VERSION ""

NS_ :

BS_:

BU_: VCM SCIM IC CCM

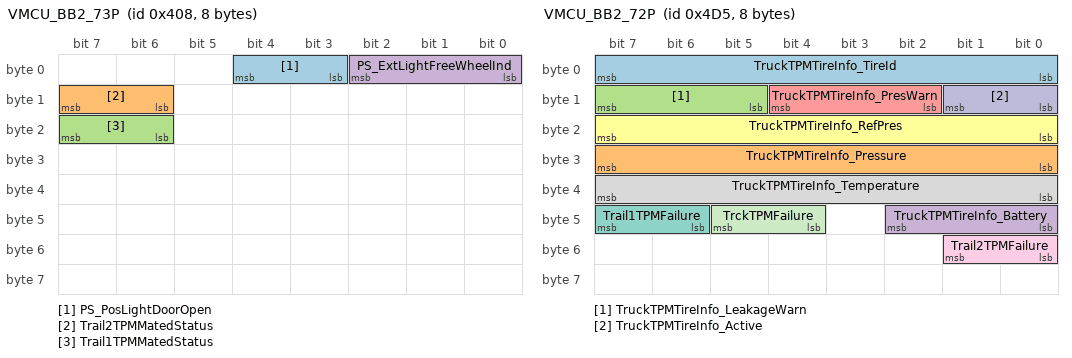
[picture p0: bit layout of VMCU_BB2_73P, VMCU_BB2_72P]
BO_ 1032 VMCU_BB2_73P: 8 VCM
 SG_ PS_PosLightDoorOpen : 3|2@1+ (1,0) [0|0] ""  IC
 SG_ Trail2TPMMatedStatus : 14|2@1+ (1,0) [0|0] ""  IC
 SG_ Trail1TPMMatedStatus : 22|2@1+ (1,0) [0|0] ""  IC
 SG_ PS_ExtLightFreeWheelInd : 0|3@1+ (1,0) [0|0] ""  IC

BO_ 1237 VMCU_BB2_72P: 8 VCM
 SG_ TruckTPMTireInfo_TireId : 0|8@1+ (1,0) [0|255] "NotApplicable"  IC
 SG_ TruckTPMTireInfo_Pressure : 24|8@1+ (10,0) [0|2550] "kPa"  IC
 SG_ TruckTPMTireInfo_LeakageWarn : 13|3@1+ (1,0) [0|0] ""  IC
 SG_ TruckTPMTireInfo_Battery : 40|3@1+ (1,0) [0|0] ""  IC
 SG_ TruckTPMTireInfo_PresWarn : 10|3@1+ (1,0) [0|0] ""  IC
 SG_ TruckTPMTireInfo_RefPres : 16|8@1+ (10,0) [0|2550] "kPa"  IC
 SG_ Trail1TPMFailure : 46|2@1+ (1,0) [0|0] ""  IC
 SG_ TruckTPMTireInfo_Temperature : 32|8@1+ (1,-50) [-50|205] "DegreeC"  IC
 SG_ Trail2TPMFailure : 48|2@1+ (1,0) [0|0] ""  IC
 SG_ TruckTPMTireInfo_Active : 8|2@1+ (1,0) [0|0] ""  IC
 SG_ TrckTPMFailure : 44|2@1+ (1,0) [0|0] ""  IC

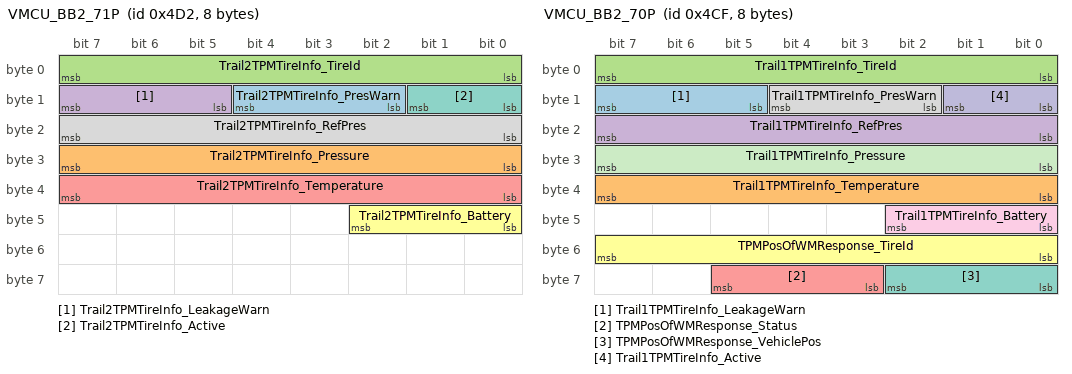
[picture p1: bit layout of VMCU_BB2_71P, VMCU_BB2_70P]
BO_ 1234 VMCU_BB2_71P: 8 VCM
 SG_ Trail2TPMTireInfo_PresWarn : 10|3@1+ (1,0) [0|0] ""  IC
 SG_ Trail2TPMTireInfo_Pressure : 24|8@1+ (10,0) [0|2550] "kPa"  IC
 SG_ Trail2TPMTireInfo_TireId : 0|8@1+ (1,0) [0|255] "NotApplicable"  IC
 SG_ Trail2TPMTireInfo_LeakageWarn : 13|3@1+ (1,0) [0|0] ""  IC
 SG_ Trail2TPMTireInfo_Temperature : 32|8@1+ (1,-50) [-50|205] "DegreeC"  IC
 SG_ Trail2TPMTireInfo_Battery : 40|3@1+ (1,0) [0|0] ""  IC
 SG_ Trail2TPMTireInfo_Active : 8|2@1+ (1,0) [0|0] ""  IC
 SG_ Trail2TPMTireInfo_RefPres : 16|8@1+ (10,0) [0|2550] "kPa"  IC

BO_ 1231 VMCU_BB2_70P: 8 VCM
 SG_ Trail1TPMTireInfo_LeakageWarn : 13|3@1+ (1,0) [0|0] ""  IC
 SG_ Trail1TPMTireInfo_Temperature : 32|8@1+ (1,-50) [-50|205] "DegreeC"  IC
 SG_ Trail1TPMTireInfo_TireId : 0|8@1+ (1,0) [0|255] "NotApplicable"  IC
 SG_ Trail1TPMTireInfo_RefPres : 16|8@1+ (10,0) [0|2550] "kPa"  IC
 SG_ TPMPosOfWMResponse_Status : 59|3@1+ (1,0) [0|0] ""  IC
 SG_ TPMPosOfWMResponse_TireId : 48|8@1+ (1,0) [0|255] "NotApplicable"  IC
 SG_ TPMPosOfWMResponse_VehiclePos : 56|3@1+ (1,0) [0|0] ""  IC
 SG_ Trail1TPMTireInfo_PresWarn : 10|3@1+ (1,0) [0|0] ""  IC
 SG_ Trail1TPMTireInfo_Battery : 40|3@1+ (1,0) [0|0] ""  IC
 SG_ Trail1TPMTireInfo_Active : 8|2@1+ (1,0) [0|0] ""  IC
 SG_ Trail1TPMTireInfo_Pressure : 24|8@1+ (10,0) [0|2550] "kPa"  IC

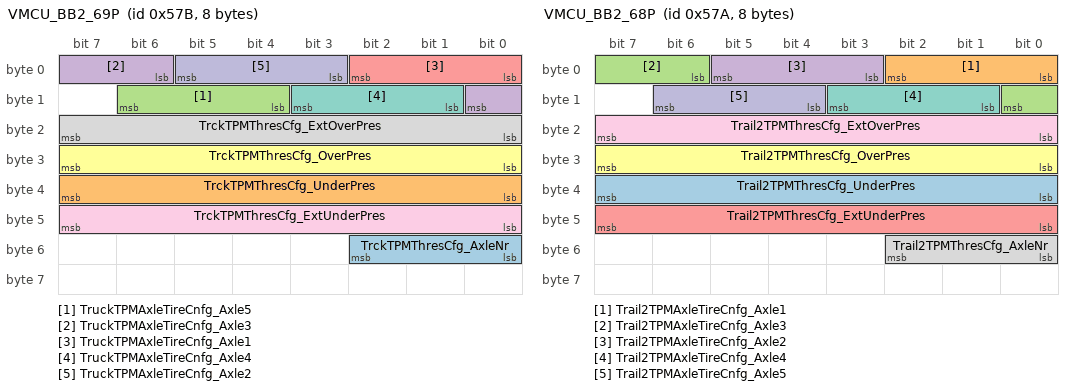
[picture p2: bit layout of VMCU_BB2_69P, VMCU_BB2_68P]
BO_ 1403 VMCU_BB2_69P: 8 VCM
 SG_ TrckTPMThresCfg_AxleNr : 48|3@1+ (1,0) [0|0] ""  IC
 SG_ TrckTPMThresCfg_UnderPres : 32|8@1+ (1,-125) [-125|130] "Percent"  IC
 SG_ TruckTPMAxleTireCnfg_Axle5 : 12|3@1+ (1,0) [0|0] ""  IC
 SG_ TruckTPMAxleTireCnfg_Axle3 : 6|3@1+ (1,0) [0|0] ""  IC
 SG_ TruckTPMAxleTireCnfg_Axle1 : 0|3@1+ (1,0) [0|0] ""  IC
 SG_ TrckTPMThresCfg_OverPres : 24|8@1+ (1,-125) [-125|130] "Percent"  IC
 SG_ TruckTPMAxleTireCnfg_Axle4 : 9|3@1+ (1,0) [0|0] ""  IC
 SG_ TrckTPMThresCfg_ExtOverPres : 16|8@1+ (1,-125) [-125|130] "Percent"  IC
 SG_ TrckTPMThresCfg_ExtUnderPres : 40|8@1+ (1,-125) [-125|130] "Percent"  IC
 SG_ TruckTPMAxleTireCnfg_Axle2 : 3|3@1+ (1,0) [0|0] ""  IC

BO_ 1402 VMCU_BB2_68P: 8 VCM
 SG_ Trail2TPMThresCfg_UnderPres : 32|8@1+ (1,-125) [-125|130] "Percent"  IC
 SG_ Trail2TPMAxleTireCnfg_Axle1 : 0|3@1+ (1,0) [0|0] ""  IC
 SG_ Trail2TPMAxleTireCnfg_Axle3 : 6|3@1+ (1,0) [0|0] ""  IC
 SG_ Trail2TPMAxleTireCnfg_Axle2 : 3|3@1+ (1,0) [0|0] ""  IC
 SG_ Trail2TPMThresCfg_ExtUnderPres : 40|8@1+ (1,-125) [-125|130] "Percent"  IC
 SG_ Trail2TPMThresCfg_OverPres : 24|8@1+ (1,-125) [-125|130] "Percent"  IC
 SG_ Trail2TPMAxleTireCnfg_Axle4 : 9|3@1+ (1,0) [0|0] ""  IC
 SG_ Trail2TPMThresCfg_AxleNr : 48|3@1+ (1,0) [0|0] ""  IC
 SG_ Trail2TPMThresCfg_ExtOverPres : 16|8@1+ (1,-125) [-125|130] "Percent"  IC
 SG_ Trail2TPMAxleTireCnfg_Axle5 : 12|3@1+ (1,0) [0|0] ""  IC

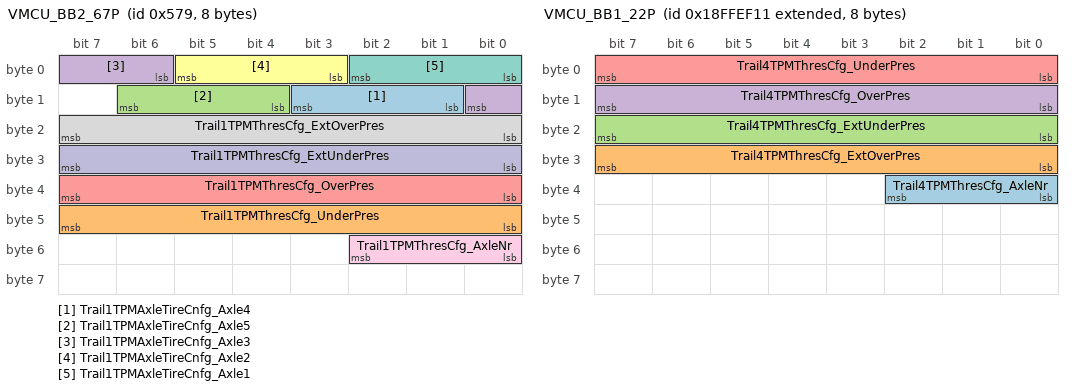
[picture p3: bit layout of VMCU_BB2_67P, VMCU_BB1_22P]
BO_ 1401 VMCU_BB2_67P: 8 VCM
 SG_ Trail1TPMAxleTireCnfg_Axle4 : 9|3@1+ (1,0) [0|0] ""  IC
 SG_ Trail1TPMThresCfg_UnderPres : 40|8@1+ (1,-125) [-125|130] "Percent"  IC
 SG_ Trail1TPMAxleTireCnfg_Axle5 : 12|3@1+ (1,0) [0|0] ""  IC
 SG_ Trail1TPMAxleTireCnfg_Axle3 : 6|3@1+ (1,0) [0|0] ""  IC
 SG_ Trail1TPMThresCfg_OverPres : 32|8@1+ (1,-125) [-125|130] "Percent"  IC
 SG_ Trail1TPMAxleTireCnfg_Axle2 : 3|3@1+ (1,0) [0|0] ""  IC
 SG_ Trail1TPMAxleTireCnfg_Axle1 : 0|3@1+ (1,0) [0|0] ""  IC
 SG_ Trail1TPMThresCfg_ExtOverPres : 16|8@1+ (1,-125) [-125|130] "Percent"  IC
 SG_ Trail1TPMThresCfg_AxleNr : 48|3@1+ (1,0) [0|0] ""  IC
 SG_ Trail1TPMThresCfg_ExtUnderPres : 24|8@1+ (1,-125) [-125|130] "Percent"  IC

BO_ 2566909713 VMCU_BB1_22P: 8 VCM
 SG_ Trail4TPMThresCfg_AxleNr : 32|3@1+ (1,0) [0|0] ""  IC
 SG_ Trail4TPMThresCfg_ExtOverPres : 24|8@1+ (1,-125) [-125|130] "Percent"  IC
 SG_ Trail4TPMThresCfg_ExtUnderPres : 16|8@1+ (1,-125) [-125|130] "Percent"  IC
 SG_ Trail4TPMThresCfg_OverPres : 8|8@1+ (1,-125) [-125|130] "Percent"  IC
 SG_ Trail4TPMThresCfg_UnderPres : 0|8@1+ (1,-125) [-125|130] "Percent"  IC

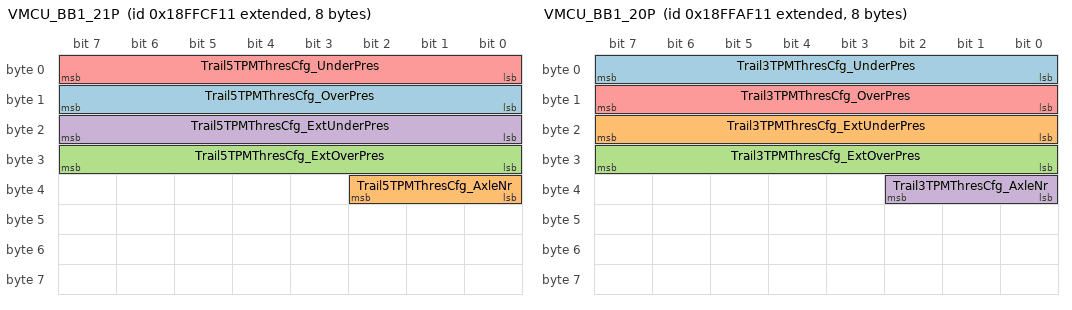
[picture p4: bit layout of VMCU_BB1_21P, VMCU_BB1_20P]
BO_ 2566901521 VMCU_BB1_21P: 8 VCM
 SG_ Trail5TPMThresCfg_OverPres : 8|8@1+ (1,-125) [-125|130] "Percent"  IC
 SG_ Trail5TPMThresCfg_AxleNr : 32|3@1+ (1,0) [0|0] ""  IC
 SG_ Trail5TPMThresCfg_ExtOverPres : 24|8@1+ (1,-125) [-125|130] "Percent"  IC
 SG_ Trail5TPMThresCfg_ExtUnderPres : 16|8@1+ (1,-125) [-125|130] "Percent"  IC
 SG_ Trail5TPMThresCfg_UnderPres : 0|8@1+ (1,-125) [-125|130] "Percent"  IC

BO_ 2566893329 VMCU_BB1_20P: 8 VCM
 SG_ Trail3TPMThresCfg_UnderPres : 0|8@1+ (1,-125) [-125|130] "Percent"  IC
 SG_ Trail3TPMThresCfg_ExtUnderPres : 16|8@1+ (1,-125) [-125|130] "Percent"  IC
 SG_ Trail3TPMThresCfg_ExtOverPres : 24|8@1+ (1,-125) [-125|130] "Percent"  IC
 SG_ Trail3TPMThresCfg_AxleNr : 32|3@1+ (1,0) [0|0] ""  IC
 SG_ Trail3TPMThresCfg_OverPres : 8|8@1+ (1,-125) [-125|130] "Percent"  IC

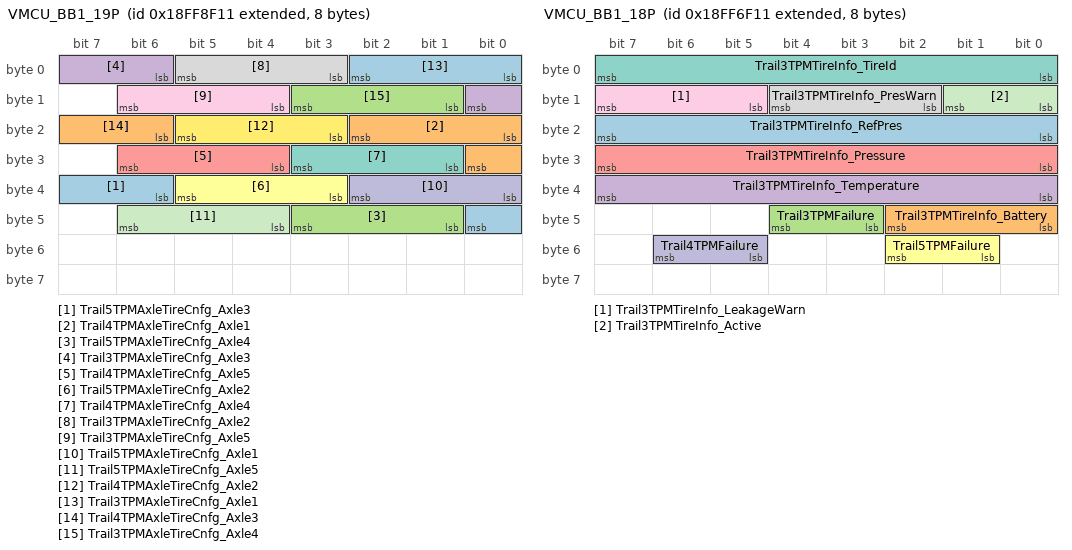
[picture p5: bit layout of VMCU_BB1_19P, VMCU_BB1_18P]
BO_ 2566885137 VMCU_BB1_19P: 8 VCM
 SG_ Trail5TPMAxleTireCnfg_Axle3 : 38|3@1+ (1,0) [0|0] ""  IC
 SG_ Trail4TPMAxleTireCnfg_Axle1 : 16|3@1+ (1,0) [0|0] ""  IC
 SG_ Trail5TPMAxleTireCnfg_Axle4 : 41|3@1+ (1,0) [0|0] ""  IC
 SG_ Trail3TPMAxleTireCnfg_Axle3 : 6|3@1+ (1,0) [0|0] ""  IC
 SG_ Trail4TPMAxleTireCnfg_Axle5 : 28|3@1+ (1,0) [0|0] ""  IC
 SG_ Trail5TPMAxleTireCnfg_Axle2 : 35|3@1+ (1,0) [0|0] ""  IC
 SG_ Trail4TPMAxleTireCnfg_Axle4 : 25|3@1+ (1,0) [0|0] ""  IC
 SG_ Trail3TPMAxleTireCnfg_Axle2 : 3|3@1+ (1,0) [0|0] ""  IC
 SG_ Trail3TPMAxleTireCnfg_Axle5 : 12|3@1+ (1,0) [0|0] ""  IC
 SG_ Trail5TPMAxleTireCnfg_Axle1 : 32|3@1+ (1,0) [0|0] ""  IC
 SG_ Trail5TPMAxleTireCnfg_Axle5 : 44|3@1+ (1,0) [0|0] ""  IC
 SG_ Trail4TPMAxleTireCnfg_Axle2 : 19|3@1+ (1,0) [0|0] ""  IC
 SG_ Trail3TPMAxleTireCnfg_Axle1 : 0|3@1+ (1,0) [0|0] ""  IC
 SG_ Trail4TPMAxleTireCnfg_Axle3 : 22|3@1+ (1,0) [0|0] ""  IC
 SG_ Trail3TPMAxleTireCnfg_Axle4 : 9|3@1+ (1,0) [0|0] ""  IC

BO_ 2566876945 VMCU_BB1_18P: 8 VCM
 SG_ Trail3TPMTireInfo_RefPres : 16|8@1+ (10,0) [0|2550] "kPa"  IC
 SG_ Trail3TPMTireInfo_Battery : 40|3@1+ (1,0) [0|0] ""  IC
 SG_ Trail3TPMFailure : 43|2@1+ (1,0) [0|0] ""  IC
 SG_ Trail3TPMTireInfo_Temperature : 32|8@1+ (1,-50) [-50|205] "DegreeC"  IC
 SG_ Trail3TPMTireInfo_Pressure : 24|8@1+ (10,0) [0|2550] "kPa"  IC
 SG_ Trail5TPMFailure : 49|2@1+ (1,0) [0|0] ""  IC
 SG_ Trail3TPMTireInfo_TireId : 0|8@1+ (1,0) [0|255] "NotApplicable"  IC
 SG_ Trail3TPMTireInfo_PresWarn : 10|3@1+ (1,0) [0|0] ""  IC
 SG_ Trail3TPMTireInfo_LeakageWarn : 13|3@1+ (1,0) [0|0] ""  IC
 SG_ Trail4TPMFailure : 53|2@1+ (1,0) [0|0] ""  IC
 SG_ Trail3TPMTireInfo_Active : 8|2@1+ (1,0) [0|0] ""  IC

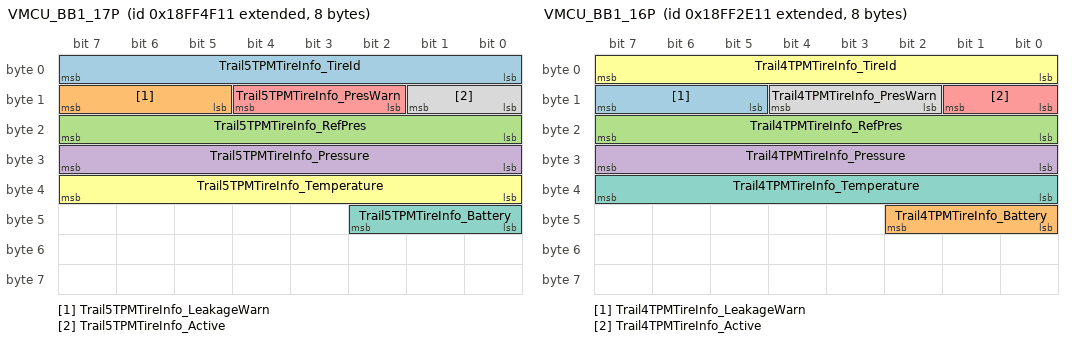
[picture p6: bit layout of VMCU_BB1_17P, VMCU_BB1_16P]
BO_ 2566868753 VMCU_BB1_17P: 8 VCM
 SG_ Trail5TPMTireInfo_TireId : 0|8@1+ (1,0) [0|255] "NotApplicable"  IC
 SG_ Trail5TPMTireInfo_LeakageWarn : 13|3@1+ (1,0) [0|0] ""  IC
 SG_ Trail5TPMTireInfo_RefPres : 16|8@1+ (10,0) [0|2550] "kPa"  IC
 SG_ Trail5TPMTireInfo_Pressure : 24|8@1+ (10,0) [0|2550] "kPa"  IC
 SG_ Trail5TPMTireInfo_PresWarn : 10|3@1+ (1,0) [0|0] ""  IC
 SG_ Trail5TPMTireInfo_Temperature : 32|8@1+ (1,-50) [-50|205] "DegreeC"  IC
 SG_ Trail5TPMTireInfo_Battery : 40|3@1+ (1,0) [0|0] ""  IC
 SG_ Trail5TPMTireInfo_Active : 8|2@1+ (1,0) [0|0] ""  IC

BO_ 2566860305 VMCU_BB1_16P: 8 VCM
 SG_ Trail4TPMTireInfo_LeakageWarn : 13|3@1+ (1,0) [0|0] ""  IC
 SG_ Trail4TPMTireInfo_Battery : 40|3@1+ (1,0) [0|0] ""  IC
 SG_ Trail4TPMTireInfo_RefPres : 16|8@1+ (10,0) [0|2550] "kPa"  IC
 SG_ Trail4TPMTireInfo_Pressure : 24|8@1+ (10,0) [0|2550] "kPa"  IC
 SG_ Trail4TPMTireInfo_Active : 8|2@1+ (1,0) [0|0] ""  IC
 SG_ Trail4TPMTireInfo_TireId : 0|8@1+ (1,0) [0|255] "NotApplicable"  IC
 SG_ Trail4TPMTireInfo_Temperature : 32|8@1+ (1,-50) [-50|205] "DegreeC"  IC
 SG_ Trail4TPMTireInfo_PresWarn : 10|3@1+ (1,0) [0|0] ""  IC

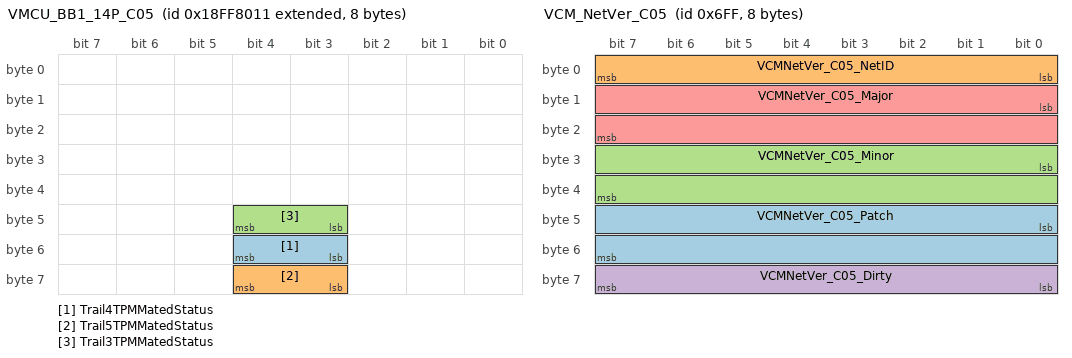
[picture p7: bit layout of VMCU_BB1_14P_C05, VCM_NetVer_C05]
BO_ 2566881297 VMCU_BB1_14P_C05: 8 VCM
 SG_ Trail4TPMMatedStatus : 51|2@1+ (1,0) [0|0] ""  IC
 SG_ Trail5TPMMatedStatus : 59|2@1+ (1,0) [0|0] ""  IC
 SG_ Trail3TPMMatedStatus : 43|2@1+ (1,0) [0|0] ""  IC

BO_ 1791 VCM_NetVer_C05: 8 VCM
 SG_ VCMNetVer_C05_Patch : 40|16@1+ (1,0) [0|65535] "Not Applicable" Vector__XXX
 SG_ VCMNetVer_C05_NetID : 0|8@1+ (1,0) [0|255] "NotApplicable" Vector__XXX
 SG_ VCMNetVer_C05_Minor : 24|16@1+ (1,0) [0|65535] "Not Applicable" Vector__XXX
 SG_ VCMNetVer_C05_Dirty : 56|8@1+ (1,0) [0|255] "NotApplicable" Vector__XXX
 SG_ VCMNetVer_C05_Major : 8|16@1+ (1,0) [0|65535] "Not Applicable" Vector__XXX

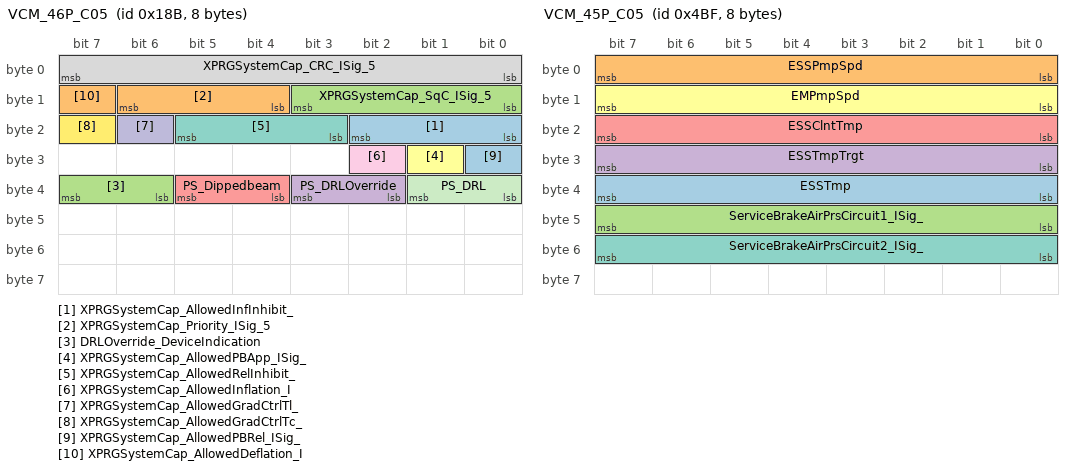
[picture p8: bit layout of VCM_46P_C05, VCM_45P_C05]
BO_ 395 VCM_46P_C05: 8 VCM
 SG_ XPRGSystemCap_AllowedInfInhibit_ : 16|3@1+ (1,0) [0|0] ""  IC
 SG_ XPRGSystemCap_Priority_ISig_5 : 12|3@1+ (1,0) [0|0] ""  IC
 SG_ DRLOverride_DeviceIndication : 38|2@1+ (1,0) [0|0] ""  SCIM
 SG_ PS_DRLOverride : 34|2@1+ (1,0) [0|0] ""  IC
 SG_ PS_Dippedbeam : 36|2@1+ (1,0) [0|0] ""  IC
 SG_ XPRGSystemCap_AllowedPBApp_ISig_ : 25|1@1+ (1,0) [0|0] ""  IC
 SG_ XPRGSystemCap_AllowedRelInhibit_ : 19|3@1+ (1,0) [0|0] ""  IC
 SG_ XPRGSystemCap_CRC_ISig_5 : 0|8@1+ (1,0) [0|255] ""  IC
 SG_ XPRGSystemCap_AllowedInflation_I : 26|1@1+ (1,0) [0|0] ""  IC
 SG_ XPRGSystemCap_AllowedGradCtrlTl_ : 22|1@1+ (1,0) [0|0] ""  IC
 SG_ PS_DRL : 32|2@1+ (1,0) [0|0] ""  IC
 SG_ XPRGSystemCap_AllowedGradCtrlTc_ : 23|1@1+ (1,0) [0|0] ""  IC
 SG_ XPRGSystemCap_AllowedPBRel_ISig_ : 24|1@1+ (1,0) [0|0] ""  IC
 SG_ XPRGSystemCap_AllowedDeflation_I : 15|1@1+ (1,0) [0|0] ""  IC
 SG_ XPRGSystemCap_SqC_ISig_5 : 8|4@1+ (1,0) [0|14] "NotApplicable"  IC

BO_ 1215 VCM_45P_C05: 8 VCM
 SG_ ESSTmp : 32|8@1+ (0.5,-25) [-25|102.5] "DegreeC"  CCM
 SG_ ESSPmpSpd : 0|8@1+ (1,0) [0|255] "Percent"  CCM
 SG_ ServiceBrakeAirPrsCircuit1_ISig_ : 40|8@1+ (8,0) [0|2040] "kPa"  IC
 SG_ ESSTmpTrgt : 24|8@1+ (1,0) [0|255] "DegreeC"  CCM
 SG_ ESSClntTmp : 16|8@1+ (0.5,-25) [-25|102.5] "DegreeC"  CCM
 SG_ EMPmpSpd : 8|8@1+ (1,0) [0|255] "Percent"  CCM
 SG_ ServiceBrakeAirPrsCircuit2_ISig_ : 48|8@1+ (8,0) [0|2040] "kPa"  IC

BO_ 907 VCM_44P_C05: 8 VCM
 SG_ Trailer5GeometricData_Index_ISig : 8|8@1+ (1,0) [0|0] ""  IC
 SG_ Trailer5GeometricData_Content_IS : 0|8@1+ (1,0) [0|255] ""  IC

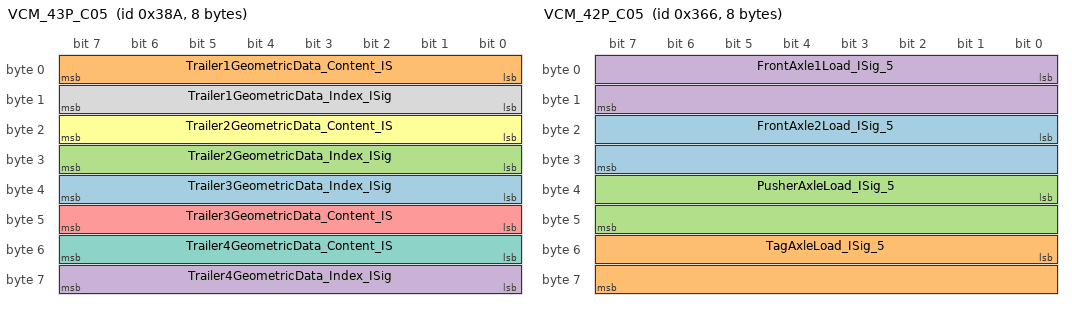
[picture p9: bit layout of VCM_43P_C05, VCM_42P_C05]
BO_ 906 VCM_43P_C05: 8 VCM
 SG_ Trailer3GeometricData_Index_ISig : 32|8@1+ (1,0) [0|0] ""  IC
 SG_ Trailer1GeometricData_Content_IS : 0|8@1+ (1,0) [0|255] ""  IC
 SG_ Trailer2GeometricData_Index_ISig : 24|8@1+ (1,0) [0|0] ""  IC
 SG_ Trailer4GeometricData_Index_ISig : 56|8@1+ (1,0) [0|0] ""  IC
 SG_ Trailer3GeometricData_Content_IS : 40|8@1+ (1,0) [0|255] ""  IC
 SG_ Trailer2GeometricData_Content_IS : 16|8@1+ (1,0) [0|255] ""  IC
 SG_ Trailer4GeometricData_Content_IS : 48|8@1+ (1,0) [0|255] ""  IC
 SG_ Trailer1GeometricData_Index_ISig : 8|8@1+ (1,0) [0|0] ""  IC

BO_ 870 VCM_42P_C05: 8 VCM
 SG_ FrontAxle2Load_ISig_5 : 16|16@1+ (0.5,0) [0|32767.5] "kg"  IC
 SG_ TagAxleLoad_ISig_5 : 48|16@1+ (0.5,0) [0|32767.5] "kg"  IC
 SG_ PusherAxleLoad_ISig_5 : 32|16@1+ (0.5,0) [0|32767.5] "kg"  IC
 SG_ FrontAxle1Load_ISig_5 : 0|16@1+ (0.5,0) [0|32767.5] "kg"  IC

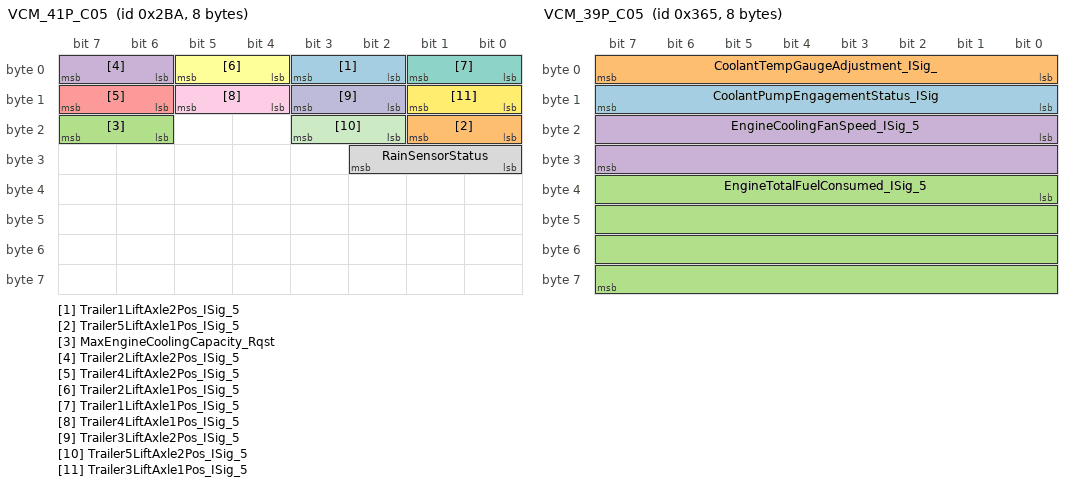
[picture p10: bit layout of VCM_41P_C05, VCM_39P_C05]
BO_ 698 VCM_41P_C05: 8 VCM
 SG_ Trailer1LiftAxle2Pos_ISig_5 : 2|2@1+ (1,0) [0|0] ""  IC
 SG_ Trailer5LiftAxle1Pos_ISig_5 : 16|2@1+ (1,0) [0|0] ""  IC
 SG_ MaxEngineCoolingCapacity_Rqst : 22|2@1+ (1,0) [0|0] ""  IC
 SG_ Trailer2LiftAxle2Pos_ISig_5 : 6|2@1+ (1,0) [0|0] ""  IC
 SG_ Trailer4LiftAxle2Pos_ISig_5 : 14|2@1+ (1,0) [0|0] ""  IC
 SG_ Trailer2LiftAxle1Pos_ISig_5 : 4|2@1+ (1,0) [0|0] ""  IC
 SG_ Trailer1LiftAxle1Pos_ISig_5 : 0|2@1+ (1,0) [0|0] ""  IC
 SG_ RainSensorStatus : 24|3@1+ (1,0) [0|0] ""  IC
 SG_ Trailer4LiftAxle1Pos_ISig_5 : 12|2@1+ (1,0) [0|0] ""  IC
 SG_ Trailer3LiftAxle2Pos_ISig_5 : 10|2@1+ (1,0) [0|0] ""  IC
 SG_ Trailer5LiftAxle2Pos_ISig_5 : 18|2@1+ (1,0) [0|0] ""  IC
 SG_ Trailer3LiftAxle1Pos_ISig_5 : 8|2@1+ (1,0) [0|0] ""  IC

BO_ 157 VCM_40P_C05: 8 VCM
 SG_ ChangeKneelACK_ISig_5 : 16|2@1+ (1,0) [0|0] ""  SCIM
 SG_ InteriorLightDimming_rqst : 43|5@1+ (1,0) [0|0] ""  IC
 SG_ DirectionIndication_cmd : 27|4@1+ (1,0) [0|0] ""  IC
 SG_ RampLevelRequestACK_ISig_5 : 8|2@1+ (1,0) [0|0] ""  SCIM
 SG_ LoadDistributionSelected_ISig_5 : 35|4@1+ (1,0) [0|0] ""  SCIM
 SG_ HeightAdjustmentAllowed_ISig_5 : 12|2@1+ (1,0) [0|0] ""  SCIM
 SG_ AirDumpStatus_ISig_5 : 24|3@1+ (1,0) [0|0] ""  SCIM
 SG_ KneelingStatusHMI_ISig_5 : 4|2@1+ (1,0) [0|0] ""  SCIM
 SG_ BackToDriveReqACK_ISig_5 : 6|2@1+ (1,0) [0|0] ""  SCIM
 SG_ LoadDistributionFuncSelected_ISi : 39|4@1+ (1,0) [0|0] ""  SCIM
 SG_ StopLevelChangeAck_ISig_5 : 14|2@1+ (1,0) [0|0] ""  SCIM
 SG_ RampLevelStorageAck_ISig_5 : 10|2@1+ (1,0) [0|0] ""  SCIM
 SG_ FerryFunctionSwitchChangeACK_ISi : 20|2@1+ (1,0) [0|0] ""  SCIM
 SG_ LiftAxle1RequestResponse : 31|4@1+ (1,0) [0|0] ""  IC
 SG_ ECSStandbyAllowed_ISig_5 : 22|2@1+ (1,0) [0|0] ""  SCIM
 SG_ RideHeightStorageAck_ISig_5 : 18|2@1+ (1,0) [0|0] ""  SCIM
 SG_ IntLightMode_CoreRqst_EventFlag : 3|1@1+ (1,0) [0|0] ""  IC
 SG_ IntLightMode_CoreRqst_IL_Mode : 0|3@1+ (1,0) [0|0] ""  IC

BO_ 869 VCM_39P_C05: 8 VCM
 SG_ CoolantPumpEngagementStatus_ISig : 8|8@1+ (0.4,0) [0|102] "Percent"  CCM
 SG_ CoolantTempGaugeAdjustment_ISig_ : 0|8@1+ (0.4,0) [0|102] "Percent"  IC
 SG_ EngineTotalFuelConsumed_ISig_5 : 32|32@1+ (0.01,0) [0|42949672.95] "l"  IC
 SG_ EngineCoolingFanSpeed_ISig_5 : 16|16@1+ (1,0) [0|65535] "rpm"  CCM

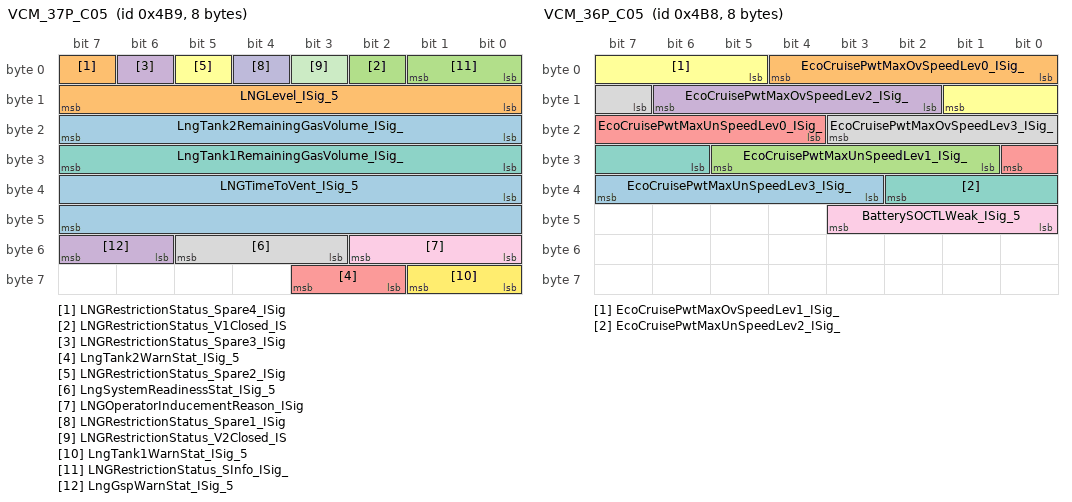
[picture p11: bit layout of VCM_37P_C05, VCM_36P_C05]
BO_ 1209 VCM_37P_C05: 8 VCM
 SG_ LngTank2RemainingGasVolume_ISig_ : 16|8@1+ (0.4,0) [0|102] "Percent"  IC
 SG_ LNGRestrictionStatus_Spare4_ISig : 7|1@1+ (1,0) [0|0] ""  IC
 SG_ LNGRestrictionStatus_V1Closed_IS : 2|1@1+ (1,0) [0|0] ""  IC
 SG_ LNGRestrictionStatus_Spare3_ISig : 6|1@1+ (1,0) [0|0] ""  IC
 SG_ LngTank2WarnStat_ISig_5 : 58|2@1+ (1,0) [0|0] ""  IC
 SG_ LNGRestrictionStatus_Spare2_ISig : 5|1@1+ (1,0) [0|0] ""  IC
 SG_ LngTank1RemainingGasVolume_ISig_ : 24|8@1+ (0.4,0) [0|102] "Percent"  IC
 SG_ LngSystemReadinessStat_ISig_5 : 51|3@1+ (1,0) [0|0] ""  IC
 SG_ LNGOperatorInducementReason_ISig : 48|3@1+ (1,0) [0|0] ""  IC
 SG_ LNGRestrictionStatus_Spare1_ISig : 4|1@1+ (1,0) [0|0] ""  IC
 SG_ LNGRestrictionStatus_V2Closed_IS : 3|1@1+ (1,0) [0|0] ""  IC
 SG_ LngTank1WarnStat_ISig_5 : 56|2@1+ (1,0) [0|0] ""  IC
 SG_ LNGTimeToVent_ISig_5 : 32|16@1+ (1,0) [0|65535] "min"  IC
 SG_ LNGLevel_ISig_5 : 8|8@1+ (0.4,0) [0|102] "Percent"  IC
 SG_ LNGRestrictionStatus_SInfo_ISig_ : 0|2@1+ (1,0) [0|0] ""  IC
 SG_ LngGspWarnStat_ISig_5 : 54|2@1+ (1,0) [0|0] ""  IC

BO_ 1208 VCM_36P_C05: 8 VCM
 SG_ EcoCruisePwtMaxUnSpeedLev3_ISig_ : 35|5@1+ (1,0) [0|31] "Km_per_h"  IC
 SG_ EcoCruisePwtMaxOvSpeedLev0_ISig_ : 0|5@1+ (1,0) [0|31] "Km_per_h"  IC
 SG_ EcoCruisePwtMaxUnSpeedLev1_ISig_ : 25|5@1+ (1,0) [0|31] "Km_per_h"  IC
 SG_ EcoCruisePwtMaxOvSpeedLev2_ISig_ : 10|5@1+ (1,0) [0|31] "Km_per_h"  IC
 SG_ EcoCruisePwtMaxUnSpeedLev0_ISig_ : 20|5@1+ (1,0) [0|31] "Km_per_h"  IC
 SG_ EcoCruisePwtMaxOvSpeedLev1_ISig_ : 5|5@1+ (1,0) [0|31] "Km_per_h"  IC
 SG_ EcoCruisePwtMaxUnSpeedLev2_ISig_ : 30|5@1+ (1,0) [0|31] "Km_per_h"  IC
 SG_ EcoCruisePwtMaxOvSpeedLev3_ISig_ : 15|5@1+ (1,0) [0|31] "Km_per_h"  IC
 SG_ BatterySOCTLWeak_ISig_5 : 40|4@1+ (1,0) [0|0] ""  IC

BO_ 1207 VCM_35P_C05: 8 VCM
 SG_ EngineTotalLngConsumed_ISig_5 : 32|32@1+ (0.01,0) [0|42949672.95] "kg"  IC
 SG_ TotalVehicleDistanceHighRes_ISig : 0|32@1+ (5,0) [0|21474836475] "m"  CCM,IC

BO_ 1206 VCM_34P_C05: 8 VCM
 SG_ PredictedMileageOfNextPadChg_ISi : 0|32@1+ (1,0) [0|4294967295] "km"  IC
 SG_ EngineRunningTime_ISig_5 : 32|32@1+ (1,0) [0|4294967295] "s"  IC

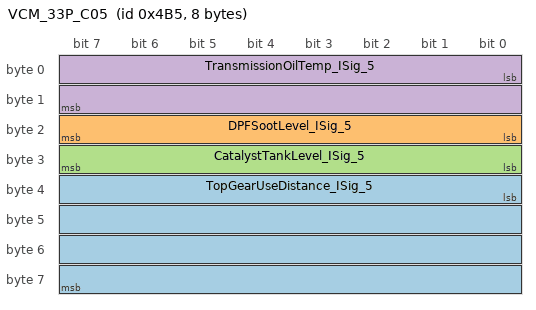
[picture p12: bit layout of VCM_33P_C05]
BO_ 1205 VCM_33P_C05: 8 VCM
 SG_ TopGearUseDistance_ISig_5 : 32|32@1+ (0.01,0) [0|42949672.95] "km"  IC
 SG_ DPFSootLevel_ISig_5 : 16|8@1+ (1,0) [0|255] "Percent"  IC
 SG_ CatalystTankLevel_ISig_5 : 24|8@1+ (0.4,0) [0|102] "Percent"  IC
 SG_ TransmissionOilTemp_ISig_5 : 0|16@1+ (0.03125,-273) [-273|1774.96875] "DegreeC"  IC

CM_ "COM_MATRIX_T3_2.3.0";
CM_ BU_ VCM "Vehicle Control Module";
CM_ BU_ SCIM "Security and Cab Interface Module";
CM_ BU_ IC "Instrument Cluster";
CM_ BU_ CCM "Climate Control Module";
CM_ SG_ 1237 TruckTPMTireInfo_Pressure "251-253 Spare; 254 Error; 255 NotAvailable;";
CM_ SG_ 1237 TruckTPMTireInfo_RefPres "251-253 Spare; 254 Error; 255 NotAvailable;";
CM_ SG_ 1237 TruckTPMTireInfo_Temperature "251-253	Spare; 254 Error; 255 NotAvailable;";
CM_ SG_ 907 Trailer5GeometricData_Content_IS "254 Error ; 255 Not Available";
CM_ SG_ 906 Trailer1GeometricData_Content_IS "254 Error ; 255 Not Available";
CM_ SG_ 906 Trailer3GeometricData_Content_IS "254 Error ; 255 Not Available";
CM_ SG_ 906 Trailer2GeometricData_Content_IS "254 Error ; 255 Not Available";
CM_ SG_ 906 Trailer4GeometricData_Content_IS "254 Error ; 255 Not Available";
BA_DEF_ BO_  "GenMsgStartDelayTime" INT 0 0;
BA_DEF_ BO_  "GenMsgDelayTime" INT 0 0;
BA_DEF_ BO_  "GenMsgCycleTime" INT 0 0;
BA_DEF_ BO_  "GenMsgSendType" ENUM  "Cyclic","NotUsed","NotUsed","NotUsed","NotUsed","NotUsed","NotUsed","IfActive","NoMsgSendType","NotUsed";
BA_DEF_ SG_  "GenSigStartValue" INT 0 0;
BA_DEF_ SG_  "GenSigCycleTimeActive" INT 0 0;
BA_DEF_ SG_  "GenSigCycleTime" INT 0 0;
BA_DEF_ SG_  "GenSigSendType" ENUM  "Cyclic","OnWrite","OnWriteWithRepetition","OnChange","OnChangeWithRepetition","IfActive","IfActiveWithRepetition","NoSigSendType","NotUsed","NotUsed","NotUsed","NotUsed","NotUsed";
BA_DEF_  "Baudrate" INT 0 1000000;
BA_DEF_  "NmType" STRING ;
BA_DEF_  "Manufacturer" STRING ;
BA_DEF_  "VersionYear" INT 0 99;
BA_DEF_  "VersionNumber" INT 0 99;
BA_DEF_  "VersionMonth" INT 1 12;
BA_DEF_  "VersionDay" INT 1 31;
BA_DEF_ BO_  "VFrameFormat" ENUM  "StandardCAN","ExtendedCAN","reserved","J1939PG","reserved","reserved","reserved","reserved","reserved","reserved","reserved","reserved","reserved","reserved","StandardCAN_FD","ExtendedCAN_FD";
BA_DEF_ BU_  "TpOwnSystemEcuNumber" HEX 0 255;
BA_DEF_ SG_  "SigType" ENUM  "Default","Range","RangeSigned","ASCII","Discrete","Control","ReferencePGN","DTC","StringDelimiter","StringLength","StringLengthControl";
BA_DEF_ BU_  "NmStationAddress" INT 0 255;
BA_DEF_  "NmAsrWaitBusSleepTime" INT 0 65535;
BA_DEF_  "NmAsrTimeoutTime" INT 0 65535;
BA_DEF_  "NmAsrRepeatMessageTime" INT 0 65535;
BA_DEF_ BU_  "NmAsrNodeIdentifier" HEX 0 253;
BA_DEF_ BU_  "NmAsrNode" ENUM  "No","Yes";
BA_DEF_  "NmAsrMessageCount" INT 1 256;
BA_DEF_ BO_  "NmAsrMessage" ENUM  "No","Yes";
BA_DEF_  "NmAsrCanMsgCycleTime" INT 0 65535;
BA_DEF_  "NmAsrBaseAddress" HEX 0 536870911;
BA_DEF_ SG_  "NeedsUpdateBit" ENUM  "No","Yes";
BA_DEF_ SG_  "MmAnSignal" ENUM  "No","Yes";
BA_DEF_ BU_  "IsOBDrelevant" ENUM  "No","Yes";
BA_DEF_ SG_  "GenSigMaxLatency" INT 0 65535;
BA_DEF_ SG_  "GenSigILSupport" ENUM  "Yes","No";
BA_DEF_ BO_  "GenMsgILSupport" ENUM  "No","Yes";
BA_DEF_ SG_  "E2EProfile" STRING ;
BA_DEF_  "E2EP05WindowSize" INT 0 65535;
BA_DEF_  "E2EP05ProfileName" STRING ;
BA_DEF_  "E2EP05MinOkStateValid" INT 0 65535;
BA_DEF_  "E2EP05MinOkStateInvalid" INT 0 65535;
BA_DEF_  "E2EP05MinOkStateInit" INT 0 65535;
BA_DEF_  "E2EP05MaxErrorStateValid" INT 0 65535;
BA_DEF_  "E2EP05MaxErrorStateInvalid" INT 0 65535;
BA_DEF_  "E2EP05MaxErrorStateInit" INT 0 65535;
BA_DEF_  "E2EP05MaxDeltaCounter" INT 0 65535;
BA_DEF_  "E2EP01WindowSize" INT 0 65535;
BA_DEF_  "E2EP01SyncCounterInit" INT 0 65535;
BA_DEF_  "E2EP01ProfileName" STRING ;
BA_DEF_  "E2EP01MinOkStateValid" INT 0 65535;
BA_DEF_  "E2EP01MinOkStateInvalid" INT 0 65535;
BA_DEF_  "E2EP01MinOkStateInit" INT 0 65535;
BA_DEF_  "E2EP01MaxNoNewOrRepeatedData" INT 0 65535;
BA_DEF_  "E2EP01MaxErrorStateValid" INT 0 65535;
BA_DEF_  "E2EP01MaxErrorStateInvalid" INT 0 65535;
BA_DEF_  "E2EP01MaxErrorStateInit" INT 0 65535;
BA_DEF_  "E2EP01MaxDeltaCounter" INT 0 65535;
BA_DEF_  "E2EP01DataIdMode" ENUM  "all16Bit","alternating8Bit","lower12Bit","lower8Bit";
BA_DEF_  "E2EP01CounterOffset" INT 0 65535;
BA_DEF_ SG_  "E2EDataLength" INT 0 65535;
BA_DEF_ SG_  "E2EDataId" INT 0 65535;
BA_DEF_ BU_  "DiagnosticClientAddress" HEX 0 255;
BA_DEF_ BO_  "DiagUUDTResponse" ENUM  "No","Yes";
BA_DEF_ BO_  "DiagState" ENUM  "No","Yes";
BA_DEF_ BU_  "DiagRole" ENUM  "None","OBDTester","ExternalTester","InternalTester";
BA_DEF_ BO_  "DiagResponse" ENUM  "No","Yes";
BA_DEF_ BO_  "DiagRequest" ENUM  "No","Yes";
BA_DEF_ BO_  "DiagConnection" HEX 0 65535;
BA_DEF_  "DBName" STRING ;
BA_DEF_ BO_  "CanTpFcFrameId" HEX 0 2147483647;
BA_DEF_ BO_  "CanTpBs" INT 0 255;
BA_DEF_  "BusType" STRING ;
BA_DEF_ SG_  "SystemSignalLongSymbol" STRING ;
BA_DEF_REL_ BU_SG_REL_  "GenSigTimeoutTime" INT 0 65535;
BA_DEF_REL_ BU_SG_REL_  "GenSigFirstTimeoutTime" INT 0 65535;
BA_DEF_DEF_  "GenMsgStartDelayTime" 0;
BA_DEF_DEF_  "GenMsgDelayTime" 0;
BA_DEF_DEF_  "GenMsgCycleTime" 0;
BA_DEF_DEF_  "GenMsgSendType" "Cyclic";
BA_DEF_DEF_  "GenSigStartValue" 0;
BA_DEF_DEF_  "GenSigCycleTimeActive" 0;
BA_DEF_DEF_  "GenSigCycleTime" 0;
BA_DEF_DEF_  "GenSigSendType" "Cyclic";
BA_DEF_DEF_  "Baudrate" 500000;
BA_DEF_DEF_  "NmType" "";
BA_DEF_DEF_  "Manufacturer" "VOLVO_AB";
BA_DEF_DEF_  "VersionYear" 0;
BA_DEF_DEF_  "VersionNumber" 0;
BA_DEF_DEF_  "VersionMonth" 1;
BA_DEF_DEF_  "VersionDay" 1;
BA_DEF_DEF_  "VFrameFormat" "ExtendedCAN";
BA_DEF_DEF_  "TpOwnSystemEcuNumber" 0;
BA_DEF_DEF_  "SigType" "Default";
BA_DEF_DEF_  "NmStationAddress" 254;
BA_DEF_DEF_  "NmAsrWaitBusSleepTime" 750;
BA_DEF_DEF_  "NmAsrTimeoutTime" 5000;
BA_DEF_DEF_  "NmAsrRepeatMessageTime" 300;
BA_DEF_DEF_  "NmAsrNodeIdentifier" 0;
BA_DEF_DEF_  "NmAsrNode" "Yes";
BA_DEF_DEF_  "NmAsrMessageCount" 256;
BA_DEF_DEF_  "NmAsrMessage" "No";
BA_DEF_DEF_  "NmAsrCanMsgCycleTime" 200;
BA_DEF_DEF_  "NmAsrBaseAddress" 486506496;
BA_DEF_DEF_  "NeedsUpdateBit" "No";
BA_DEF_DEF_  "MmAnSignal" "No";
BA_DEF_DEF_  "IsOBDrelevant" "No";
BA_DEF_DEF_  "GenSigMaxLatency" 0;
BA_DEF_DEF_  "GenSigILSupport" "Yes";
BA_DEF_DEF_  "GenMsgILSupport" "Yes";
BA_DEF_DEF_  "E2EProfile" "none";
BA_DEF_DEF_  "E2EP05WindowSize" 5;
BA_DEF_DEF_  "E2EP05ProfileName" "PROFILE_05";
BA_DEF_DEF_  "E2EP05MinOkStateValid" 1;
BA_DEF_DEF_  "E2EP05MinOkStateInvalid" 3;
BA_DEF_DEF_  "E2EP05MinOkStateInit" 1;
BA_DEF_DEF_  "E2EP05MaxErrorStateValid" 3;
BA_DEF_DEF_  "E2EP05MaxErrorStateInvalid" 1;
BA_DEF_DEF_  "E2EP05MaxErrorStateInit" 2;
BA_DEF_DEF_  "E2EP05MaxDeltaCounter" 3;
BA_DEF_DEF_  "E2EP01WindowSize" 5;
BA_DEF_DEF_  "E2EP01SyncCounterInit" 1;
BA_DEF_DEF_  "E2EP01ProfileName" "PROFILE_01";
BA_DEF_DEF_  "E2EP01MinOkStateValid" 1;
BA_DEF_DEF_  "E2EP01MinOkStateInvalid" 3;
BA_DEF_DEF_  "E2EP01MinOkStateInit" 1;
BA_DEF_DEF_  "E2EP01MaxNoNewOrRepeatedData" 5;
BA_DEF_DEF_  "E2EP01MaxErrorStateValid" 3;
BA_DEF_DEF_  "E2EP01MaxErrorStateInvalid" 1;
BA_DEF_DEF_  "E2EP01MaxErrorStateInit" 2;
BA_DEF_DEF_  "E2EP01MaxDeltaCounter" 3;
BA_DEF_DEF_  "E2EP01DataIdMode" "all16Bit";
BA_DEF_DEF_  "E2EP01CounterOffset" 8;
BA_DEF_DEF_  "E2EDataLength" 0;
BA_DEF_DEF_  "E2EDataId" 0;
BA_DEF_DEF_  "DiagnosticClientAddress" 0;
BA_DEF_DEF_  "DiagUUDTResponse" "No";
BA_DEF_DEF_  "DiagState" "No";
BA_DEF_DEF_  "DiagRole" "None";
BA_DEF_DEF_  "DiagResponse" "No";
BA_DEF_DEF_  "DiagRequest" "No";
BA_DEF_DEF_  "DiagConnection" 0;
BA_DEF_DEF_  "DBName" "";
BA_DEF_DEF_  "CanTpFcFrameId" 2147483647;
BA_DEF_DEF_  "CanTpBs" 255;
BA_DEF_DEF_  "BusType" "";
BA_DEF_DEF_REL_ "GenSigTimeoutTime" 0;
BA_DEF_DEF_REL_ "GenSigFirstTimeoutTime" 0;
BA_DEF_DEF_  "SystemSignalLongSymbol" "";
BA_ "NmType" "NmAsr";
BA_ "BusType" "CAN";
BA_ "VersionDay" 27;
BA_ "VersionMonth" 2;
BA_ "VersionNumber" 1;
BA_ "VersionYear" 23;
BA_ "DBName" "CAN05";
BA_ "DiagRole" BU_ VCM 3;
BA_ "DiagnosticClientAddress" BU_ VCM 244;
BA_ "IsOBDrelevant" BU_ VCM 1;
BA_ "TpOwnSystemEcuNumber" BU_ VCM 36;
BA_ "NmAsrNodeIdentifier" BU_ VCM 36;
BA_ "TpOwnSystemEcuNumber" BU_ SCIM 64;
BA_ "NmAsrNodeIdentifier" BU_ SCIM 64;
BA_ "TpOwnSystemEcuNumber" BU_ IC 97;
BA_ "NmAsrNodeIdentifier" BU_ IC 97;
BA_ "TpOwnSystemEcuNumber" BU_ CCM 152;
BA_ "NmAsrNodeIdentifier" BU_ CCM 152;
BA_ "VFrameFormat" BO_ 1032 0;
BA_ "GenMsgCycleTime" BO_ 1032 100;
BA_ "GenMsgStartDelayTime" BO_ 1032 80;
BA_ "VFrameFormat" BO_ 1237 0;
BA_ "GenMsgCycleTime" BO_ 1237 200;
BA_ "GenMsgStartDelayTime" BO_ 1237 100;
BA_ "VFrameFormat" BO_ 1234 0;
BA_ "GenMsgCycleTime" BO_ 1234 200;
BA_ "GenMsgStartDelayTime" BO_ 1234 120;
BA_ "VFrameFormat" BO_ 1231 0;
BA_ "GenMsgCycleTime" BO_ 1231 200;
BA_ "GenMsgStartDelayTime" BO_ 1231 140;
BA_ "VFrameFormat" BO_ 1403 0;
BA_ "GenMsgCycleTime" BO_ 1403 1000;
BA_ "GenMsgStartDelayTime" BO_ 1403 280;
BA_ "VFrameFormat" BO_ 1402 0;
BA_ "GenMsgCycleTime" BO_ 1402 1000;
BA_ "GenMsgStartDelayTime" BO_ 1402 320;
BA_ "VFrameFormat" BO_ 1401 0;
BA_ "GenMsgCycleTime" BO_ 1401 1000;
BA_ "GenMsgStartDelayTime" BO_ 1401 350;
BA_ "GenMsgCycleTime" BO_ 2566909713 1000;
BA_ "GenMsgStartDelayTime" BO_ 2566909713 80;
BA_ "VFrameFormat" BO_ 2566909713 3;
BA_ "GenMsgCycleTime" BO_ 2566901521 1000;
BA_ "GenMsgStartDelayTime" BO_ 2566901521 50;
BA_ "VFrameFormat" BO_ 2566901521 3;
BA_ "GenMsgCycleTime" BO_ 2566893329 1000;
BA_ "GenMsgStartDelayTime" BO_ 2566893329 35;
BA_ "VFrameFormat" BO_ 2566893329 3;
BA_ "GenMsgCycleTime" BO_ 2566885137 500;
BA_ "GenMsgStartDelayTime" BO_ 2566885137 220;
BA_ "VFrameFormat" BO_ 2566885137 3;
BA_ "GenMsgCycleTime" BO_ 2566876945 200;
BA_ "GenMsgStartDelayTime" BO_ 2566876945 90;
BA_ "VFrameFormat" BO_ 2566876945 3;
BA_ "GenMsgCycleTime" BO_ 2566868753 200;
BA_ "GenMsgStartDelayTime" BO_ 2566868753 75;
BA_ "VFrameFormat" BO_ 2566868753 3;
BA_ "GenMsgCycleTime" BO_ 2566860305 200;
BA_ "GenMsgStartDelayTime" BO_ 2566860305 60;
BA_ "VFrameFormat" BO_ 2566860305 3;
BA_ "GenMsgCycleTime" BO_ 2566881297 100;
BA_ "GenMsgStartDelayTime" BO_ 2566881297 50;
BA_ "VFrameFormat" BO_ 2566881297 3;
BA_ "VFrameFormat" BO_ 1791 0;
BA_ "GenMsgCycleTime" BO_ 1791 1000;
BA_ "VFrameFormat" BO_ 395 0;
BA_ "GenMsgCycleTime" BO_ 395 50;
BA_ "GenMsgStartDelayTime" BO_ 395 40;
BA_ "VFrameFormat" BO_ 1215 0;
BA_ "GenMsgCycleTime" BO_ 1215 1000;
BA_ "GenMsgStartDelayTime" BO_ 1215 425;
BA_ "VFrameFormat" BO_ 907 0;
BA_ "GenMsgCycleTime" BO_ 907 500;
BA_ "GenMsgStartDelayTime" BO_ 907 215;
BA_ "VFrameFormat" BO_ 906 0;
BA_ "GenMsgCycleTime" BO_ 906 500;
BA_ "GenMsgStartDelayTime" BO_ 906 160;
BA_ "VFrameFormat" BO_ 870 0;
BA_ "GenMsgCycleTime" BO_ 870 250;
BA_ "GenMsgStartDelayTime" BO_ 870 160;
BA_ "VFrameFormat" BO_ 698 0;
BA_ "GenMsgCycleTime" BO_ 698 100;
BA_ "GenMsgStartDelayTime" BO_ 698 5;
BA_ "VFrameFormat" BO_ 157 0;
BA_ "GenMsgCycleTime" BO_ 157 20;
BA_ "GenMsgStartDelayTime" BO_ 157 15;
BA_ "VFrameFormat" BO_ 869 0;
BA_ "GenMsgCycleTime" BO_ 869 250;
BA_ "GenMsgStartDelayTime" BO_ 869 145;
BA_ "VFrameFormat" BO_ 1209 0;
BA_ "GenMsgCycleTime" BO_ 1209 1000;
BA_ "GenMsgStartDelayTime" BO_ 1209 360;
BA_ "VFrameFormat" BO_ 1208 0;
BA_ "GenMsgCycleTime" BO_ 1208 1000;
BA_ "GenMsgStartDelayTime" BO_ 1208 305;
BA_ "VFrameFormat" BO_ 1207 0;
BA_ "GenMsgCycleTime" BO_ 1207 1000;
BA_ "GenMsgStartDelayTime" BO_ 1207 280;
BA_ "VFrameFormat" BO_ 1206 0;
BA_ "GenMsgCycleTime" BO_ 1206 1000;
BA_ "GenMsgStartDelayTime" BO_ 1206 235;
BA_ "VFrameFormat" BO_ 1205 0;
BA_ "GenMsgCycleTime" BO_ 1205 1000;
BA_ "GenMsgStartDelayTime" BO_ 1205 180;
BA_ "GenSigCycleTime" SG_ 1032 PS_PosLightDoorOpen 100;
BA_ "GenSigCycleTimeActive" SG_ 1032 PS_PosLightDoorOpen 100;
BA_ "GenSigStartValue" SG_ 1032 PS_PosLightDoorOpen 3;
BA_ "GenSigCycleTime" SG_ 1032 Trail2TPMMatedStatus 100;
BA_ "GenSigCycleTimeActive" SG_ 1032 Trail2TPMMatedStatus 100;
BA_ "GenSigStartValue" SG_ 1032 Trail2TPMMatedStatus 3;
BA_ "GenSigCycleTime" SG_ 1032 Trail1TPMMatedStatus 100;
BA_ "GenSigCycleTimeActive" SG_ 1032 Trail1TPMMatedStatus 100;
BA_ "GenSigStartValue" SG_ 1032 Trail1TPMMatedStatus 3;
BA_ "GenSigCycleTime" SG_ 1032 PS_ExtLightFreeWheelInd 100;
BA_ "GenSigCycleTimeActive" SG_ 1032 PS_ExtLightFreeWheelInd 100;
BA_ "GenSigStartValue" SG_ 1032 PS_ExtLightFreeWheelInd 7;
BA_ "GenSigCycleTime" SG_ 1237 TruckTPMTireInfo_TireId 100;
BA_ "GenSigCycleTimeActive" SG_ 1237 TruckTPMTireInfo_TireId 100;
BA_ "GenSigCycleTime" SG_ 1237 TruckTPMTireInfo_Pressure 100;
BA_ "GenSigCycleTimeActive" SG_ 1237 TruckTPMTireInfo_Pressure 100;
BA_ "GenSigStartValue" SG_ 1237 TruckTPMTireInfo_Pressure 255;
BA_ "GenSigCycleTime" SG_ 1237 TruckTPMTireInfo_LeakageWarn 100;
BA_ "GenSigCycleTimeActive" SG_ 1237 TruckTPMTireInfo_LeakageWarn 100;
BA_ "GenSigStartValue" SG_ 1237 TruckTPMTireInfo_LeakageWarn 7;
BA_ "GenSigCycleTime" SG_ 1237 TruckTPMTireInfo_Battery 100;
BA_ "GenSigCycleTimeActive" SG_ 1237 TruckTPMTireInfo_Battery 100;
BA_ "GenSigStartValue" SG_ 1237 TruckTPMTireInfo_Battery 7;
BA_ "GenSigCycleTime" SG_ 1237 TruckTPMTireInfo_PresWarn 100;
BA_ "GenSigCycleTimeActive" SG_ 1237 TruckTPMTireInfo_PresWarn 100;
BA_ "GenSigStartValue" SG_ 1237 TruckTPMTireInfo_PresWarn 7;
BA_ "GenSigCycleTime" SG_ 1237 TruckTPMTireInfo_RefPres 100;
BA_ "GenSigCycleTimeActive" SG_ 1237 TruckTPMTireInfo_RefPres 100;
BA_ "GenSigStartValue" SG_ 1237 TruckTPMTireInfo_RefPres 255;
BA_ "GenSigCycleTime" SG_ 1237 Trail1TPMFailure 100;
BA_ "GenSigCycleTimeActive" SG_ 1237 Trail1TPMFailure 100;
BA_ "GenSigStartValue" SG_ 1237 Trail1TPMFailure 3;
BA_ "GenSigCycleTime" SG_ 1237 TruckTPMTireInfo_Temperature 100;
BA_ "GenSigCycleTimeActive" SG_ 1237 TruckTPMTireInfo_Temperature 100;
BA_ "GenSigStartValue" SG_ 1237 TruckTPMTireInfo_Temperature 255;
BA_ "GenSigCycleTime" SG_ 1237 Trail2TPMFailure 100;
BA_ "GenSigCycleTimeActive" SG_ 1237 Trail2TPMFailure 100;
BA_ "GenSigStartValue" SG_ 1237 Trail2TPMFailure 3;
BA_ "GenSigCycleTime" SG_ 1237 TruckTPMTireInfo_Active 100;
BA_ "GenSigCycleTimeActive" SG_ 1237 TruckTPMTireInfo_Active 100;
BA_ "GenSigStartValue" SG_ 1237 TruckTPMTireInfo_Active 3;
BA_ "GenSigCycleTime" SG_ 1237 TrckTPMFailure 100;
BA_ "GenSigCycleTimeActive" SG_ 1237 TrckTPMFailure 100;
BA_ "GenSigStartValue" SG_ 1237 TrckTPMFailure 3;
BA_ "GenSigCycleTime" SG_ 1234 Trail2TPMTireInfo_PresWarn 100;
BA_ "GenSigCycleTimeActive" SG_ 1234 Trail2TPMTireInfo_PresWarn 100;
BA_ "GenSigStartValue" SG_ 1234 Trail2TPMTireInfo_PresWarn 7;
BA_ "GenSigCycleTime" SG_ 1234 Trail2TPMTireInfo_Pressure 100;
BA_ "GenSigCycleTimeActive" SG_ 1234 Trail2TPMTireInfo_Pressure 100;
BA_ "GenSigStartValue" SG_ 1234 Trail2TPMTireInfo_Pressure 255;
BA_ "GenSigCycleTime" SG_ 1234 Trail2TPMTireInfo_TireId 100;
BA_ "GenSigCycleTimeActive" SG_ 1234 Trail2TPMTireInfo_TireId 100;
BA_ "GenSigCycleTime" SG_ 1234 Trail2TPMTireInfo_LeakageWarn 100;
BA_ "GenSigCycleTimeActive" SG_ 1234 Trail2TPMTireInfo_LeakageWarn 100;
BA_ "GenSigStartValue" SG_ 1234 Trail2TPMTireInfo_LeakageWarn 7;
BA_ "GenSigCycleTime" SG_ 1234 Trail2TPMTireInfo_Temperature 100;
BA_ "GenSigCycleTimeActive" SG_ 1234 Trail2TPMTireInfo_Temperature 100;
BA_ "GenSigStartValue" SG_ 1234 Trail2TPMTireInfo_Temperature 255;
BA_ "GenSigCycleTime" SG_ 1234 Trail2TPMTireInfo_Battery 100;
BA_ "GenSigCycleTimeActive" SG_ 1234 Trail2TPMTireInfo_Battery 100;
BA_ "GenSigStartValue" SG_ 1234 Trail2TPMTireInfo_Battery 7;
BA_ "GenSigCycleTime" SG_ 1234 Trail2TPMTireInfo_Active 100;
BA_ "GenSigCycleTimeActive" SG_ 1234 Trail2TPMTireInfo_Active 100;
BA_ "GenSigStartValue" SG_ 1234 Trail2TPMTireInfo_Active 3;
BA_ "GenSigCycleTime" SG_ 1234 Trail2TPMTireInfo_RefPres 100;
BA_ "GenSigCycleTimeActive" SG_ 1234 Trail2TPMTireInfo_RefPres 100;
BA_ "GenSigStartValue" SG_ 1234 Trail2TPMTireInfo_RefPres 255;
BA_ "GenSigCycleTime" SG_ 1231 Trail1TPMTireInfo_LeakageWarn 100;
BA_ "GenSigCycleTimeActive" SG_ 1231 Trail1TPMTireInfo_LeakageWarn 100;
BA_ "GenSigStartValue" SG_ 1231 Trail1TPMTireInfo_LeakageWarn 7;
BA_ "GenSigCycleTime" SG_ 1231 Trail1TPMTireInfo_Temperature 100;
BA_ "GenSigCycleTimeActive" SG_ 1231 Trail1TPMTireInfo_Temperature 100;
BA_ "GenSigStartValue" SG_ 1231 Trail1TPMTireInfo_Temperature 255;
BA_ "GenSigCycleTime" SG_ 1231 Trail1TPMTireInfo_TireId 100;
BA_ "GenSigCycleTimeActive" SG_ 1231 Trail1TPMTireInfo_TireId 100;
BA_ "GenSigCycleTime" SG_ 1231 Trail1TPMTireInfo_RefPres 100;
BA_ "GenSigCycleTimeActive" SG_ 1231 Trail1TPMTireInfo_RefPres 100;
BA_ "GenSigStartValue" SG_ 1231 Trail1TPMTireInfo_RefPres 255;
BA_ "GenSigCycleTime" SG_ 1231 TPMPosOfWMResponse_Status 100;
BA_ "GenSigCycleTimeActive" SG_ 1231 TPMPosOfWMResponse_Status 100;
BA_ "GenSigStartValue" SG_ 1231 TPMPosOfWMResponse_Status 7;
BA_ "GenSigCycleTime" SG_ 1231 TPMPosOfWMResponse_TireId 100;
BA_ "GenSigCycleTimeActive" SG_ 1231 TPMPosOfWMResponse_TireId 100;
BA_ "GenSigStartValue" SG_ 1231 TPMPosOfWMResponse_TireId 255;
BA_ "GenSigCycleTime" SG_ 1231 TPMPosOfWMResponse_VehiclePos 100;
BA_ "GenSigCycleTimeActive" SG_ 1231 TPMPosOfWMResponse_VehiclePos 100;
BA_ "GenSigStartValue" SG_ 1231 TPMPosOfWMResponse_VehiclePos 7;
BA_ "GenSigCycleTime" SG_ 1231 Trail1TPMTireInfo_PresWarn 100;
BA_ "GenSigCycleTimeActive" SG_ 1231 Trail1TPMTireInfo_PresWarn 100;
BA_ "GenSigStartValue" SG_ 1231 Trail1TPMTireInfo_PresWarn 7;
BA_ "GenSigCycleTime" SG_ 1231 Trail1TPMTireInfo_Battery 100;
BA_ "GenSigCycleTimeActive" SG_ 1231 Trail1TPMTireInfo_Battery 100;
BA_ "GenSigStartValue" SG_ 1231 Trail1TPMTireInfo_Battery 7;
BA_ "GenSigCycleTime" SG_ 1231 Trail1TPMTireInfo_Active 100;
BA_ "GenSigCycleTimeActive" SG_ 1231 Trail1TPMTireInfo_Active 100;
BA_ "GenSigStartValue" SG_ 1231 Trail1TPMTireInfo_Active 3;
BA_ "GenSigCycleTime" SG_ 1231 Trail1TPMTireInfo_Pressure 100;
BA_ "GenSigCycleTimeActive" SG_ 1231 Trail1TPMTireInfo_Pressure 100;
BA_ "GenSigStartValue" SG_ 1231 Trail1TPMTireInfo_Pressure 255;
BA_ "GenSigCycleTime" SG_ 1403 TrckTPMThresCfg_AxleNr 100;
BA_ "GenSigCycleTimeActive" SG_ 1403 TrckTPMThresCfg_AxleNr 100;
BA_ "GenSigStartValue" SG_ 1403 TrckTPMThresCfg_AxleNr 7;
BA_ "GenSigCycleTime" SG_ 1403 TrckTPMThresCfg_UnderPres 100;
BA_ "GenSigCycleTimeActive" SG_ 1403 TrckTPMThresCfg_UnderPres 100;
BA_ "GenSigStartValue" SG_ 1403 TrckTPMThresCfg_UnderPres 255;
BA_ "GenSigCycleTime" SG_ 1403 TruckTPMAxleTireCnfg_Axle5 100;
BA_ "GenSigCycleTimeActive" SG_ 1403 TruckTPMAxleTireCnfg_Axle5 100;
BA_ "GenSigStartValue" SG_ 1403 TruckTPMAxleTireCnfg_Axle5 7;
BA_ "GenSigCycleTime" SG_ 1403 TruckTPMAxleTireCnfg_Axle3 100;
BA_ "GenSigCycleTimeActive" SG_ 1403 TruckTPMAxleTireCnfg_Axle3 100;
BA_ "GenSigStartValue" SG_ 1403 TruckTPMAxleTireCnfg_Axle3 7;
BA_ "GenSigCycleTime" SG_ 1403 TruckTPMAxleTireCnfg_Axle1 100;
BA_ "GenSigCycleTimeActive" SG_ 1403 TruckTPMAxleTireCnfg_Axle1 100;
BA_ "GenSigStartValue" SG_ 1403 TruckTPMAxleTireCnfg_Axle1 7;
BA_ "GenSigCycleTime" SG_ 1403 TrckTPMThresCfg_OverPres 100;
BA_ "GenSigCycleTimeActive" SG_ 1403 TrckTPMThresCfg_OverPres 100;
BA_ "GenSigStartValue" SG_ 1403 TrckTPMThresCfg_OverPres 255;
BA_ "GenSigCycleTime" SG_ 1403 TruckTPMAxleTireCnfg_Axle4 100;
BA_ "GenSigCycleTimeActive" SG_ 1403 TruckTPMAxleTireCnfg_Axle4 100;
BA_ "GenSigStartValue" SG_ 1403 TruckTPMAxleTireCnfg_Axle4 7;
BA_ "GenSigCycleTime" SG_ 1403 TrckTPMThresCfg_ExtOverPres 100;
BA_ "GenSigCycleTimeActive" SG_ 1403 TrckTPMThresCfg_ExtOverPres 100;
BA_ "GenSigStartValue" SG_ 1403 TrckTPMThresCfg_ExtOverPres 255;
BA_ "GenSigCycleTime" SG_ 1403 TrckTPMThresCfg_ExtUnderPres 100;
BA_ "GenSigCycleTimeActive" SG_ 1403 TrckTPMThresCfg_ExtUnderPres 100;
BA_ "GenSigStartValue" SG_ 1403 TrckTPMThresCfg_ExtUnderPres 255;
BA_ "GenSigCycleTime" SG_ 1403 TruckTPMAxleTireCnfg_Axle2 100;
BA_ "GenSigCycleTimeActive" SG_ 1403 TruckTPMAxleTireCnfg_Axle2 100;
BA_ "GenSigStartValue" SG_ 1403 TruckTPMAxleTireCnfg_Axle2 7;
BA_ "GenSigCycleTime" SG_ 1402 Trail2TPMThresCfg_UnderPres 100;
BA_ "GenSigCycleTimeActive" SG_ 1402 Trail2TPMThresCfg_UnderPres 100;
BA_ "GenSigStartValue" SG_ 1402 Trail2TPMThresCfg_UnderPres 255;
BA_ "GenSigCycleTime" SG_ 1402 Trail2TPMAxleTireCnfg_Axle1 100;
BA_ "GenSigCycleTimeActive" SG_ 1402 Trail2TPMAxleTireCnfg_Axle1 100;
BA_ "GenSigStartValue" SG_ 1402 Trail2TPMAxleTireCnfg_Axle1 7;
BA_ "GenSigCycleTime" SG_ 1402 Trail2TPMAxleTireCnfg_Axle3 100;
BA_ "GenSigCycleTimeActive" SG_ 1402 Trail2TPMAxleTireCnfg_Axle3 100;
BA_ "GenSigStartValue" SG_ 1402 Trail2TPMAxleTireCnfg_Axle3 7;
BA_ "GenSigCycleTime" SG_ 1402 Trail2TPMAxleTireCnfg_Axle2 100;
BA_ "GenSigCycleTimeActive" SG_ 1402 Trail2TPMAxleTireCnfg_Axle2 100;
BA_ "GenSigStartValue" SG_ 1402 Trail2TPMAxleTireCnfg_Axle2 7;
BA_ "GenSigCycleTime" SG_ 1402 Trail2TPMThresCfg_ExtUnderPres 100;
BA_ "GenSigCycleTimeActive" SG_ 1402 Trail2TPMThresCfg_ExtUnderPres 100;
BA_ "GenSigStartValue" SG_ 1402 Trail2TPMThresCfg_ExtUnderPres 255;
BA_ "GenSigCycleTime" SG_ 1402 Trail2TPMThresCfg_OverPres 100;
BA_ "GenSigCycleTimeActive" SG_ 1402 Trail2TPMThresCfg_OverPres 100;
BA_ "GenSigStartValue" SG_ 1402 Trail2TPMThresCfg_OverPres 255;
BA_ "GenSigCycleTime" SG_ 1402 Trail2TPMAxleTireCnfg_Axle4 100;
BA_ "GenSigCycleTimeActive" SG_ 1402 Trail2TPMAxleTireCnfg_Axle4 100;
BA_ "GenSigStartValue" SG_ 1402 Trail2TPMAxleTireCnfg_Axle4 7;
BA_ "GenSigCycleTime" SG_ 1402 Trail2TPMThresCfg_AxleNr 100;
BA_ "GenSigCycleTimeActive" SG_ 1402 Trail2TPMThresCfg_AxleNr 100;
BA_ "GenSigStartValue" SG_ 1402 Trail2TPMThresCfg_AxleNr 7;
BA_ "GenSigCycleTime" SG_ 1402 Trail2TPMThresCfg_ExtOverPres 100;
BA_ "GenSigCycleTimeActive" SG_ 1402 Trail2TPMThresCfg_ExtOverPres 100;
BA_ "GenSigStartValue" SG_ 1402 Trail2TPMThresCfg_ExtOverPres 255;
BA_ "GenSigCycleTime" SG_ 1402 Trail2TPMAxleTireCnfg_Axle5 100;
BA_ "GenSigCycleTimeActive" SG_ 1402 Trail2TPMAxleTireCnfg_Axle5 100;
BA_ "GenSigStartValue" SG_ 1402 Trail2TPMAxleTireCnfg_Axle5 7;
BA_ "GenSigCycleTime" SG_ 1401 Trail1TPMAxleTireCnfg_Axle4 100;
BA_ "GenSigCycleTimeActive" SG_ 1401 Trail1TPMAxleTireCnfg_Axle4 100;
BA_ "GenSigStartValue" SG_ 1401 Trail1TPMAxleTireCnfg_Axle4 7;
BA_ "GenSigCycleTime" SG_ 1401 Trail1TPMThresCfg_UnderPres 100;
BA_ "GenSigCycleTimeActive" SG_ 1401 Trail1TPMThresCfg_UnderPres 100;
BA_ "GenSigStartValue" SG_ 1401 Trail1TPMThresCfg_UnderPres 255;
BA_ "GenSigCycleTime" SG_ 1401 Trail1TPMAxleTireCnfg_Axle5 100;
BA_ "GenSigCycleTimeActive" SG_ 1401 Trail1TPMAxleTireCnfg_Axle5 100;
BA_ "GenSigStartValue" SG_ 1401 Trail1TPMAxleTireCnfg_Axle5 7;
BA_ "GenSigCycleTime" SG_ 1401 Trail1TPMAxleTireCnfg_Axle3 100;
BA_ "GenSigCycleTimeActive" SG_ 1401 Trail1TPMAxleTireCnfg_Axle3 100;
BA_ "GenSigStartValue" SG_ 1401 Trail1TPMAxleTireCnfg_Axle3 7;
BA_ "GenSigCycleTime" SG_ 1401 Trail1TPMThresCfg_OverPres 100;
BA_ "GenSigCycleTimeActive" SG_ 1401 Trail1TPMThresCfg_OverPres 100;
BA_ "GenSigStartValue" SG_ 1401 Trail1TPMThresCfg_OverPres 255;
BA_ "GenSigCycleTime" SG_ 1401 Trail1TPMAxleTireCnfg_Axle2 100;
BA_ "GenSigCycleTimeActive" SG_ 1401 Trail1TPMAxleTireCnfg_Axle2 100;
BA_ "GenSigStartValue" SG_ 1401 Trail1TPMAxleTireCnfg_Axle2 7;
BA_ "GenSigCycleTime" SG_ 1401 Trail1TPMAxleTireCnfg_Axle1 100;
BA_ "GenSigCycleTimeActive" SG_ 1401 Trail1TPMAxleTireCnfg_Axle1 100;
BA_ "GenSigStartValue" SG_ 1401 Trail1TPMAxleTireCnfg_Axle1 7;
BA_ "GenSigCycleTime" SG_ 1401 Trail1TPMThresCfg_ExtOverPres 100;
BA_ "GenSigCycleTimeActive" SG_ 1401 Trail1TPMThresCfg_ExtOverPres 100;
BA_ "GenSigStartValue" SG_ 1401 Trail1TPMThresCfg_ExtOverPres 255;
BA_ "GenSigCycleTime" SG_ 1401 Trail1TPMThresCfg_AxleNr 100;
BA_ "GenSigCycleTimeActive" SG_ 1401 Trail1TPMThresCfg_AxleNr 100;
BA_ "GenSigStartValue" SG_ 1401 Trail1TPMThresCfg_AxleNr 7;
BA_ "GenSigCycleTime" SG_ 1401 Trail1TPMThresCfg_ExtUnderPres 100;
BA_ "GenSigCycleTimeActive" SG_ 1401 Trail1TPMThresCfg_ExtUnderPres 100;
BA_ "GenSigStartValue" SG_ 1401 Trail1TPMThresCfg_ExtUnderPres 255;
BA_ "GenSigCycleTime" SG_ 2566909713 Trail4TPMThresCfg_AxleNr 100;
BA_ "GenSigCycleTimeActive" SG_ 2566909713 Trail4TPMThresCfg_AxleNr 100;
BA_ "GenSigStartValue" SG_ 2566909713 Trail4TPMThresCfg_AxleNr 7;
BA_ "GenSigCycleTime" SG_ 2566909713 Trail4TPMThresCfg_ExtOverPres 100;
BA_ "GenSigCycleTimeActive" SG_ 2566909713 Trail4TPMThresCfg_ExtOverPres 100;
BA_ "GenSigStartValue" SG_ 2566909713 Trail4TPMThresCfg_ExtOverPres 255;
BA_ "GenSigCycleTime" SG_ 2566909713 Trail4TPMThresCfg_ExtUnderPres 100;
BA_ "GenSigCycleTimeActive" SG_ 2566909713 Trail4TPMThresCfg_ExtUnderPres 100;
BA_ "GenSigStartValue" SG_ 2566909713 Trail4TPMThresCfg_ExtUnderPres 255;
BA_ "GenSigCycleTime" SG_ 2566909713 Trail4TPMThresCfg_OverPres 100;
BA_ "GenSigCycleTimeActive" SG_ 2566909713 Trail4TPMThresCfg_OverPres 100;
BA_ "GenSigStartValue" SG_ 2566909713 Trail4TPMThresCfg_OverPres 255;
BA_ "GenSigCycleTime" SG_ 2566909713 Trail4TPMThresCfg_UnderPres 100;
BA_ "GenSigCycleTimeActive" SG_ 2566909713 Trail4TPMThresCfg_UnderPres 100;
BA_ "GenSigStartValue" SG_ 2566909713 Trail4TPMThresCfg_UnderPres 255;
BA_ "GenSigCycleTime" SG_ 2566901521 Trail5TPMThresCfg_OverPres 100;
BA_ "GenSigCycleTimeActive" SG_ 2566901521 Trail5TPMThresCfg_OverPres 100;
BA_ "GenSigStartValue" SG_ 2566901521 Trail5TPMThresCfg_OverPres 255;
BA_ "GenSigCycleTime" SG_ 2566901521 Trail5TPMThresCfg_AxleNr 100;
BA_ "GenSigCycleTimeActive" SG_ 2566901521 Trail5TPMThresCfg_AxleNr 100;
BA_ "GenSigStartValue" SG_ 2566901521 Trail5TPMThresCfg_AxleNr 7;
BA_ "GenSigCycleTime" SG_ 2566901521 Trail5TPMThresCfg_ExtOverPres 100;
BA_ "GenSigCycleTimeActive" SG_ 2566901521 Trail5TPMThresCfg_ExtOverPres 100;
BA_ "GenSigStartValue" SG_ 2566901521 Trail5TPMThresCfg_ExtOverPres 255;
BA_ "GenSigCycleTime" SG_ 2566901521 Trail5TPMThresCfg_ExtUnderPres 100;
BA_ "GenSigCycleTimeActive" SG_ 2566901521 Trail5TPMThresCfg_ExtUnderPres 100;
BA_ "GenSigStartValue" SG_ 2566901521 Trail5TPMThresCfg_ExtUnderPres 255;
BA_ "GenSigCycleTime" SG_ 2566901521 Trail5TPMThresCfg_UnderPres 100;
BA_ "GenSigCycleTimeActive" SG_ 2566901521 Trail5TPMThresCfg_UnderPres 100;
BA_ "GenSigStartValue" SG_ 2566901521 Trail5TPMThresCfg_UnderPres 255;
BA_ "GenSigCycleTime" SG_ 2566893329 Trail3TPMThresCfg_UnderPres 100;
BA_ "GenSigCycleTimeActive" SG_ 2566893329 Trail3TPMThresCfg_UnderPres 100;
BA_ "GenSigStartValue" SG_ 2566893329 Trail3TPMThresCfg_UnderPres 255;
BA_ "GenSigCycleTime" SG_ 2566893329 Trail3TPMThresCfg_ExtUnderPres 100;
BA_ "GenSigCycleTimeActive" SG_ 2566893329 Trail3TPMThresCfg_ExtUnderPres 100;
BA_ "GenSigStartValue" SG_ 2566893329 Trail3TPMThresCfg_ExtUnderPres 255;
BA_ "GenSigCycleTime" SG_ 2566893329 Trail3TPMThresCfg_ExtOverPres 100;
BA_ "GenSigCycleTimeActive" SG_ 2566893329 Trail3TPMThresCfg_ExtOverPres 100;
BA_ "GenSigStartValue" SG_ 2566893329 Trail3TPMThresCfg_ExtOverPres 255;
BA_ "GenSigCycleTime" SG_ 2566893329 Trail3TPMThresCfg_AxleNr 100;
BA_ "GenSigCycleTimeActive" SG_ 2566893329 Trail3TPMThresCfg_AxleNr 100;
BA_ "GenSigStartValue" SG_ 2566893329 Trail3TPMThresCfg_AxleNr 7;
BA_ "GenSigCycleTime" SG_ 2566893329 Trail3TPMThresCfg_OverPres 100;
BA_ "GenSigCycleTimeActive" SG_ 2566893329 Trail3TPMThresCfg_OverPres 100;
BA_ "GenSigStartValue" SG_ 2566893329 Trail3TPMThresCfg_OverPres 255;
BA_ "GenSigCycleTime" SG_ 2566885137 Trail5TPMAxleTireCnfg_Axle3 100;
BA_ "GenSigCycleTimeActive" SG_ 2566885137 Trail5TPMAxleTireCnfg_Axle3 100;
BA_ "GenSigStartValue" SG_ 2566885137 Trail5TPMAxleTireCnfg_Axle3 7;
BA_ "GenSigCycleTime" SG_ 2566885137 Trail4TPMAxleTireCnfg_Axle1 100;
BA_ "GenSigCycleTimeActive" SG_ 2566885137 Trail4TPMAxleTireCnfg_Axle1 100;
BA_ "GenSigStartValue" SG_ 2566885137 Trail4TPMAxleTireCnfg_Axle1 7;
BA_ "GenSigCycleTime" SG_ 2566885137 Trail5TPMAxleTireCnfg_Axle4 100;
BA_ "GenSigCycleTimeActive" SG_ 2566885137 Trail5TPMAxleTireCnfg_Axle4 100;
BA_ "GenSigStartValue" SG_ 2566885137 Trail5TPMAxleTireCnfg_Axle4 7;
BA_ "GenSigCycleTime" SG_ 2566885137 Trail3TPMAxleTireCnfg_Axle3 100;
BA_ "GenSigCycleTimeActive" SG_ 2566885137 Trail3TPMAxleTireCnfg_Axle3 100;
BA_ "GenSigStartValue" SG_ 2566885137 Trail3TPMAxleTireCnfg_Axle3 7;
BA_ "GenSigCycleTime" SG_ 2566885137 Trail4TPMAxleTireCnfg_Axle5 100;
BA_ "GenSigCycleTimeActive" SG_ 2566885137 Trail4TPMAxleTireCnfg_Axle5 100;
BA_ "GenSigStartValue" SG_ 2566885137 Trail4TPMAxleTireCnfg_Axle5 7;
BA_ "GenSigCycleTime" SG_ 2566885137 Trail5TPMAxleTireCnfg_Axle2 100;
BA_ "GenSigCycleTimeActive" SG_ 2566885137 Trail5TPMAxleTireCnfg_Axle2 100;
BA_ "GenSigStartValue" SG_ 2566885137 Trail5TPMAxleTireCnfg_Axle2 7;
BA_ "GenSigCycleTime" SG_ 2566885137 Trail4TPMAxleTireCnfg_Axle4 100;
BA_ "GenSigCycleTimeActive" SG_ 2566885137 Trail4TPMAxleTireCnfg_Axle4 100;
BA_ "GenSigStartValue" SG_ 2566885137 Trail4TPMAxleTireCnfg_Axle4 7;
BA_ "GenSigCycleTime" SG_ 2566885137 Trail3TPMAxleTireCnfg_Axle2 100;
BA_ "GenSigCycleTimeActive" SG_ 2566885137 Trail3TPMAxleTireCnfg_Axle2 100;
BA_ "GenSigStartValue" SG_ 2566885137 Trail3TPMAxleTireCnfg_Axle2 7;
BA_ "GenSigCycleTime" SG_ 2566885137 Trail3TPMAxleTireCnfg_Axle5 100;
BA_ "GenSigCycleTimeActive" SG_ 2566885137 Trail3TPMAxleTireCnfg_Axle5 100;
BA_ "GenSigStartValue" SG_ 2566885137 Trail3TPMAxleTireCnfg_Axle5 7;
BA_ "GenSigCycleTime" SG_ 2566885137 Trail5TPMAxleTireCnfg_Axle1 100;
BA_ "GenSigCycleTimeActive" SG_ 2566885137 Trail5TPMAxleTireCnfg_Axle1 100;
BA_ "GenSigStartValue" SG_ 2566885137 Trail5TPMAxleTireCnfg_Axle1 7;
BA_ "GenSigCycleTime" SG_ 2566885137 Trail5TPMAxleTireCnfg_Axle5 100;
BA_ "GenSigCycleTimeActive" SG_ 2566885137 Trail5TPMAxleTireCnfg_Axle5 100;
BA_ "GenSigStartValue" SG_ 2566885137 Trail5TPMAxleTireCnfg_Axle5 7;
BA_ "GenSigCycleTime" SG_ 2566885137 Trail4TPMAxleTireCnfg_Axle2 100;
BA_ "GenSigCycleTimeActive" SG_ 2566885137 Trail4TPMAxleTireCnfg_Axle2 100;
BA_ "GenSigStartValue" SG_ 2566885137 Trail4TPMAxleTireCnfg_Axle2 7;
BA_ "GenSigCycleTime" SG_ 2566885137 Trail3TPMAxleTireCnfg_Axle1 100;
BA_ "GenSigCycleTimeActive" SG_ 2566885137 Trail3TPMAxleTireCnfg_Axle1 100;
BA_ "GenSigStartValue" SG_ 2566885137 Trail3TPMAxleTireCnfg_Axle1 7;
BA_ "GenSigCycleTime" SG_ 2566885137 Trail4TPMAxleTireCnfg_Axle3 100;
BA_ "GenSigCycleTimeActive" SG_ 2566885137 Trail4TPMAxleTireCnfg_Axle3 100;
BA_ "GenSigStartValue" SG_ 2566885137 Trail4TPMAxleTireCnfg_Axle3 7;
BA_ "GenSigCycleTime" SG_ 2566885137 Trail3TPMAxleTireCnfg_Axle4 100;
BA_ "GenSigCycleTimeActive" SG_ 2566885137 Trail3TPMAxleTireCnfg_Axle4 100;
BA_ "GenSigStartValue" SG_ 2566885137 Trail3TPMAxleTireCnfg_Axle4 7;
BA_ "GenSigCycleTime" SG_ 2566876945 Trail3TPMTireInfo_RefPres 100;
BA_ "GenSigCycleTimeActive" SG_ 2566876945 Trail3TPMTireInfo_RefPres 100;
BA_ "GenSigStartValue" SG_ 2566876945 Trail3TPMTireInfo_RefPres 255;
BA_ "GenSigCycleTime" SG_ 2566876945 Trail3TPMTireInfo_Battery 100;
BA_ "GenSigCycleTimeActive" SG_ 2566876945 Trail3TPMTireInfo_Battery 100;
BA_ "GenSigStartValue" SG_ 2566876945 Trail3TPMTireInfo_Battery 7;
BA_ "GenSigCycleTime" SG_ 2566876945 Trail3TPMFailure 100;
BA_ "GenSigCycleTimeActive" SG_ 2566876945 Trail3TPMFailure 100;
BA_ "GenSigStartValue" SG_ 2566876945 Trail3TPMFailure 3;
BA_ "GenSigCycleTime" SG_ 2566876945 Trail3TPMTireInfo_Temperature 100;
BA_ "GenSigCycleTimeActive" SG_ 2566876945 Trail3TPMTireInfo_Temperature 100;
BA_ "GenSigStartValue" SG_ 2566876945 Trail3TPMTireInfo_Temperature 255;
BA_ "GenSigCycleTime" SG_ 2566876945 Trail3TPMTireInfo_Pressure 100;
BA_ "GenSigCycleTimeActive" SG_ 2566876945 Trail3TPMTireInfo_Pressure 100;
BA_ "GenSigStartValue" SG_ 2566876945 Trail3TPMTireInfo_Pressure 255;
BA_ "GenSigCycleTime" SG_ 2566876945 Trail5TPMFailure 100;
BA_ "GenSigCycleTimeActive" SG_ 2566876945 Trail5TPMFailure 100;
BA_ "GenSigStartValue" SG_ 2566876945 Trail5TPMFailure 3;
BA_ "GenSigCycleTime" SG_ 2566876945 Trail3TPMTireInfo_TireId 100;
BA_ "GenSigCycleTimeActive" SG_ 2566876945 Trail3TPMTireInfo_TireId 100;
BA_ "GenSigStartValue" SG_ 2566876945 Trail3TPMTireInfo_TireId 255;
BA_ "GenSigCycleTime" SG_ 2566876945 Trail3TPMTireInfo_PresWarn 100;
BA_ "GenSigCycleTimeActive" SG_ 2566876945 Trail3TPMTireInfo_PresWarn 100;
BA_ "GenSigStartValue" SG_ 2566876945 Trail3TPMTireInfo_PresWarn 7;
BA_ "GenSigCycleTime" SG_ 2566876945 Trail3TPMTireInfo_LeakageWarn 100;
BA_ "GenSigCycleTimeActive" SG_ 2566876945 Trail3TPMTireInfo_LeakageWarn 100;
BA_ "GenSigStartValue" SG_ 2566876945 Trail3TPMTireInfo_LeakageWarn 7;
BA_ "GenSigCycleTime" SG_ 2566876945 Trail4TPMFailure 100;
BA_ "GenSigCycleTimeActive" SG_ 2566876945 Trail4TPMFailure 100;
BA_ "GenSigStartValue" SG_ 2566876945 Trail4TPMFailure 3;
BA_ "GenSigCycleTime" SG_ 2566876945 Trail3TPMTireInfo_Active 100;
BA_ "GenSigCycleTimeActive" SG_ 2566876945 Trail3TPMTireInfo_Active 100;
BA_ "GenSigStartValue" SG_ 2566876945 Trail3TPMTireInfo_Active 3;
BA_ "GenSigCycleTime" SG_ 2566868753 Trail5TPMTireInfo_TireId 100;
BA_ "GenSigCycleTimeActive" SG_ 2566868753 Trail5TPMTireInfo_TireId 100;
BA_ "GenSigStartValue" SG_ 2566868753 Trail5TPMTireInfo_TireId 255;
BA_ "GenSigCycleTime" SG_ 2566868753 Trail5TPMTireInfo_LeakageWarn 100;
BA_ "GenSigCycleTimeActive" SG_ 2566868753 Trail5TPMTireInfo_LeakageWarn 100;
BA_ "GenSigStartValue" SG_ 2566868753 Trail5TPMTireInfo_LeakageWarn 7;
BA_ "GenSigCycleTime" SG_ 2566868753 Trail5TPMTireInfo_RefPres 100;
BA_ "GenSigCycleTimeActive" SG_ 2566868753 Trail5TPMTireInfo_RefPres 100;
BA_ "GenSigStartValue" SG_ 2566868753 Trail5TPMTireInfo_RefPres 255;
BA_ "GenSigCycleTime" SG_ 2566868753 Trail5TPMTireInfo_Pressure 100;
BA_ "GenSigCycleTimeActive" SG_ 2566868753 Trail5TPMTireInfo_Pressure 100;
BA_ "GenSigStartValue" SG_ 2566868753 Trail5TPMTireInfo_Pressure 255;
BA_ "GenSigCycleTime" SG_ 2566868753 Trail5TPMTireInfo_PresWarn 100;
BA_ "GenSigCycleTimeActive" SG_ 2566868753 Trail5TPMTireInfo_PresWarn 100;
BA_ "GenSigStartValue" SG_ 2566868753 Trail5TPMTireInfo_PresWarn 7;
BA_ "GenSigCycleTime" SG_ 2566868753 Trail5TPMTireInfo_Temperature 100;
BA_ "GenSigCycleTimeActive" SG_ 2566868753 Trail5TPMTireInfo_Temperature 100;
BA_ "GenSigStartValue" SG_ 2566868753 Trail5TPMTireInfo_Temperature 255;
BA_ "GenSigCycleTime" SG_ 2566868753 Trail5TPMTireInfo_Battery 100;
BA_ "GenSigCycleTimeActive" SG_ 2566868753 Trail5TPMTireInfo_Battery 100;
BA_ "GenSigStartValue" SG_ 2566868753 Trail5TPMTireInfo_Battery 7;
BA_ "GenSigCycleTime" SG_ 2566868753 Trail5TPMTireInfo_Active 100;
BA_ "GenSigCycleTimeActive" SG_ 2566868753 Trail5TPMTireInfo_Active 100;
BA_ "GenSigStartValue" SG_ 2566868753 Trail5TPMTireInfo_Active 3;
BA_ "GenSigCycleTime" SG_ 2566860305 Trail4TPMTireInfo_LeakageWarn 100;
BA_ "GenSigCycleTimeActive" SG_ 2566860305 Trail4TPMTireInfo_LeakageWarn 100;
BA_ "GenSigStartValue" SG_ 2566860305 Trail4TPMTireInfo_LeakageWarn 7;
BA_ "GenSigCycleTime" SG_ 2566860305 Trail4TPMTireInfo_Battery 100;
BA_ "GenSigCycleTimeActive" SG_ 2566860305 Trail4TPMTireInfo_Battery 100;
BA_ "GenSigStartValue" SG_ 2566860305 Trail4TPMTireInfo_Battery 7;
BA_ "GenSigCycleTime" SG_ 2566860305 Trail4TPMTireInfo_RefPres 100;
BA_ "GenSigCycleTimeActive" SG_ 2566860305 Trail4TPMTireInfo_RefPres 100;
BA_ "GenSigStartValue" SG_ 2566860305 Trail4TPMTireInfo_RefPres 255;
BA_ "GenSigCycleTime" SG_ 2566860305 Trail4TPMTireInfo_Pressure 100;
BA_ "GenSigCycleTimeActive" SG_ 2566860305 Trail4TPMTireInfo_Pressure 100;
BA_ "GenSigStartValue" SG_ 2566860305 Trail4TPMTireInfo_Pressure 255;
BA_ "GenSigCycleTime" SG_ 2566860305 Trail4TPMTireInfo_Active 100;
BA_ "GenSigCycleTimeActive" SG_ 2566860305 Trail4TPMTireInfo_Active 100;
BA_ "GenSigStartValue" SG_ 2566860305 Trail4TPMTireInfo_Active 3;
BA_ "GenSigCycleTime" SG_ 2566860305 Trail4TPMTireInfo_TireId 100;
BA_ "GenSigCycleTimeActive" SG_ 2566860305 Trail4TPMTireInfo_TireId 100;
BA_ "GenSigStartValue" SG_ 2566860305 Trail4TPMTireInfo_TireId 255;
BA_ "GenSigCycleTime" SG_ 2566860305 Trail4TPMTireInfo_Temperature 100;
BA_ "GenSigCycleTimeActive" SG_ 2566860305 Trail4TPMTireInfo_Temperature 100;
BA_ "GenSigStartValue" SG_ 2566860305 Trail4TPMTireInfo_Temperature 255;
BA_ "GenSigCycleTime" SG_ 2566860305 Trail4TPMTireInfo_PresWarn 100;
BA_ "GenSigCycleTimeActive" SG_ 2566860305 Trail4TPMTireInfo_PresWarn 100;
BA_ "GenSigStartValue" SG_ 2566860305 Trail4TPMTireInfo_PresWarn 7;
BA_ "GenSigCycleTime" SG_ 2566881297 Trail4TPMMatedStatus 100;
BA_ "GenSigCycleTimeActive" SG_ 2566881297 Trail4TPMMatedStatus 100;
BA_ "GenSigStartValue" SG_ 2566881297 Trail4TPMMatedStatus 3;
BA_ "GenSigCycleTime" SG_ 2566881297 Trail5TPMMatedStatus 100;
BA_ "GenSigCycleTimeActive" SG_ 2566881297 Trail5TPMMatedStatus 100;
BA_ "GenSigStartValue" SG_ 2566881297 Trail5TPMMatedStatus 3;
BA_ "GenSigCycleTime" SG_ 2566881297 Trail3TPMMatedStatus 100;
BA_ "GenSigCycleTimeActive" SG_ 2566881297 Trail3TPMMatedStatus 100;
BA_ "GenSigStartValue" SG_ 2566881297 Trail3TPMMatedStatus 3;
BA_ "GenSigCycleTime" SG_ 1791 VCMNetVer_C05_Patch 100;
BA_ "GenSigCycleTimeActive" SG_ 1791 VCMNetVer_C05_Patch 100;
BA_ "GenSigCycleTime" SG_ 1791 VCMNetVer_C05_NetID 100;
BA_ "GenSigCycleTimeActive" SG_ 1791 VCMNetVer_C05_NetID 100;
BA_ "GenSigStartValue" SG_ 1791 VCMNetVer_C05_NetID 5;
BA_ "GenSigCycleTime" SG_ 1791 VCMNetVer_C05_Minor 100;
BA_ "GenSigCycleTimeActive" SG_ 1791 VCMNetVer_C05_Minor 100;
BA_ "GenSigStartValue" SG_ 1791 VCMNetVer_C05_Minor 3;
BA_ "GenSigCycleTime" SG_ 1791 VCMNetVer_C05_Dirty 100;
BA_ "GenSigCycleTimeActive" SG_ 1791 VCMNetVer_C05_Dirty 100;
BA_ "GenSigCycleTime" SG_ 1791 VCMNetVer_C05_Major 100;
BA_ "GenSigCycleTimeActive" SG_ 1791 VCMNetVer_C05_Major 100;
BA_ "GenSigStartValue" SG_ 1791 VCMNetVer_C05_Major 2;
BA_ "GenSigCycleTime" SG_ 395 XPRGSystemCap_AllowedInfInhibit_ 100;
BA_ "GenSigCycleTimeActive" SG_ 395 XPRGSystemCap_AllowedInfInhibit_ 100;
BA_ "GenSigStartValue" SG_ 395 XPRGSystemCap_AllowedInfInhibit_ 7;
BA_ "GenSigMaxLatency" SG_ 395 XPRGSystemCap_AllowedInfInhibit_ 50;
BA_ "SystemSignalLongSymbol" SG_ 395 XPRGSystemCap_AllowedInfInhibit_ "XPRGSystemCap_AllowedInfInhibit_ISig_5";
BA_ "GenSigCycleTime" SG_ 395 XPRGSystemCap_Priority_ISig_5 100;
BA_ "GenSigCycleTimeActive" SG_ 395 XPRGSystemCap_Priority_ISig_5 100;
BA_ "GenSigStartValue" SG_ 395 XPRGSystemCap_Priority_ISig_5 7;
BA_ "GenSigMaxLatency" SG_ 395 XPRGSystemCap_Priority_ISig_5 50;
BA_ "GenSigCycleTime" SG_ 395 DRLOverride_DeviceIndication 100;
BA_ "GenSigCycleTimeActive" SG_ 395 DRLOverride_DeviceIndication 100;
BA_ "GenSigStartValue" SG_ 395 DRLOverride_DeviceIndication 3;
BA_ "GenSigCycleTime" SG_ 395 PS_DRLOverride 100;
BA_ "GenSigCycleTimeActive" SG_ 395 PS_DRLOverride 100;
BA_ "GenSigStartValue" SG_ 395 PS_DRLOverride 3;
BA_ "GenSigCycleTime" SG_ 395 PS_Dippedbeam 100;
BA_ "GenSigCycleTimeActive" SG_ 395 PS_Dippedbeam 100;
BA_ "GenSigStartValue" SG_ 395 PS_Dippedbeam 3;
BA_ "GenSigCycleTime" SG_ 395 XPRGSystemCap_AllowedPBApp_ISig_ 100;
BA_ "GenSigCycleTimeActive" SG_ 395 XPRGSystemCap_AllowedPBApp_ISig_ 100;
BA_ "GenSigMaxLatency" SG_ 395 XPRGSystemCap_AllowedPBApp_ISig_ 50;
BA_ "SystemSignalLongSymbol" SG_ 395 XPRGSystemCap_AllowedPBApp_ISig_ "XPRGSystemCap_AllowedPBApp_ISig_5";
BA_ "GenSigCycleTime" SG_ 395 XPRGSystemCap_AllowedRelInhibit_ 100;
BA_ "GenSigCycleTimeActive" SG_ 395 XPRGSystemCap_AllowedRelInhibit_ 100;
BA_ "GenSigStartValue" SG_ 395 XPRGSystemCap_AllowedRelInhibit_ 7;
BA_ "GenSigMaxLatency" SG_ 395 XPRGSystemCap_AllowedRelInhibit_ 50;
BA_ "SystemSignalLongSymbol" SG_ 395 XPRGSystemCap_AllowedRelInhibit_ "XPRGSystemCap_AllowedRelInhibit_ISig_5";
BA_ "GenSigCycleTime" SG_ 395 XPRGSystemCap_CRC_ISig_5 100;
BA_ "GenSigCycleTimeActive" SG_ 395 XPRGSystemCap_CRC_ISig_5 100;
BA_ "GenSigStartValue" SG_ 395 XPRGSystemCap_CRC_ISig_5 255;
BA_ "GenSigMaxLatency" SG_ 395 XPRGSystemCap_CRC_ISig_5 50;
BA_ "E2EDataId" SG_ 395 XPRGSystemCap_CRC_ISig_5 144;
BA_ "E2EDataLength" SG_ 395 XPRGSystemCap_CRC_ISig_5 32;
BA_ "E2EProfile" SG_ 395 XPRGSystemCap_CRC_ISig_5 "P01";
BA_ "GenSigCycleTime" SG_ 395 XPRGSystemCap_AllowedInflation_I 100;
BA_ "GenSigCycleTimeActive" SG_ 395 XPRGSystemCap_AllowedInflation_I 100;
BA_ "GenSigMaxLatency" SG_ 395 XPRGSystemCap_AllowedInflation_I 50;
BA_ "SystemSignalLongSymbol" SG_ 395 XPRGSystemCap_AllowedInflation_I "XPRGSystemCap_AllowedInflation_ISig_5";
BA_ "GenSigCycleTime" SG_ 395 XPRGSystemCap_AllowedGradCtrlTl_ 100;
BA_ "GenSigCycleTimeActive" SG_ 395 XPRGSystemCap_AllowedGradCtrlTl_ 100;
BA_ "GenSigMaxLatency" SG_ 395 XPRGSystemCap_AllowedGradCtrlTl_ 50;
BA_ "SystemSignalLongSymbol" SG_ 395 XPRGSystemCap_AllowedGradCtrlTl_ "XPRGSystemCap_AllowedGradCtrlTl_ISig_5";
BA_ "GenSigCycleTime" SG_ 395 PS_DRL 100;
BA_ "GenSigCycleTimeActive" SG_ 395 PS_DRL 100;
BA_ "GenSigStartValue" SG_ 395 PS_DRL 3;
BA_ "GenSigCycleTime" SG_ 395 XPRGSystemCap_AllowedGradCtrlTc_ 100;
BA_ "GenSigCycleTimeActive" SG_ 395 XPRGSystemCap_AllowedGradCtrlTc_ 100;
BA_ "GenSigMaxLatency" SG_ 395 XPRGSystemCap_AllowedGradCtrlTc_ 50;
BA_ "SystemSignalLongSymbol" SG_ 395 XPRGSystemCap_AllowedGradCtrlTc_ "XPRGSystemCap_AllowedGradCtrlTc_ISig_5";
BA_ "GenSigCycleTime" SG_ 395 XPRGSystemCap_AllowedPBRel_ISig_ 100;
BA_ "GenSigCycleTimeActive" SG_ 395 XPRGSystemCap_AllowedPBRel_ISig_ 100;
BA_ "GenSigMaxLatency" SG_ 395 XPRGSystemCap_AllowedPBRel_ISig_ 50;
BA_ "SystemSignalLongSymbol" SG_ 395 XPRGSystemCap_AllowedPBRel_ISig_ "XPRGSystemCap_AllowedPBRel_ISig_5";
BA_ "GenSigCycleTime" SG_ 395 XPRGSystemCap_AllowedDeflation_I 100;
BA_ "GenSigCycleTimeActive" SG_ 395 XPRGSystemCap_AllowedDeflation_I 100;
BA_ "GenSigMaxLatency" SG_ 395 XPRGSystemCap_AllowedDeflation_I 50;
BA_ "SystemSignalLongSymbol" SG_ 395 XPRGSystemCap_AllowedDeflation_I "XPRGSystemCap_AllowedDeflation_ISig_5";
BA_ "GenSigCycleTime" SG_ 395 XPRGSystemCap_SqC_ISig_5 100;
BA_ "GenSigCycleTimeActive" SG_ 395 XPRGSystemCap_SqC_ISig_5 100;
BA_ "GenSigStartValue" SG_ 395 XPRGSystemCap_SqC_ISig_5 14;
BA_ "GenSigMaxLatency" SG_ 395 XPRGSystemCap_SqC_ISig_5 50;
BA_ "GenSigCycleTime" SG_ 1215 ESSTmp 100;
BA_ "GenSigCycleTimeActive" SG_ 1215 ESSTmp 100;
BA_ "GenSigStartValue" SG_ 1215 ESSTmp 255;
BA_ "GenSigMaxLatency" SG_ 1215 ESSTmp 1000;
BA_ "GenSigCycleTime" SG_ 1215 ESSPmpSpd 100;
BA_ "GenSigCycleTimeActive" SG_ 1215 ESSPmpSpd 100;
BA_ "GenSigStartValue" SG_ 1215 ESSPmpSpd 255;
BA_ "GenSigMaxLatency" SG_ 1215 ESSPmpSpd 1000;
BA_ "GenSigCycleTime" SG_ 1215 ServiceBrakeAirPrsCircuit1_ISig_ 100;
BA_ "GenSigCycleTimeActive" SG_ 1215 ServiceBrakeAirPrsCircuit1_ISig_ 100;
BA_ "GenSigStartValue" SG_ 1215 ServiceBrakeAirPrsCircuit1_ISig_ 255;
BA_ "SystemSignalLongSymbol" SG_ 1215 ServiceBrakeAirPrsCircuit1_ISig_ "ServiceBrakeAirPrsCircuit1_ISig_5";
BA_ "GenSigCycleTime" SG_ 1215 ESSTmpTrgt 100;
BA_ "GenSigCycleTimeActive" SG_ 1215 ESSTmpTrgt 100;
BA_ "GenSigStartValue" SG_ 1215 ESSTmpTrgt 255;
BA_ "GenSigMaxLatency" SG_ 1215 ESSTmpTrgt 1000;
BA_ "GenSigCycleTime" SG_ 1215 ESSClntTmp 100;
BA_ "GenSigCycleTimeActive" SG_ 1215 ESSClntTmp 100;
BA_ "GenSigStartValue" SG_ 1215 ESSClntTmp 255;
BA_ "GenSigMaxLatency" SG_ 1215 ESSClntTmp 1000;
BA_ "GenSigCycleTime" SG_ 1215 EMPmpSpd 100;
BA_ "GenSigCycleTimeActive" SG_ 1215 EMPmpSpd 100;
BA_ "GenSigStartValue" SG_ 1215 EMPmpSpd 255;
BA_ "GenSigMaxLatency" SG_ 1215 EMPmpSpd 1000;
BA_ "GenSigCycleTime" SG_ 1215 ServiceBrakeAirPrsCircuit2_ISig_ 100;
BA_ "GenSigCycleTimeActive" SG_ 1215 ServiceBrakeAirPrsCircuit2_ISig_ 100;
BA_ "GenSigStartValue" SG_ 1215 ServiceBrakeAirPrsCircuit2_ISig_ 255;
BA_ "SystemSignalLongSymbol" SG_ 1215 ServiceBrakeAirPrsCircuit2_ISig_ "ServiceBrakeAirPrsCircuit2_ISig_5";
BA_ "GenSigCycleTime" SG_ 907 Trailer5GeometricData_Index_ISig 100;
BA_ "GenSigCycleTimeActive" SG_ 907 Trailer5GeometricData_Index_ISig 100;
BA_ "GenSigStartValue" SG_ 907 Trailer5GeometricData_Index_ISig 255;
BA_ "GenSigMaxLatency" SG_ 907 Trailer5GeometricData_Index_ISig 500;
BA_ "SystemSignalLongSymbol" SG_ 907 Trailer5GeometricData_Index_ISig "Trailer5GeometricData_Index_ISig_5";
BA_ "GenSigCycleTime" SG_ 907 Trailer5GeometricData_Content_IS 100;
BA_ "GenSigCycleTimeActive" SG_ 907 Trailer5GeometricData_Content_IS 100;
BA_ "GenSigStartValue" SG_ 907 Trailer5GeometricData_Content_IS 255;
BA_ "GenSigMaxLatency" SG_ 907 Trailer5GeometricData_Content_IS 500;
BA_ "SystemSignalLongSymbol" SG_ 907 Trailer5GeometricData_Content_IS "Trailer5GeometricData_Content_ISig_5";
BA_ "GenSigCycleTime" SG_ 906 Trailer3GeometricData_Index_ISig 100;
BA_ "GenSigCycleTimeActive" SG_ 906 Trailer3GeometricData_Index_ISig 100;
BA_ "GenSigStartValue" SG_ 906 Trailer3GeometricData_Index_ISig 255;
BA_ "GenSigMaxLatency" SG_ 906 Trailer3GeometricData_Index_ISig 500;
BA_ "SystemSignalLongSymbol" SG_ 906 Trailer3GeometricData_Index_ISig "Trailer3GeometricData_Index_ISig_5";
BA_ "GenSigCycleTime" SG_ 906 Trailer1GeometricData_Content_IS 100;
BA_ "GenSigCycleTimeActive" SG_ 906 Trailer1GeometricData_Content_IS 100;
BA_ "GenSigStartValue" SG_ 906 Trailer1GeometricData_Content_IS 255;
BA_ "GenSigMaxLatency" SG_ 906 Trailer1GeometricData_Content_IS 500;
BA_ "SystemSignalLongSymbol" SG_ 906 Trailer1GeometricData_Content_IS "Trailer1GeometricData_Content_ISig_5";
BA_ "GenSigCycleTime" SG_ 906 Trailer2GeometricData_Index_ISig 100;
BA_ "GenSigCycleTimeActive" SG_ 906 Trailer2GeometricData_Index_ISig 100;
BA_ "GenSigStartValue" SG_ 906 Trailer2GeometricData_Index_ISig 255;
BA_ "GenSigMaxLatency" SG_ 906 Trailer2GeometricData_Index_ISig 500;
BA_ "SystemSignalLongSymbol" SG_ 906 Trailer2GeometricData_Index_ISig "Trailer2GeometricData_Index_ISig_5";
BA_ "GenSigCycleTime" SG_ 906 Trailer4GeometricData_Index_ISig 100;
BA_ "GenSigCycleTimeActive" SG_ 906 Trailer4GeometricData_Index_ISig 100;
BA_ "GenSigStartValue" SG_ 906 Trailer4GeometricData_Index_ISig 255;
BA_ "GenSigMaxLatency" SG_ 906 Trailer4GeometricData_Index_ISig 500;
BA_ "SystemSignalLongSymbol" SG_ 906 Trailer4GeometricData_Index_ISig "Trailer4GeometricData_Index_ISig_5";
BA_ "GenSigCycleTime" SG_ 906 Trailer3GeometricData_Content_IS 100;
BA_ "GenSigCycleTimeActive" SG_ 906 Trailer3GeometricData_Content_IS 100;
BA_ "GenSigStartValue" SG_ 906 Trailer3GeometricData_Content_IS 255;
BA_ "GenSigMaxLatency" SG_ 906 Trailer3GeometricData_Content_IS 500;
BA_ "SystemSignalLongSymbol" SG_ 906 Trailer3GeometricData_Content_IS "Trailer3GeometricData_Content_ISig_5";
BA_ "GenSigCycleTime" SG_ 906 Trailer2GeometricData_Content_IS 100;
BA_ "GenSigCycleTimeActive" SG_ 906 Trailer2GeometricData_Content_IS 100;
BA_ "GenSigStartValue" SG_ 906 Trailer2GeometricData_Content_IS 255;
BA_ "GenSigMaxLatency" SG_ 906 Trailer2GeometricData_Content_IS 500;
BA_ "SystemSignalLongSymbol" SG_ 906 Trailer2GeometricData_Content_IS "Trailer2GeometricData_Content_ISig_5";
BA_ "GenSigCycleTime" SG_ 906 Trailer4GeometricData_Content_IS 100;
BA_ "GenSigCycleTimeActive" SG_ 906 Trailer4GeometricData_Content_IS 100;
BA_ "GenSigStartValue" SG_ 906 Trailer4GeometricData_Content_IS 255;
BA_ "GenSigMaxLatency" SG_ 906 Trailer4GeometricData_Content_IS 500;
BA_ "SystemSignalLongSymbol" SG_ 906 Trailer4GeometricData_Content_IS "Trailer4GeometricData_Content_ISig_5";
BA_ "GenSigCycleTime" SG_ 906 Trailer1GeometricData_Index_ISig 100;
BA_ "GenSigCycleTimeActive" SG_ 906 Trailer1GeometricData_Index_ISig 100;
BA_ "GenSigStartValue" SG_ 906 Trailer1GeometricData_Index_ISig 255;
BA_ "GenSigMaxLatency" SG_ 906 Trailer1GeometricData_Index_ISig 500;
BA_ "SystemSignalLongSymbol" SG_ 906 Trailer1GeometricData_Index_ISig "Trailer1GeometricData_Index_ISig_5";
BA_ "GenSigCycleTime" SG_ 870 FrontAxle2Load_ISig_5 100;
BA_ "GenSigCycleTimeActive" SG_ 870 FrontAxle2Load_ISig_5 100;
BA_ "GenSigStartValue" SG_ 870 FrontAxle2Load_ISig_5 65535;
BA_ "GenSigMaxLatency" SG_ 870 FrontAxle2Load_ISig_5 250;
BA_ "GenSigCycleTime" SG_ 870 TagAxleLoad_ISig_5 100;
BA_ "GenSigCycleTimeActive" SG_ 870 TagAxleLoad_ISig_5 100;
BA_ "GenSigStartValue" SG_ 870 TagAxleLoad_ISig_5 65535;
BA_ "GenSigMaxLatency" SG_ 870 TagAxleLoad_ISig_5 250;
BA_ "GenSigCycleTime" SG_ 870 PusherAxleLoad_ISig_5 100;
BA_ "GenSigCycleTimeActive" SG_ 870 PusherAxleLoad_ISig_5 100;
BA_ "GenSigStartValue" SG_ 870 PusherAxleLoad_ISig_5 65535;
BA_ "GenSigMaxLatency" SG_ 870 PusherAxleLoad_ISig_5 250;
BA_ "GenSigCycleTime" SG_ 870 FrontAxle1Load_ISig_5 100;
BA_ "GenSigCycleTimeActive" SG_ 870 FrontAxle1Load_ISig_5 100;
BA_ "GenSigStartValue" SG_ 870 FrontAxle1Load_ISig_5 65535;
BA_ "GenSigMaxLatency" SG_ 870 FrontAxle1Load_ISig_5 250;
BA_ "GenSigCycleTime" SG_ 698 Trailer1LiftAxle2Pos_ISig_5 100;
BA_ "GenSigCycleTimeActive" SG_ 698 Trailer1LiftAxle2Pos_ISig_5 100;
BA_ "GenSigStartValue" SG_ 698 Trailer1LiftAxle2Pos_ISig_5 3;
BA_ "GenSigMaxLatency" SG_ 698 Trailer1LiftAxle2Pos_ISig_5 100;
BA_ "GenSigCycleTime" SG_ 698 Trailer5LiftAxle1Pos_ISig_5 100;
BA_ "GenSigCycleTimeActive" SG_ 698 Trailer5LiftAxle1Pos_ISig_5 100;
BA_ "GenSigStartValue" SG_ 698 Trailer5LiftAxle1Pos_ISig_5 3;
BA_ "GenSigMaxLatency" SG_ 698 Trailer5LiftAxle1Pos_ISig_5 100;
BA_ "GenSigCycleTime" SG_ 698 MaxEngineCoolingCapacity_Rqst 100;
BA_ "GenSigCycleTimeActive" SG_ 698 MaxEngineCoolingCapacity_Rqst 100;
BA_ "GenSigStartValue" SG_ 698 MaxEngineCoolingCapacity_Rqst 3;
BA_ "GenSigMaxLatency" SG_ 698 MaxEngineCoolingCapacity_Rqst 100;
BA_ "GenSigCycleTime" SG_ 698 Trailer2LiftAxle2Pos_ISig_5 100;
BA_ "GenSigCycleTimeActive" SG_ 698 Trailer2LiftAxle2Pos_ISig_5 100;
BA_ "GenSigStartValue" SG_ 698 Trailer2LiftAxle2Pos_ISig_5 3;
BA_ "GenSigMaxLatency" SG_ 698 Trailer2LiftAxle2Pos_ISig_5 100;
BA_ "GenSigCycleTime" SG_ 698 Trailer4LiftAxle2Pos_ISig_5 100;
BA_ "GenSigCycleTimeActive" SG_ 698 Trailer4LiftAxle2Pos_ISig_5 100;
BA_ "GenSigStartValue" SG_ 698 Trailer4LiftAxle2Pos_ISig_5 3;
BA_ "GenSigMaxLatency" SG_ 698 Trailer4LiftAxle2Pos_ISig_5 100;
BA_ "GenSigCycleTime" SG_ 698 Trailer2LiftAxle1Pos_ISig_5 100;
BA_ "GenSigCycleTimeActive" SG_ 698 Trailer2LiftAxle1Pos_ISig_5 100;
BA_ "GenSigStartValue" SG_ 698 Trailer2LiftAxle1Pos_ISig_5 3;
BA_ "GenSigMaxLatency" SG_ 698 Trailer2LiftAxle1Pos_ISig_5 100;
BA_ "GenSigCycleTime" SG_ 698 Trailer1LiftAxle1Pos_ISig_5 100;
BA_ "GenSigCycleTimeActive" SG_ 698 Trailer1LiftAxle1Pos_ISig_5 100;
BA_ "GenSigStartValue" SG_ 698 Trailer1LiftAxle1Pos_ISig_5 3;
BA_ "GenSigMaxLatency" SG_ 698 Trailer1LiftAxle1Pos_ISig_5 100;
BA_ "GenSigCycleTime" SG_ 698 RainSensorStatus 100;
BA_ "GenSigCycleTimeActive" SG_ 698 RainSensorStatus 100;
BA_ "GenSigStartValue" SG_ 698 RainSensorStatus 7;
BA_ "GenSigCycleTime" SG_ 698 Trailer4LiftAxle1Pos_ISig_5 100;
BA_ "GenSigCycleTimeActive" SG_ 698 Trailer4LiftAxle1Pos_ISig_5 100;
BA_ "GenSigStartValue" SG_ 698 Trailer4LiftAxle1Pos_ISig_5 3;
BA_ "GenSigMaxLatency" SG_ 698 Trailer4LiftAxle1Pos_ISig_5 100;
BA_ "GenSigCycleTime" SG_ 698 Trailer3LiftAxle2Pos_ISig_5 100;
BA_ "GenSigCycleTimeActive" SG_ 698 Trailer3LiftAxle2Pos_ISig_5 100;
BA_ "GenSigStartValue" SG_ 698 Trailer3LiftAxle2Pos_ISig_5 3;
BA_ "GenSigMaxLatency" SG_ 698 Trailer3LiftAxle2Pos_ISig_5 100;
BA_ "GenSigCycleTime" SG_ 698 Trailer5LiftAxle2Pos_ISig_5 100;
BA_ "GenSigCycleTimeActive" SG_ 698 Trailer5LiftAxle2Pos_ISig_5 100;
BA_ "GenSigStartValue" SG_ 698 Trailer5LiftAxle2Pos_ISig_5 3;
BA_ "GenSigMaxLatency" SG_ 698 Trailer5LiftAxle2Pos_ISig_5 100;
BA_ "GenSigCycleTime" SG_ 698 Trailer3LiftAxle1Pos_ISig_5 100;
BA_ "GenSigCycleTimeActive" SG_ 698 Trailer3LiftAxle1Pos_ISig_5 100;
BA_ "GenSigStartValue" SG_ 698 Trailer3LiftAxle1Pos_ISig_5 3;
BA_ "GenSigMaxLatency" SG_ 698 Trailer3LiftAxle1Pos_ISig_5 100;
BA_ "GenSigCycleTime" SG_ 157 ChangeKneelACK_ISig_5 100;
BA_ "GenSigCycleTimeActive" SG_ 157 ChangeKneelACK_ISig_5 100;
BA_ "GenSigStartValue" SG_ 157 ChangeKneelACK_ISig_5 3;
BA_ "GenSigMaxLatency" SG_ 157 ChangeKneelACK_ISig_5 20;
BA_ "GenSigCycleTime" SG_ 157 InteriorLightDimming_rqst 100;
BA_ "GenSigCycleTimeActive" SG_ 157 InteriorLightDimming_rqst 100;
BA_ "GenSigStartValue" SG_ 157 InteriorLightDimming_rqst 31;
BA_ "GenSigMaxLatency" SG_ 157 InteriorLightDimming_rqst 20;
BA_ "GenSigCycleTime" SG_ 157 DirectionIndication_cmd 100;
BA_ "GenSigCycleTimeActive" SG_ 157 DirectionIndication_cmd 100;
BA_ "GenSigStartValue" SG_ 157 DirectionIndication_cmd 15;
BA_ "GenSigMaxLatency" SG_ 157 DirectionIndication_cmd 20;
BA_ "GenSigCycleTime" SG_ 157 RampLevelRequestACK_ISig_5 100;
BA_ "GenSigCycleTimeActive" SG_ 157 RampLevelRequestACK_ISig_5 100;
BA_ "GenSigStartValue" SG_ 157 RampLevelRequestACK_ISig_5 3;
BA_ "GenSigMaxLatency" SG_ 157 RampLevelRequestACK_ISig_5 20;
BA_ "GenSigCycleTime" SG_ 157 LoadDistributionSelected_ISig_5 100;
BA_ "GenSigCycleTimeActive" SG_ 157 LoadDistributionSelected_ISig_5 100;
BA_ "GenSigStartValue" SG_ 157 LoadDistributionSelected_ISig_5 15;
BA_ "GenSigMaxLatency" SG_ 157 LoadDistributionSelected_ISig_5 20;
BA_ "GenSigCycleTime" SG_ 157 HeightAdjustmentAllowed_ISig_5 100;
BA_ "GenSigCycleTimeActive" SG_ 157 HeightAdjustmentAllowed_ISig_5 100;
BA_ "GenSigStartValue" SG_ 157 HeightAdjustmentAllowed_ISig_5 3;
BA_ "GenSigMaxLatency" SG_ 157 HeightAdjustmentAllowed_ISig_5 20;
BA_ "GenSigCycleTime" SG_ 157 AirDumpStatus_ISig_5 100;
BA_ "GenSigCycleTimeActive" SG_ 157 AirDumpStatus_ISig_5 100;
BA_ "GenSigStartValue" SG_ 157 AirDumpStatus_ISig_5 7;
BA_ "GenSigMaxLatency" SG_ 157 AirDumpStatus_ISig_5 20;
BA_ "GenSigCycleTime" SG_ 157 KneelingStatusHMI_ISig_5 100;
BA_ "GenSigCycleTimeActive" SG_ 157 KneelingStatusHMI_ISig_5 100;
BA_ "GenSigStartValue" SG_ 157 KneelingStatusHMI_ISig_5 3;
BA_ "GenSigMaxLatency" SG_ 157 KneelingStatusHMI_ISig_5 20;
BA_ "GenSigCycleTime" SG_ 157 BackToDriveReqACK_ISig_5 100;
BA_ "GenSigCycleTimeActive" SG_ 157 BackToDriveReqACK_ISig_5 100;
BA_ "GenSigStartValue" SG_ 157 BackToDriveReqACK_ISig_5 3;
BA_ "GenSigMaxLatency" SG_ 157 BackToDriveReqACK_ISig_5 20;
BA_ "GenSigCycleTime" SG_ 157 LoadDistributionFuncSelected_ISi 100;
BA_ "GenSigCycleTimeActive" SG_ 157 LoadDistributionFuncSelected_ISi 100;
BA_ "GenSigStartValue" SG_ 157 LoadDistributionFuncSelected_ISi 15;
BA_ "GenSigMaxLatency" SG_ 157 LoadDistributionFuncSelected_ISi 20;
BA_ "SystemSignalLongSymbol" SG_ 157 LoadDistributionFuncSelected_ISi "LoadDistributionFuncSelected_ISig_5";
BA_ "GenSigCycleTime" SG_ 157 StopLevelChangeAck_ISig_5 100;
BA_ "GenSigCycleTimeActive" SG_ 157 StopLevelChangeAck_ISig_5 100;
BA_ "GenSigStartValue" SG_ 157 StopLevelChangeAck_ISig_5 3;
BA_ "GenSigMaxLatency" SG_ 157 StopLevelChangeAck_ISig_5 20;
BA_ "GenSigCycleTime" SG_ 157 RampLevelStorageAck_ISig_5 100;
BA_ "GenSigCycleTimeActive" SG_ 157 RampLevelStorageAck_ISig_5 100;
BA_ "GenSigStartValue" SG_ 157 RampLevelStorageAck_ISig_5 3;
BA_ "GenSigMaxLatency" SG_ 157 RampLevelStorageAck_ISig_5 20;
BA_ "GenSigCycleTime" SG_ 157 FerryFunctionSwitchChangeACK_ISi 100;
BA_ "GenSigCycleTimeActive" SG_ 157 FerryFunctionSwitchChangeACK_ISi 100;
BA_ "GenSigStartValue" SG_ 157 FerryFunctionSwitchChangeACK_ISi 3;
BA_ "GenSigMaxLatency" SG_ 157 FerryFunctionSwitchChangeACK_ISi 20;
BA_ "SystemSignalLongSymbol" SG_ 157 FerryFunctionSwitchChangeACK_ISi "FerryFunctionSwitchChangeACK_ISig_5";
BA_ "GenSigCycleTime" SG_ 157 LiftAxle1RequestResponse 100;
BA_ "GenSigCycleTimeActive" SG_ 157 LiftAxle1RequestResponse 100;
BA_ "GenSigStartValue" SG_ 157 LiftAxle1RequestResponse 15;
BA_ "GenSigMaxLatency" SG_ 157 LiftAxle1RequestResponse 20;
BA_ "GenSigCycleTime" SG_ 157 ECSStandbyAllowed_ISig_5 100;
BA_ "GenSigCycleTimeActive" SG_ 157 ECSStandbyAllowed_ISig_5 100;
BA_ "GenSigStartValue" SG_ 157 ECSStandbyAllowed_ISig_5 3;
BA_ "GenSigMaxLatency" SG_ 157 ECSStandbyAllowed_ISig_5 20;
BA_ "GenSigCycleTime" SG_ 157 RideHeightStorageAck_ISig_5 100;
BA_ "GenSigCycleTimeActive" SG_ 157 RideHeightStorageAck_ISig_5 100;
BA_ "GenSigStartValue" SG_ 157 RideHeightStorageAck_ISig_5 3;
BA_ "GenSigMaxLatency" SG_ 157 RideHeightStorageAck_ISig_5 20;
BA_ "GenSigCycleTime" SG_ 157 IntLightMode_CoreRqst_EventFlag 100;
BA_ "GenSigCycleTimeActive" SG_ 157 IntLightMode_CoreRqst_EventFlag 100;
BA_ "GenSigMaxLatency" SG_ 157 IntLightMode_CoreRqst_EventFlag 20;
BA_ "GenSigCycleTime" SG_ 157 IntLightMode_CoreRqst_IL_Mode 100;
BA_ "GenSigCycleTimeActive" SG_ 157 IntLightMode_CoreRqst_IL_Mode 100;
BA_ "GenSigStartValue" SG_ 157 IntLightMode_CoreRqst_IL_Mode 7;
BA_ "GenSigMaxLatency" SG_ 157 IntLightMode_CoreRqst_IL_Mode 20;
BA_ "GenSigCycleTime" SG_ 869 CoolantPumpEngagementStatus_ISig 100;
BA_ "GenSigCycleTimeActive" SG_ 869 CoolantPumpEngagementStatus_ISig 100;
BA_ "GenSigStartValue" SG_ 869 CoolantPumpEngagementStatus_ISig 255;
BA_ "GenSigMaxLatency" SG_ 869 CoolantPumpEngagementStatus_ISig 260;
BA_ "SystemSignalLongSymbol" SG_ 869 CoolantPumpEngagementStatus_ISig "CoolantPumpEngagementStatus_ISig_5";
BA_ "GenSigCycleTime" SG_ 869 CoolantTempGaugeAdjustment_ISig_ 100;
BA_ "GenSigCycleTimeActive" SG_ 869 CoolantTempGaugeAdjustment_ISig_ 100;
BA_ "GenSigStartValue" SG_ 869 CoolantTempGaugeAdjustment_ISig_ 255;
BA_ "GenSigMaxLatency" SG_ 869 CoolantTempGaugeAdjustment_ISig_ 260;
BA_ "SystemSignalLongSymbol" SG_ 869 CoolantTempGaugeAdjustment_ISig_ "CoolantTempGaugeAdjustment_ISig_5";
BA_ "GenSigCycleTime" SG_ 869 EngineTotalFuelConsumed_ISig_5 100;
BA_ "GenSigCycleTimeActive" SG_ 869 EngineTotalFuelConsumed_ISig_5 100;
BA_ "GenSigStartValue" SG_ 869 EngineTotalFuelConsumed_ISig_5 4294967295;
BA_ "GenSigCycleTime" SG_ 869 EngineCoolingFanSpeed_ISig_5 100;
BA_ "GenSigCycleTimeActive" SG_ 869 EngineCoolingFanSpeed_ISig_5 100;
BA_ "GenSigStartValue" SG_ 869 EngineCoolingFanSpeed_ISig_5 65535;
BA_ "GenSigMaxLatency" SG_ 869 EngineCoolingFanSpeed_ISig_5 250;
BA_ "GenSigCycleTime" SG_ 1209 LngTank2RemainingGasVolume_ISig_ 100;
BA_ "GenSigCycleTimeActive" SG_ 1209 LngTank2RemainingGasVolume_ISig_ 100;
BA_ "GenSigStartValue" SG_ 1209 LngTank2RemainingGasVolume_ISig_ 255;
BA_ "GenSigMaxLatency" SG_ 1209 LngTank2RemainingGasVolume_ISig_ 1030;
BA_ "SystemSignalLongSymbol" SG_ 1209 LngTank2RemainingGasVolume_ISig_ "LngTank2RemainingGasVolume_ISig_5";
BA_ "GenSigCycleTime" SG_ 1209 LNGRestrictionStatus_Spare4_ISig 100;
BA_ "GenSigCycleTimeActive" SG_ 1209 LNGRestrictionStatus_Spare4_ISig 100;
BA_ "GenSigMaxLatency" SG_ 1209 LNGRestrictionStatus_Spare4_ISig 1030;
BA_ "SystemSignalLongSymbol" SG_ 1209 LNGRestrictionStatus_Spare4_ISig "LNGRestrictionStatus_Spare4_ISig_5";
BA_ "GenSigCycleTime" SG_ 1209 LNGRestrictionStatus_V1Closed_IS 100;
BA_ "GenSigCycleTimeActive" SG_ 1209 LNGRestrictionStatus_V1Closed_IS 100;
BA_ "GenSigMaxLatency" SG_ 1209 LNGRestrictionStatus_V1Closed_IS 1030;
BA_ "SystemSignalLongSymbol" SG_ 1209 LNGRestrictionStatus_V1Closed_IS "LNGRestrictionStatus_V1Closed_ISig_5";
BA_ "GenSigCycleTime" SG_ 1209 LNGRestrictionStatus_Spare3_ISig 100;
BA_ "GenSigCycleTimeActive" SG_ 1209 LNGRestrictionStatus_Spare3_ISig 100;
BA_ "GenSigMaxLatency" SG_ 1209 LNGRestrictionStatus_Spare3_ISig 1030;
BA_ "SystemSignalLongSymbol" SG_ 1209 LNGRestrictionStatus_Spare3_ISig "LNGRestrictionStatus_Spare3_ISig_5";
BA_ "GenSigCycleTime" SG_ 1209 LngTank2WarnStat_ISig_5 100;
BA_ "GenSigCycleTimeActive" SG_ 1209 LngTank2WarnStat_ISig_5 100;
BA_ "GenSigStartValue" SG_ 1209 LngTank2WarnStat_ISig_5 3;
BA_ "GenSigMaxLatency" SG_ 1209 LngTank2WarnStat_ISig_5 1030;
BA_ "GenSigCycleTime" SG_ 1209 LNGRestrictionStatus_Spare2_ISig 100;
BA_ "GenSigCycleTimeActive" SG_ 1209 LNGRestrictionStatus_Spare2_ISig 100;
BA_ "GenSigMaxLatency" SG_ 1209 LNGRestrictionStatus_Spare2_ISig 1030;
BA_ "SystemSignalLongSymbol" SG_ 1209 LNGRestrictionStatus_Spare2_ISig "LNGRestrictionStatus_Spare2_ISig_5";
BA_ "GenSigCycleTime" SG_ 1209 LngTank1RemainingGasVolume_ISig_ 100;
BA_ "GenSigCycleTimeActive" SG_ 1209 LngTank1RemainingGasVolume_ISig_ 100;
BA_ "GenSigStartValue" SG_ 1209 LngTank1RemainingGasVolume_ISig_ 255;
BA_ "GenSigMaxLatency" SG_ 1209 LngTank1RemainingGasVolume_ISig_ 1030;
BA_ "SystemSignalLongSymbol" SG_ 1209 LngTank1RemainingGasVolume_ISig_ "LngTank1RemainingGasVolume_ISig_5";
BA_ "GenSigCycleTime" SG_ 1209 LngSystemReadinessStat_ISig_5 100;
BA_ "GenSigCycleTimeActive" SG_ 1209 LngSystemReadinessStat_ISig_5 100;
BA_ "GenSigStartValue" SG_ 1209 LngSystemReadinessStat_ISig_5 7;
BA_ "GenSigMaxLatency" SG_ 1209 LngSystemReadinessStat_ISig_5 1030;
BA_ "GenSigCycleTime" SG_ 1209 LNGOperatorInducementReason_ISig 100;
BA_ "GenSigCycleTimeActive" SG_ 1209 LNGOperatorInducementReason_ISig 100;
BA_ "GenSigStartValue" SG_ 1209 LNGOperatorInducementReason_ISig 7;
BA_ "GenSigMaxLatency" SG_ 1209 LNGOperatorInducementReason_ISig 1030;
BA_ "SystemSignalLongSymbol" SG_ 1209 LNGOperatorInducementReason_ISig "LNGOperatorInducementReason_ISig_5";
BA_ "GenSigCycleTime" SG_ 1209 LNGRestrictionStatus_Spare1_ISig 100;
BA_ "GenSigCycleTimeActive" SG_ 1209 LNGRestrictionStatus_Spare1_ISig 100;
BA_ "GenSigMaxLatency" SG_ 1209 LNGRestrictionStatus_Spare1_ISig 1030;
BA_ "SystemSignalLongSymbol" SG_ 1209 LNGRestrictionStatus_Spare1_ISig "LNGRestrictionStatus_Spare1_ISig_5";
BA_ "GenSigCycleTime" SG_ 1209 LNGRestrictionStatus_V2Closed_IS 100;
BA_ "GenSigCycleTimeActive" SG_ 1209 LNGRestrictionStatus_V2Closed_IS 100;
BA_ "GenSigMaxLatency" SG_ 1209 LNGRestrictionStatus_V2Closed_IS 1030;
BA_ "SystemSignalLongSymbol" SG_ 1209 LNGRestrictionStatus_V2Closed_IS "LNGRestrictionStatus_V2Closed_ISig_5";
BA_ "GenSigCycleTime" SG_ 1209 LngTank1WarnStat_ISig_5 100;
BA_ "GenSigCycleTimeActive" SG_ 1209 LngTank1WarnStat_ISig_5 100;
BA_ "GenSigStartValue" SG_ 1209 LngTank1WarnStat_ISig_5 3;
BA_ "GenSigMaxLatency" SG_ 1209 LngTank1WarnStat_ISig_5 1030;
BA_ "GenSigCycleTime" SG_ 1209 LNGTimeToVent_ISig_5 100;
BA_ "GenSigCycleTimeActive" SG_ 1209 LNGTimeToVent_ISig_5 100;
BA_ "GenSigStartValue" SG_ 1209 LNGTimeToVent_ISig_5 65535;
BA_ "GenSigMaxLatency" SG_ 1209 LNGTimeToVent_ISig_5 1030;
BA_ "GenSigCycleTime" SG_ 1209 LNGLevel_ISig_5 100;
BA_ "GenSigCycleTimeActive" SG_ 1209 LNGLevel_ISig_5 100;
BA_ "GenSigStartValue" SG_ 1209 LNGLevel_ISig_5 255;
BA_ "GenSigMaxLatency" SG_ 1209 LNGLevel_ISig_5 1030;
BA_ "GenSigCycleTime" SG_ 1209 LNGRestrictionStatus_SInfo_ISig_ 100;
BA_ "GenSigCycleTimeActive" SG_ 1209 LNGRestrictionStatus_SInfo_ISig_ 100;
BA_ "GenSigStartValue" SG_ 1209 LNGRestrictionStatus_SInfo_ISig_ 3;
BA_ "GenSigMaxLatency" SG_ 1209 LNGRestrictionStatus_SInfo_ISig_ 1030;
BA_ "SystemSignalLongSymbol" SG_ 1209 LNGRestrictionStatus_SInfo_ISig_ "LNGRestrictionStatus_SInfo_ISig_5";
BA_ "GenSigCycleTime" SG_ 1209 LngGspWarnStat_ISig_5 100;
BA_ "GenSigCycleTimeActive" SG_ 1209 LngGspWarnStat_ISig_5 100;
BA_ "GenSigStartValue" SG_ 1209 LngGspWarnStat_ISig_5 3;
BA_ "GenSigMaxLatency" SG_ 1209 LngGspWarnStat_ISig_5 1030;
BA_ "GenSigCycleTime" SG_ 1208 EcoCruisePwtMaxUnSpeedLev3_ISig_ 100;
BA_ "GenSigCycleTimeActive" SG_ 1208 EcoCruisePwtMaxUnSpeedLev3_ISig_ 100;
BA_ "GenSigStartValue" SG_ 1208 EcoCruisePwtMaxUnSpeedLev3_ISig_ 31;
BA_ "GenSigMaxLatency" SG_ 1208 EcoCruisePwtMaxUnSpeedLev3_ISig_ 1020;
BA_ "SystemSignalLongSymbol" SG_ 1208 EcoCruisePwtMaxUnSpeedLev3_ISig_ "EcoCruisePwtMaxUnSpeedLev3_ISig_5";
BA_ "GenSigCycleTime" SG_ 1208 EcoCruisePwtMaxOvSpeedLev0_ISig_ 100;
BA_ "GenSigCycleTimeActive" SG_ 1208 EcoCruisePwtMaxOvSpeedLev0_ISig_ 100;
BA_ "GenSigStartValue" SG_ 1208 EcoCruisePwtMaxOvSpeedLev0_ISig_ 31;
BA_ "GenSigMaxLatency" SG_ 1208 EcoCruisePwtMaxOvSpeedLev0_ISig_ 1020;
BA_ "SystemSignalLongSymbol" SG_ 1208 EcoCruisePwtMaxOvSpeedLev0_ISig_ "EcoCruisePwtMaxOvSpeedLev0_ISig_5";
BA_ "GenSigCycleTime" SG_ 1208 EcoCruisePwtMaxUnSpeedLev1_ISig_ 100;
BA_ "GenSigCycleTimeActive" SG_ 1208 EcoCruisePwtMaxUnSpeedLev1_ISig_ 100;
BA_ "GenSigStartValue" SG_ 1208 EcoCruisePwtMaxUnSpeedLev1_ISig_ 31;
BA_ "GenSigMaxLatency" SG_ 1208 EcoCruisePwtMaxUnSpeedLev1_ISig_ 1020;
BA_ "SystemSignalLongSymbol" SG_ 1208 EcoCruisePwtMaxUnSpeedLev1_ISig_ "EcoCruisePwtMaxUnSpeedLev1_ISig_5";
BA_ "GenSigCycleTime" SG_ 1208 EcoCruisePwtMaxOvSpeedLev2_ISig_ 100;
BA_ "GenSigCycleTimeActive" SG_ 1208 EcoCruisePwtMaxOvSpeedLev2_ISig_ 100;
BA_ "GenSigStartValue" SG_ 1208 EcoCruisePwtMaxOvSpeedLev2_ISig_ 31;
BA_ "GenSigMaxLatency" SG_ 1208 EcoCruisePwtMaxOvSpeedLev2_ISig_ 1020;
BA_ "SystemSignalLongSymbol" SG_ 1208 EcoCruisePwtMaxOvSpeedLev2_ISig_ "EcoCruisePwtMaxOvSpeedLev2_ISig_5";
BA_ "GenSigCycleTime" SG_ 1208 EcoCruisePwtMaxUnSpeedLev0_ISig_ 100;
BA_ "GenSigCycleTimeActive" SG_ 1208 EcoCruisePwtMaxUnSpeedLev0_ISig_ 100;
BA_ "GenSigStartValue" SG_ 1208 EcoCruisePwtMaxUnSpeedLev0_ISig_ 31;
BA_ "GenSigMaxLatency" SG_ 1208 EcoCruisePwtMaxUnSpeedLev0_ISig_ 1020;
BA_ "SystemSignalLongSymbol" SG_ 1208 EcoCruisePwtMaxUnSpeedLev0_ISig_ "EcoCruisePwtMaxUnSpeedLev0_ISig_5";
BA_ "GenSigCycleTime" SG_ 1208 EcoCruisePwtMaxOvSpeedLev1_ISig_ 100;
BA_ "GenSigCycleTimeActive" SG_ 1208 EcoCruisePwtMaxOvSpeedLev1_ISig_ 100;
BA_ "GenSigStartValue" SG_ 1208 EcoCruisePwtMaxOvSpeedLev1_ISig_ 31;
BA_ "GenSigMaxLatency" SG_ 1208 EcoCruisePwtMaxOvSpeedLev1_ISig_ 1020;
BA_ "SystemSignalLongSymbol" SG_ 1208 EcoCruisePwtMaxOvSpeedLev1_ISig_ "EcoCruisePwtMaxOvSpeedLev1_ISig_5";
BA_ "GenSigCycleTime" SG_ 1208 EcoCruisePwtMaxUnSpeedLev2_ISig_ 100;
BA_ "GenSigCycleTimeActive" SG_ 1208 EcoCruisePwtMaxUnSpeedLev2_ISig_ 100;
BA_ "GenSigStartValue" SG_ 1208 EcoCruisePwtMaxUnSpeedLev2_ISig_ 31;
BA_ "GenSigMaxLatency" SG_ 1208 EcoCruisePwtMaxUnSpeedLev2_ISig_ 1020;
BA_ "SystemSignalLongSymbol" SG_ 1208 EcoCruisePwtMaxUnSpeedLev2_ISig_ "EcoCruisePwtMaxUnSpeedLev2_ISig_5";
BA_ "GenSigCycleTime" SG_ 1208 EcoCruisePwtMaxOvSpeedLev3_ISig_ 100;
BA_ "GenSigCycleTimeActive" SG_ 1208 EcoCruisePwtMaxOvSpeedLev3_ISig_ 100;
BA_ "GenSigStartValue" SG_ 1208 EcoCruisePwtMaxOvSpeedLev3_ISig_ 31;
BA_ "GenSigMaxLatency" SG_ 1208 EcoCruisePwtMaxOvSpeedLev3_ISig_ 1020;
BA_ "SystemSignalLongSymbol" SG_ 1208 EcoCruisePwtMaxOvSpeedLev3_ISig_ "EcoCruisePwtMaxOvSpeedLev3_ISig_5";
BA_ "GenSigCycleTime" SG_ 1208 BatterySOCTLWeak_ISig_5 100;
BA_ "GenSigCycleTimeActive" SG_ 1208 BatterySOCTLWeak_ISig_5 100;
BA_ "GenSigStartValue" SG_ 1208 BatterySOCTLWeak_ISig_5 15;
BA_ "GenSigCycleTime" SG_ 1207 EngineTotalLngConsumed_ISig_5 100;
BA_ "GenSigCycleTimeActive" SG_ 1207 EngineTotalLngConsumed_ISig_5 100;
BA_ "GenSigStartValue" SG_ 1207 EngineTotalLngConsumed_ISig_5 4294967295;
BA_ "GenSigMaxLatency" SG_ 1207 EngineTotalLngConsumed_ISig_5 1000;
BA_ "GenSigCycleTime" SG_ 1207 TotalVehicleDistanceHighRes_ISig 100;
BA_ "GenSigCycleTimeActive" SG_ 1207 TotalVehicleDistanceHighRes_ISig 100;
BA_ "GenSigStartValue" SG_ 1207 TotalVehicleDistanceHighRes_ISig 4294967295;
BA_ "GenSigMaxLatency" SG_ 1207 TotalVehicleDistanceHighRes_ISig 1000;
BA_ "SystemSignalLongSymbol" SG_ 1207 TotalVehicleDistanceHighRes_ISig "TotalVehicleDistanceHighRes_ISig_5";
BA_ "GenSigCycleTime" SG_ 1206 PredictedMileageOfNextPadChg_ISi 100;
BA_ "GenSigCycleTimeActive" SG_ 1206 PredictedMileageOfNextPadChg_ISi 100;
BA_ "GenSigStartValue" SG_ 1206 PredictedMileageOfNextPadChg_ISi 4294967295;
BA_ "GenSigMaxLatency" SG_ 1206 PredictedMileageOfNextPadChg_ISi 1000;
BA_ "SystemSignalLongSymbol" SG_ 1206 PredictedMileageOfNextPadChg_ISi "PredictedMileageOfNextPadChg_ISig_5";
BA_ "GenSigCycleTime" SG_ 1206 EngineRunningTime_ISig_5 100;
BA_ "GenSigCycleTimeActive" SG_ 1206 EngineRunningTime_ISig_5 100;
BA_ "GenSigStartValue" SG_ 1206 EngineRunningTime_ISig_5 4294967295;
BA_ "GenSigMaxLatency" SG_ 1206 EngineRunningTime_ISig_5 1000;
BA_ "GenSigCycleTime" SG_ 1205 TopGearUseDistance_ISig_5 100;
BA_ "GenSigCycleTimeActive" SG_ 1205 TopGearUseDistance_ISig_5 100;
BA_ "GenSigStartValue" SG_ 1205 TopGearUseDistance_ISig_5 4294967295;
BA_ "GenSigMaxLatency" SG_ 1205 TopGearUseDistance_ISig_5 1000;
BA_ "GenSigCycleTime" SG_ 1205 DPFSootLevel_ISig_5 100;
BA_ "GenSigCycleTimeActive" SG_ 1205 DPFSootLevel_ISig_5 100;
BA_ "GenSigStartValue" SG_ 1205 DPFSootLevel_ISig_5 255;
BA_ "GenSigMaxLatency" SG_ 1205 DPFSootLevel_ISig_5 1000;
BA_ "GenSigCycleTime" SG_ 1205 CatalystTankLevel_ISig_5 100;
BA_ "GenSigCycleTimeActive" SG_ 1205 CatalystTankLevel_ISig_5 100;
BA_ "GenSigStartValue" SG_ 1205 CatalystTankLevel_ISig_5 255;
BA_ "GenSigMaxLatency" SG_ 1205 CatalystTankLevel_ISig_5 1000;
BA_ "GenSigCycleTime" SG_ 1205 TransmissionOilTemp_ISig_5 100;
BA_ "GenSigCycleTimeActive" SG_ 1205 TransmissionOilTemp_ISig_5 100;
BA_ "GenSigStartValue" SG_ 1205 TransmissionOilTemp_ISig_5 65535;
BA_ "GenSigMaxLatency" SG_ 1205 TransmissionOilTemp_ISig_5 1000;
BA_REL_ "GenSigFirstTimeoutTime" BU_SG_REL_ IC SG_ 1032 PS_PosLightDoorOpen 3000;
BA_REL_ "GenSigTimeoutTime" BU_SG_REL_ IC SG_ 1032 PS_PosLightDoorOpen 600;
BA_REL_ "GenSigFirstTimeoutTime" BU_SG_REL_ IC SG_ 1032 Trail2TPMMatedStatus 3000;
BA_REL_ "GenSigTimeoutTime" BU_SG_REL_ IC SG_ 1032 Trail2TPMMatedStatus 600;
BA_REL_ "GenSigFirstTimeoutTime" BU_SG_REL_ IC SG_ 1032 Trail1TPMMatedStatus 3000;
BA_REL_ "GenSigTimeoutTime" BU_SG_REL_ IC SG_ 1032 Trail1TPMMatedStatus 600;
BA_REL_ "GenSigFirstTimeoutTime" BU_SG_REL_ IC SG_ 1032 PS_ExtLightFreeWheelInd 3000;
BA_REL_ "GenSigTimeoutTime" BU_SG_REL_ IC SG_ 1032 PS_ExtLightFreeWheelInd 600;
BA_REL_ "GenSigFirstTimeoutTime" BU_SG_REL_ IC SG_ 1237 TruckTPMTireInfo_TireId 48000;
BA_REL_ "GenSigTimeoutTime" BU_SG_REL_ IC SG_ 1237 TruckTPMTireInfo_TireId 1200;
BA_REL_ "GenSigFirstTimeoutTime" BU_SG_REL_ IC SG_ 1237 TruckTPMTireInfo_Pressure 48000;
BA_REL_ "GenSigTimeoutTime" BU_SG_REL_ IC SG_ 1237 TruckTPMTireInfo_Pressure 1200;
BA_REL_ "GenSigFirstTimeoutTime" BU_SG_REL_ IC SG_ 1237 TruckTPMTireInfo_LeakageWarn 48000;
BA_REL_ "GenSigTimeoutTime" BU_SG_REL_ IC SG_ 1237 TruckTPMTireInfo_LeakageWarn 1200;
BA_REL_ "GenSigFirstTimeoutTime" BU_SG_REL_ IC SG_ 1237 TruckTPMTireInfo_Battery 48000;
BA_REL_ "GenSigTimeoutTime" BU_SG_REL_ IC SG_ 1237 TruckTPMTireInfo_Battery 1200;
BA_REL_ "GenSigFirstTimeoutTime" BU_SG_REL_ IC SG_ 1237 TruckTPMTireInfo_PresWarn 48000;
BA_REL_ "GenSigTimeoutTime" BU_SG_REL_ IC SG_ 1237 TruckTPMTireInfo_PresWarn 1200;
BA_REL_ "GenSigFirstTimeoutTime" BU_SG_REL_ IC SG_ 1237 TruckTPMTireInfo_RefPres 48000;
BA_REL_ "GenSigTimeoutTime" BU_SG_REL_ IC SG_ 1237 TruckTPMTireInfo_RefPres 1200;
BA_REL_ "GenSigFirstTimeoutTime" BU_SG_REL_ IC SG_ 1237 Trail1TPMFailure 48000;
BA_REL_ "GenSigTimeoutTime" BU_SG_REL_ IC SG_ 1237 Trail1TPMFailure 1200;
BA_REL_ "GenSigFirstTimeoutTime" BU_SG_REL_ IC SG_ 1237 TruckTPMTireInfo_Temperature 48000;
BA_REL_ "GenSigTimeoutTime" BU_SG_REL_ IC SG_ 1237 TruckTPMTireInfo_Temperature 1200;
BA_REL_ "GenSigFirstTimeoutTime" BU_SG_REL_ IC SG_ 1237 Trail2TPMFailure 48000;
BA_REL_ "GenSigTimeoutTime" BU_SG_REL_ IC SG_ 1237 Trail2TPMFailure 1200;
BA_REL_ "GenSigFirstTimeoutTime" BU_SG_REL_ IC SG_ 1237 TruckTPMTireInfo_Active 48000;
BA_REL_ "GenSigTimeoutTime" BU_SG_REL_ IC SG_ 1237 TruckTPMTireInfo_Active 1200;
BA_REL_ "GenSigFirstTimeoutTime" BU_SG_REL_ IC SG_ 1237 TrckTPMFailure 48000;
BA_REL_ "GenSigTimeoutTime" BU_SG_REL_ IC SG_ 1237 TrckTPMFailure 1200;
BA_REL_ "GenSigFirstTimeoutTime" BU_SG_REL_ IC SG_ 1234 Trail2TPMTireInfo_PresWarn 48000;
BA_REL_ "GenSigTimeoutTime" BU_SG_REL_ IC SG_ 1234 Trail2TPMTireInfo_PresWarn 1200;
BA_REL_ "GenSigFirstTimeoutTime" BU_SG_REL_ IC SG_ 1234 Trail2TPMTireInfo_Pressure 48000;
BA_REL_ "GenSigTimeoutTime" BU_SG_REL_ IC SG_ 1234 Trail2TPMTireInfo_Pressure 1200;
BA_REL_ "GenSigFirstTimeoutTime" BU_SG_REL_ IC SG_ 1234 Trail2TPMTireInfo_TireId 48000;
BA_REL_ "GenSigTimeoutTime" BU_SG_REL_ IC SG_ 1234 Trail2TPMTireInfo_TireId 1200;
BA_REL_ "GenSigFirstTimeoutTime" BU_SG_REL_ IC SG_ 1234 Trail2TPMTireInfo_LeakageWarn 48000;
BA_REL_ "GenSigTimeoutTime" BU_SG_REL_ IC SG_ 1234 Trail2TPMTireInfo_LeakageWarn 1200;
BA_REL_ "GenSigFirstTimeoutTime" BU_SG_REL_ IC SG_ 1234 Trail2TPMTireInfo_Temperature 48000;
BA_REL_ "GenSigTimeoutTime" BU_SG_REL_ IC SG_ 1234 Trail2TPMTireInfo_Temperature 1200;
BA_REL_ "GenSigFirstTimeoutTime" BU_SG_REL_ IC SG_ 1234 Trail2TPMTireInfo_Battery 48000;
BA_REL_ "GenSigTimeoutTime" BU_SG_REL_ IC SG_ 1234 Trail2TPMTireInfo_Battery 1200;
BA_REL_ "GenSigFirstTimeoutTime" BU_SG_REL_ IC SG_ 1234 Trail2TPMTireInfo_Active 48000;
BA_REL_ "GenSigTimeoutTime" BU_SG_REL_ IC SG_ 1234 Trail2TPMTireInfo_Active 1200;
BA_REL_ "GenSigFirstTimeoutTime" BU_SG_REL_ IC SG_ 1234 Trail2TPMTireInfo_RefPres 48000;
BA_REL_ "GenSigTimeoutTime" BU_SG_REL_ IC SG_ 1234 Trail2TPMTireInfo_RefPres 1200;
BA_REL_ "GenSigFirstTimeoutTime" BU_SG_REL_ IC SG_ 1231 Trail1TPMTireInfo_LeakageWarn 48000;
BA_REL_ "GenSigTimeoutTime" BU_SG_REL_ IC SG_ 1231 Trail1TPMTireInfo_LeakageWarn 1200;
BA_REL_ "GenSigFirstTimeoutTime" BU_SG_REL_ IC SG_ 1231 Trail1TPMTireInfo_Temperature 48000;
BA_REL_ "GenSigTimeoutTime" BU_SG_REL_ IC SG_ 1231 Trail1TPMTireInfo_Temperature 1200;
BA_REL_ "GenSigFirstTimeoutTime" BU_SG_REL_ IC SG_ 1231 Trail1TPMTireInfo_TireId 48000;
BA_REL_ "GenSigTimeoutTime" BU_SG_REL_ IC SG_ 1231 Trail1TPMTireInfo_TireId 1200;
BA_REL_ "GenSigFirstTimeoutTime" BU_SG_REL_ IC SG_ 1231 Trail1TPMTireInfo_RefPres 48000;
BA_REL_ "GenSigTimeoutTime" BU_SG_REL_ IC SG_ 1231 Trail1TPMTireInfo_RefPres 1200;
BA_REL_ "GenSigFirstTimeoutTime" BU_SG_REL_ IC SG_ 1231 TPMPosOfWMResponse_Status 48000;
BA_REL_ "GenSigTimeoutTime" BU_SG_REL_ IC SG_ 1231 TPMPosOfWMResponse_Status 1200;
BA_REL_ "GenSigFirstTimeoutTime" BU_SG_REL_ IC SG_ 1231 TPMPosOfWMResponse_TireId 48000;
BA_REL_ "GenSigTimeoutTime" BU_SG_REL_ IC SG_ 1231 TPMPosOfWMResponse_TireId 1200;
BA_REL_ "GenSigFirstTimeoutTime" BU_SG_REL_ IC SG_ 1231 TPMPosOfWMResponse_VehiclePos 48000;
BA_REL_ "GenSigTimeoutTime" BU_SG_REL_ IC SG_ 1231 TPMPosOfWMResponse_VehiclePos 1200;
BA_REL_ "GenSigFirstTimeoutTime" BU_SG_REL_ IC SG_ 1231 Trail1TPMTireInfo_PresWarn 48000;
BA_REL_ "GenSigTimeoutTime" BU_SG_REL_ IC SG_ 1231 Trail1TPMTireInfo_PresWarn 1200;
BA_REL_ "GenSigFirstTimeoutTime" BU_SG_REL_ IC SG_ 1231 Trail1TPMTireInfo_Battery 48000;
BA_REL_ "GenSigTimeoutTime" BU_SG_REL_ IC SG_ 1231 Trail1TPMTireInfo_Battery 1200;
BA_REL_ "GenSigFirstTimeoutTime" BU_SG_REL_ IC SG_ 1231 Trail1TPMTireInfo_Active 48000;
BA_REL_ "GenSigTimeoutTime" BU_SG_REL_ IC SG_ 1231 Trail1TPMTireInfo_Active 1200;
BA_REL_ "GenSigFirstTimeoutTime" BU_SG_REL_ IC SG_ 1231 Trail1TPMTireInfo_Pressure 48000;
BA_REL_ "GenSigTimeoutTime" BU_SG_REL_ IC SG_ 1231 Trail1TPMTireInfo_Pressure 1200;
BA_REL_ "GenSigFirstTimeoutTime" BU_SG_REL_ IC SG_ 1403 TrckTPMThresCfg_AxleNr 24000;
BA_REL_ "GenSigTimeoutTime" BU_SG_REL_ IC SG_ 1403 TrckTPMThresCfg_AxleNr 6000;
BA_REL_ "GenSigFirstTimeoutTime" BU_SG_REL_ IC SG_ 1403 TrckTPMThresCfg_UnderPres 24000;
BA_REL_ "GenSigTimeoutTime" BU_SG_REL_ IC SG_ 1403 TrckTPMThresCfg_UnderPres 6000;
BA_REL_ "GenSigFirstTimeoutTime" BU_SG_REL_ IC SG_ 1403 TruckTPMAxleTireCnfg_Axle5 24000;
BA_REL_ "GenSigTimeoutTime" BU_SG_REL_ IC SG_ 1403 TruckTPMAxleTireCnfg_Axle5 6000;
BA_REL_ "GenSigFirstTimeoutTime" BU_SG_REL_ IC SG_ 1403 TruckTPMAxleTireCnfg_Axle3 24000;
BA_REL_ "GenSigTimeoutTime" BU_SG_REL_ IC SG_ 1403 TruckTPMAxleTireCnfg_Axle3 6000;
BA_REL_ "GenSigFirstTimeoutTime" BU_SG_REL_ IC SG_ 1403 TruckTPMAxleTireCnfg_Axle1 24000;
BA_REL_ "GenSigTimeoutTime" BU_SG_REL_ IC SG_ 1403 TruckTPMAxleTireCnfg_Axle1 6000;
BA_REL_ "GenSigFirstTimeoutTime" BU_SG_REL_ IC SG_ 1403 TrckTPMThresCfg_OverPres 24000;
BA_REL_ "GenSigTimeoutTime" BU_SG_REL_ IC SG_ 1403 TrckTPMThresCfg_OverPres 6000;
BA_REL_ "GenSigFirstTimeoutTime" BU_SG_REL_ IC SG_ 1403 TruckTPMAxleTireCnfg_Axle4 24000;
BA_REL_ "GenSigTimeoutTime" BU_SG_REL_ IC SG_ 1403 TruckTPMAxleTireCnfg_Axle4 6000;
BA_REL_ "GenSigFirstTimeoutTime" BU_SG_REL_ IC SG_ 1403 TrckTPMThresCfg_ExtOverPres 24000;
BA_REL_ "GenSigTimeoutTime" BU_SG_REL_ IC SG_ 1403 TrckTPMThresCfg_ExtOverPres 6000;
BA_REL_ "GenSigFirstTimeoutTime" BU_SG_REL_ IC SG_ 1403 TrckTPMThresCfg_ExtUnderPres 24000;
BA_REL_ "GenSigTimeoutTime" BU_SG_REL_ IC SG_ 1403 TrckTPMThresCfg_ExtUnderPres 6000;
BA_REL_ "GenSigFirstTimeoutTime" BU_SG_REL_ IC SG_ 1403 TruckTPMAxleTireCnfg_Axle2 24000;
BA_REL_ "GenSigTimeoutTime" BU_SG_REL_ IC SG_ 1403 TruckTPMAxleTireCnfg_Axle2 6000;
BA_REL_ "GenSigFirstTimeoutTime" BU_SG_REL_ IC SG_ 1402 Trail2TPMThresCfg_UnderPres 24000;
BA_REL_ "GenSigTimeoutTime" BU_SG_REL_ IC SG_ 1402 Trail2TPMThresCfg_UnderPres 6000;
BA_REL_ "GenSigFirstTimeoutTime" BU_SG_REL_ IC SG_ 1402 Trail2TPMAxleTireCnfg_Axle1 24000;
BA_REL_ "GenSigTimeoutTime" BU_SG_REL_ IC SG_ 1402 Trail2TPMAxleTireCnfg_Axle1 6000;
BA_REL_ "GenSigFirstTimeoutTime" BU_SG_REL_ IC SG_ 1402 Trail2TPMAxleTireCnfg_Axle3 24000;
BA_REL_ "GenSigTimeoutTime" BU_SG_REL_ IC SG_ 1402 Trail2TPMAxleTireCnfg_Axle3 6000;
BA_REL_ "GenSigFirstTimeoutTime" BU_SG_REL_ IC SG_ 1402 Trail2TPMAxleTireCnfg_Axle2 24000;
BA_REL_ "GenSigTimeoutTime" BU_SG_REL_ IC SG_ 1402 Trail2TPMAxleTireCnfg_Axle2 6000;
BA_REL_ "GenSigFirstTimeoutTime" BU_SG_REL_ IC SG_ 1402 Trail2TPMThresCfg_ExtUnderPres 24000;
BA_REL_ "GenSigTimeoutTime" BU_SG_REL_ IC SG_ 1402 Trail2TPMThresCfg_ExtUnderPres 6000;
BA_REL_ "GenSigFirstTimeoutTime" BU_SG_REL_ IC SG_ 1402 Trail2TPMThresCfg_OverPres 24000;
BA_REL_ "GenSigTimeoutTime" BU_SG_REL_ IC SG_ 1402 Trail2TPMThresCfg_OverPres 6000;
BA_REL_ "GenSigFirstTimeoutTime" BU_SG_REL_ IC SG_ 1402 Trail2TPMAxleTireCnfg_Axle4 24000;
BA_REL_ "GenSigTimeoutTime" BU_SG_REL_ IC SG_ 1402 Trail2TPMAxleTireCnfg_Axle4 6000;
BA_REL_ "GenSigFirstTimeoutTime" BU_SG_REL_ IC SG_ 1402 Trail2TPMThresCfg_AxleNr 24000;
BA_REL_ "GenSigTimeoutTime" BU_SG_REL_ IC SG_ 1402 Trail2TPMThresCfg_AxleNr 6000;
BA_REL_ "GenSigFirstTimeoutTime" BU_SG_REL_ IC SG_ 1402 Trail2TPMThresCfg_ExtOverPres 24000;
BA_REL_ "GenSigTimeoutTime" BU_SG_REL_ IC SG_ 1402 Trail2TPMThresCfg_ExtOverPres 6000;
BA_REL_ "GenSigFirstTimeoutTime" BU_SG_REL_ IC SG_ 1402 Trail2TPMAxleTireCnfg_Axle5 24000;
BA_REL_ "GenSigTimeoutTime" BU_SG_REL_ IC SG_ 1402 Trail2TPMAxleTireCnfg_Axle5 6000;
BA_REL_ "GenSigFirstTimeoutTime" BU_SG_REL_ IC SG_ 1401 Trail1TPMAxleTireCnfg_Axle4 24000;
BA_REL_ "GenSigTimeoutTime" BU_SG_REL_ IC SG_ 1401 Trail1TPMAxleTireCnfg_Axle4 6000;
BA_REL_ "GenSigFirstTimeoutTime" BU_SG_REL_ IC SG_ 1401 Trail1TPMThresCfg_UnderPres 24000;
BA_REL_ "GenSigTimeoutTime" BU_SG_REL_ IC SG_ 1401 Trail1TPMThresCfg_UnderPres 6000;
BA_REL_ "GenSigFirstTimeoutTime" BU_SG_REL_ IC SG_ 1401 Trail1TPMAxleTireCnfg_Axle5 24000;
BA_REL_ "GenSigTimeoutTime" BU_SG_REL_ IC SG_ 1401 Trail1TPMAxleTireCnfg_Axle5 6000;
BA_REL_ "GenSigFirstTimeoutTime" BU_SG_REL_ IC SG_ 1401 Trail1TPMAxleTireCnfg_Axle3 24000;
BA_REL_ "GenSigTimeoutTime" BU_SG_REL_ IC SG_ 1401 Trail1TPMAxleTireCnfg_Axle3 6000;
BA_REL_ "GenSigFirstTimeoutTime" BU_SG_REL_ IC SG_ 1401 Trail1TPMThresCfg_OverPres 24000;
BA_REL_ "GenSigTimeoutTime" BU_SG_REL_ IC SG_ 1401 Trail1TPMThresCfg_OverPres 6000;
BA_REL_ "GenSigFirstTimeoutTime" BU_SG_REL_ IC SG_ 1401 Trail1TPMAxleTireCnfg_Axle2 24000;
BA_REL_ "GenSigTimeoutTime" BU_SG_REL_ IC SG_ 1401 Trail1TPMAxleTireCnfg_Axle2 6000;
BA_REL_ "GenSigFirstTimeoutTime" BU_SG_REL_ IC SG_ 1401 Trail1TPMAxleTireCnfg_Axle1 24000;
BA_REL_ "GenSigTimeoutTime" BU_SG_REL_ IC SG_ 1401 Trail1TPMAxleTireCnfg_Axle1 6000;
BA_REL_ "GenSigFirstTimeoutTime" BU_SG_REL_ IC SG_ 1401 Trail1TPMThresCfg_ExtOverPres 24000;
BA_REL_ "GenSigTimeoutTime" BU_SG_REL_ IC SG_ 1401 Trail1TPMThresCfg_ExtOverPres 6000;
BA_REL_ "GenSigFirstTimeoutTime" BU_SG_REL_ IC SG_ 1401 Trail1TPMThresCfg_AxleNr 24000;
BA_REL_ "GenSigTimeoutTime" BU_SG_REL_ IC SG_ 1401 Trail1TPMThresCfg_AxleNr 6000;
BA_REL_ "GenSigFirstTimeoutTime" BU_SG_REL_ IC SG_ 1401 Trail1TPMThresCfg_ExtUnderPres 24000;
BA_REL_ "GenSigTimeoutTime" BU_SG_REL_ IC SG_ 1401 Trail1TPMThresCfg_ExtUnderPres 6000;
BA_REL_ "GenSigFirstTimeoutTime" BU_SG_REL_ IC SG_ 2566909713 Trail4TPMThresCfg_AxleNr 24000;
BA_REL_ "GenSigTimeoutTime" BU_SG_REL_ IC SG_ 2566909713 Trail4TPMThresCfg_AxleNr 6000;
BA_REL_ "GenSigFirstTimeoutTime" BU_SG_REL_ IC SG_ 2566909713 Trail4TPMThresCfg_ExtOverPres 24000;
BA_REL_ "GenSigTimeoutTime" BU_SG_REL_ IC SG_ 2566909713 Trail4TPMThresCfg_ExtOverPres 6000;
BA_REL_ "GenSigFirstTimeoutTime" BU_SG_REL_ IC SG_ 2566909713 Trail4TPMThresCfg_ExtUnderPres 24000;
BA_REL_ "GenSigTimeoutTime" BU_SG_REL_ IC SG_ 2566909713 Trail4TPMThresCfg_ExtUnderPres 6000;
BA_REL_ "GenSigFirstTimeoutTime" BU_SG_REL_ IC SG_ 2566909713 Trail4TPMThresCfg_OverPres 24000;
BA_REL_ "GenSigTimeoutTime" BU_SG_REL_ IC SG_ 2566909713 Trail4TPMThresCfg_OverPres 6000;
BA_REL_ "GenSigFirstTimeoutTime" BU_SG_REL_ IC SG_ 2566909713 Trail4TPMThresCfg_UnderPres 24000;
BA_REL_ "GenSigTimeoutTime" BU_SG_REL_ IC SG_ 2566909713 Trail4TPMThresCfg_UnderPres 6000;
BA_REL_ "GenSigFirstTimeoutTime" BU_SG_REL_ IC SG_ 2566901521 Trail5TPMThresCfg_OverPres 24000;
BA_REL_ "GenSigTimeoutTime" BU_SG_REL_ IC SG_ 2566901521 Trail5TPMThresCfg_OverPres 6000;
BA_REL_ "GenSigFirstTimeoutTime" BU_SG_REL_ IC SG_ 2566901521 Trail5TPMThresCfg_AxleNr 24000;
BA_REL_ "GenSigTimeoutTime" BU_SG_REL_ IC SG_ 2566901521 Trail5TPMThresCfg_AxleNr 6000;
BA_REL_ "GenSigFirstTimeoutTime" BU_SG_REL_ IC SG_ 2566901521 Trail5TPMThresCfg_ExtOverPres 24000;
BA_REL_ "GenSigTimeoutTime" BU_SG_REL_ IC SG_ 2566901521 Trail5TPMThresCfg_ExtOverPres 6000;
BA_REL_ "GenSigFirstTimeoutTime" BU_SG_REL_ IC SG_ 2566901521 Trail5TPMThresCfg_ExtUnderPres 24000;
BA_REL_ "GenSigTimeoutTime" BU_SG_REL_ IC SG_ 2566901521 Trail5TPMThresCfg_ExtUnderPres 6000;
BA_REL_ "GenSigFirstTimeoutTime" BU_SG_REL_ IC SG_ 2566901521 Trail5TPMThresCfg_UnderPres 24000;
BA_REL_ "GenSigTimeoutTime" BU_SG_REL_ IC SG_ 2566901521 Trail5TPMThresCfg_UnderPres 6000;
BA_REL_ "GenSigFirstTimeoutTime" BU_SG_REL_ IC SG_ 2566893329 Trail3TPMThresCfg_UnderPres 24000;
BA_REL_ "GenSigTimeoutTime" BU_SG_REL_ IC SG_ 2566893329 Trail3TPMThresCfg_UnderPres 6000;
BA_REL_ "GenSigFirstTimeoutTime" BU_SG_REL_ IC SG_ 2566893329 Trail3TPMThresCfg_ExtUnderPres 24000;
BA_REL_ "GenSigTimeoutTime" BU_SG_REL_ IC SG_ 2566893329 Trail3TPMThresCfg_ExtUnderPres 6000;
BA_REL_ "GenSigFirstTimeoutTime" BU_SG_REL_ IC SG_ 2566893329 Trail3TPMThresCfg_ExtOverPres 24000;
BA_REL_ "GenSigTimeoutTime" BU_SG_REL_ IC SG_ 2566893329 Trail3TPMThresCfg_ExtOverPres 6000;
BA_REL_ "GenSigFirstTimeoutTime" BU_SG_REL_ IC SG_ 2566893329 Trail3TPMThresCfg_AxleNr 24000;
BA_REL_ "GenSigTimeoutTime" BU_SG_REL_ IC SG_ 2566893329 Trail3TPMThresCfg_AxleNr 6000;
BA_REL_ "GenSigFirstTimeoutTime" BU_SG_REL_ IC SG_ 2566893329 Trail3TPMThresCfg_OverPres 24000;
BA_REL_ "GenSigTimeoutTime" BU_SG_REL_ IC SG_ 2566893329 Trail3TPMThresCfg_OverPres 6000;
BA_REL_ "GenSigFirstTimeoutTime" BU_SG_REL_ IC SG_ 2566885137 Trail5TPMAxleTireCnfg_Axle3 12000;
BA_REL_ "GenSigTimeoutTime" BU_SG_REL_ IC SG_ 2566885137 Trail5TPMAxleTireCnfg_Axle3 3000;
BA_REL_ "GenSigFirstTimeoutTime" BU_SG_REL_ IC SG_ 2566885137 Trail4TPMAxleTireCnfg_Axle1 12000;
BA_REL_ "GenSigTimeoutTime" BU_SG_REL_ IC SG_ 2566885137 Trail4TPMAxleTireCnfg_Axle1 3000;
BA_REL_ "GenSigFirstTimeoutTime" BU_SG_REL_ IC SG_ 2566885137 Trail5TPMAxleTireCnfg_Axle4 12000;
BA_REL_ "GenSigTimeoutTime" BU_SG_REL_ IC SG_ 2566885137 Trail5TPMAxleTireCnfg_Axle4 3000;
BA_REL_ "GenSigFirstTimeoutTime" BU_SG_REL_ IC SG_ 2566885137 Trail3TPMAxleTireCnfg_Axle3 12000;
BA_REL_ "GenSigTimeoutTime" BU_SG_REL_ IC SG_ 2566885137 Trail3TPMAxleTireCnfg_Axle3 3000;
BA_REL_ "GenSigFirstTimeoutTime" BU_SG_REL_ IC SG_ 2566885137 Trail4TPMAxleTireCnfg_Axle5 12000;
BA_REL_ "GenSigTimeoutTime" BU_SG_REL_ IC SG_ 2566885137 Trail4TPMAxleTireCnfg_Axle5 3000;
BA_REL_ "GenSigFirstTimeoutTime" BU_SG_REL_ IC SG_ 2566885137 Trail5TPMAxleTireCnfg_Axle2 12000;
BA_REL_ "GenSigTimeoutTime" BU_SG_REL_ IC SG_ 2566885137 Trail5TPMAxleTireCnfg_Axle2 3000;
BA_REL_ "GenSigFirstTimeoutTime" BU_SG_REL_ IC SG_ 2566885137 Trail4TPMAxleTireCnfg_Axle4 12000;
BA_REL_ "GenSigTimeoutTime" BU_SG_REL_ IC SG_ 2566885137 Trail4TPMAxleTireCnfg_Axle4 3000;
BA_REL_ "GenSigFirstTimeoutTime" BU_SG_REL_ IC SG_ 2566885137 Trail3TPMAxleTireCnfg_Axle2 12000;
BA_REL_ "GenSigTimeoutTime" BU_SG_REL_ IC SG_ 2566885137 Trail3TPMAxleTireCnfg_Axle2 3000;
BA_REL_ "GenSigFirstTimeoutTime" BU_SG_REL_ IC SG_ 2566885137 Trail3TPMAxleTireCnfg_Axle5 12000;
BA_REL_ "GenSigTimeoutTime" BU_SG_REL_ IC SG_ 2566885137 Trail3TPMAxleTireCnfg_Axle5 3000;
BA_REL_ "GenSigFirstTimeoutTime" BU_SG_REL_ IC SG_ 2566885137 Trail5TPMAxleTireCnfg_Axle1 12000;
BA_REL_ "GenSigTimeoutTime" BU_SG_REL_ IC SG_ 2566885137 Trail5TPMAxleTireCnfg_Axle1 3000;
BA_REL_ "GenSigFirstTimeoutTime" BU_SG_REL_ IC SG_ 2566885137 Trail5TPMAxleTireCnfg_Axle5 12000;
BA_REL_ "GenSigTimeoutTime" BU_SG_REL_ IC SG_ 2566885137 Trail5TPMAxleTireCnfg_Axle5 3000;
BA_REL_ "GenSigFirstTimeoutTime" BU_SG_REL_ IC SG_ 2566885137 Trail4TPMAxleTireCnfg_Axle2 12000;
BA_REL_ "GenSigTimeoutTime" BU_SG_REL_ IC SG_ 2566885137 Trail4TPMAxleTireCnfg_Axle2 3000;
BA_REL_ "GenSigFirstTimeoutTime" BU_SG_REL_ IC SG_ 2566885137 Trail3TPMAxleTireCnfg_Axle1 12000;
BA_REL_ "GenSigTimeoutTime" BU_SG_REL_ IC SG_ 2566885137 Trail3TPMAxleTireCnfg_Axle1 3000;
BA_REL_ "GenSigFirstTimeoutTime" BU_SG_REL_ IC SG_ 2566885137 Trail4TPMAxleTireCnfg_Axle3 12000;
BA_REL_ "GenSigTimeoutTime" BU_SG_REL_ IC SG_ 2566885137 Trail4TPMAxleTireCnfg_Axle3 3000;
BA_REL_ "GenSigFirstTimeoutTime" BU_SG_REL_ IC SG_ 2566885137 Trail3TPMAxleTireCnfg_Axle4 12000;
BA_REL_ "GenSigTimeoutTime" BU_SG_REL_ IC SG_ 2566885137 Trail3TPMAxleTireCnfg_Axle4 3000;
BA_REL_ "GenSigFirstTimeoutTime" BU_SG_REL_ IC SG_ 2566876945 Trail3TPMTireInfo_RefPres 4800;
BA_REL_ "GenSigTimeoutTime" BU_SG_REL_ IC SG_ 2566876945 Trail3TPMTireInfo_RefPres 1200;
BA_REL_ "GenSigFirstTimeoutTime" BU_SG_REL_ IC SG_ 2566876945 Trail3TPMTireInfo_Battery 4800;
BA_REL_ "GenSigTimeoutTime" BU_SG_REL_ IC SG_ 2566876945 Trail3TPMTireInfo_Battery 1200;
BA_REL_ "GenSigFirstTimeoutTime" BU_SG_REL_ IC SG_ 2566876945 Trail3TPMFailure 4800;
BA_REL_ "GenSigTimeoutTime" BU_SG_REL_ IC SG_ 2566876945 Trail3TPMFailure 1200;
BA_REL_ "GenSigFirstTimeoutTime" BU_SG_REL_ IC SG_ 2566876945 Trail3TPMTireInfo_Temperature 4800;
BA_REL_ "GenSigTimeoutTime" BU_SG_REL_ IC SG_ 2566876945 Trail3TPMTireInfo_Temperature 1200;
BA_REL_ "GenSigFirstTimeoutTime" BU_SG_REL_ IC SG_ 2566876945 Trail3TPMTireInfo_Pressure 4800;
BA_REL_ "GenSigTimeoutTime" BU_SG_REL_ IC SG_ 2566876945 Trail3TPMTireInfo_Pressure 1200;
BA_REL_ "GenSigFirstTimeoutTime" BU_SG_REL_ IC SG_ 2566876945 Trail5TPMFailure 4800;
BA_REL_ "GenSigTimeoutTime" BU_SG_REL_ IC SG_ 2566876945 Trail5TPMFailure 1200;
BA_REL_ "GenSigFirstTimeoutTime" BU_SG_REL_ IC SG_ 2566876945 Trail3TPMTireInfo_TireId 4800;
BA_REL_ "GenSigTimeoutTime" BU_SG_REL_ IC SG_ 2566876945 Trail3TPMTireInfo_TireId 1200;
BA_REL_ "GenSigFirstTimeoutTime" BU_SG_REL_ IC SG_ 2566876945 Trail3TPMTireInfo_PresWarn 4800;
BA_REL_ "GenSigTimeoutTime" BU_SG_REL_ IC SG_ 2566876945 Trail3TPMTireInfo_PresWarn 1200;
BA_REL_ "GenSigFirstTimeoutTime" BU_SG_REL_ IC SG_ 2566876945 Trail3TPMTireInfo_LeakageWarn 4800;
BA_REL_ "GenSigTimeoutTime" BU_SG_REL_ IC SG_ 2566876945 Trail3TPMTireInfo_LeakageWarn 1200;
BA_REL_ "GenSigFirstTimeoutTime" BU_SG_REL_ IC SG_ 2566876945 Trail4TPMFailure 4800;
BA_REL_ "GenSigTimeoutTime" BU_SG_REL_ IC SG_ 2566876945 Trail4TPMFailure 1200;
BA_REL_ "GenSigFirstTimeoutTime" BU_SG_REL_ IC SG_ 2566876945 Trail3TPMTireInfo_Active 4800;
BA_REL_ "GenSigTimeoutTime" BU_SG_REL_ IC SG_ 2566876945 Trail3TPMTireInfo_Active 1200;
BA_REL_ "GenSigFirstTimeoutTime" BU_SG_REL_ IC SG_ 2566868753 Trail5TPMTireInfo_TireId 4800;
BA_REL_ "GenSigTimeoutTime" BU_SG_REL_ IC SG_ 2566868753 Trail5TPMTireInfo_TireId 1200;
BA_REL_ "GenSigFirstTimeoutTime" BU_SG_REL_ IC SG_ 2566868753 Trail5TPMTireInfo_LeakageWarn 4800;
BA_REL_ "GenSigTimeoutTime" BU_SG_REL_ IC SG_ 2566868753 Trail5TPMTireInfo_LeakageWarn 1200;
BA_REL_ "GenSigFirstTimeoutTime" BU_SG_REL_ IC SG_ 2566868753 Trail5TPMTireInfo_RefPres 4800;
BA_REL_ "GenSigTimeoutTime" BU_SG_REL_ IC SG_ 2566868753 Trail5TPMTireInfo_RefPres 1200;
BA_REL_ "GenSigFirstTimeoutTime" BU_SG_REL_ IC SG_ 2566868753 Trail5TPMTireInfo_Pressure 4800;
BA_REL_ "GenSigTimeoutTime" BU_SG_REL_ IC SG_ 2566868753 Trail5TPMTireInfo_Pressure 1200;
BA_REL_ "GenSigFirstTimeoutTime" BU_SG_REL_ IC SG_ 2566868753 Trail5TPMTireInfo_PresWarn 4800;
BA_REL_ "GenSigTimeoutTime" BU_SG_REL_ IC SG_ 2566868753 Trail5TPMTireInfo_PresWarn 1200;
BA_REL_ "GenSigFirstTimeoutTime" BU_SG_REL_ IC SG_ 2566868753 Trail5TPMTireInfo_Temperature 4800;
BA_REL_ "GenSigTimeoutTime" BU_SG_REL_ IC SG_ 2566868753 Trail5TPMTireInfo_Temperature 1200;
BA_REL_ "GenSigFirstTimeoutTime" BU_SG_REL_ IC SG_ 2566868753 Trail5TPMTireInfo_Battery 4800;
BA_REL_ "GenSigTimeoutTime" BU_SG_REL_ IC SG_ 2566868753 Trail5TPMTireInfo_Battery 1200;
BA_REL_ "GenSigFirstTimeoutTime" BU_SG_REL_ IC SG_ 2566868753 Trail5TPMTireInfo_Active 4800;
BA_REL_ "GenSigTimeoutTime" BU_SG_REL_ IC SG_ 2566868753 Trail5TPMTireInfo_Active 1200;
BA_REL_ "GenSigFirstTimeoutTime" BU_SG_REL_ IC SG_ 2566860305 Trail4TPMTireInfo_LeakageWarn 4800;
BA_REL_ "GenSigTimeoutTime" BU_SG_REL_ IC SG_ 2566860305 Trail4TPMTireInfo_LeakageWarn 1200;
BA_REL_ "GenSigFirstTimeoutTime" BU_SG_REL_ IC SG_ 2566860305 Trail4TPMTireInfo_Battery 4800;
BA_REL_ "GenSigTimeoutTime" BU_SG_REL_ IC SG_ 2566860305 Trail4TPMTireInfo_Battery 1200;
BA_REL_ "GenSigFirstTimeoutTime" BU_SG_REL_ IC SG_ 2566860305 Trail4TPMTireInfo_RefPres 4800;
BA_REL_ "GenSigTimeoutTime" BU_SG_REL_ IC SG_ 2566860305 Trail4TPMTireInfo_RefPres 1200;
BA_REL_ "GenSigFirstTimeoutTime" BU_SG_REL_ IC SG_ 2566860305 Trail4TPMTireInfo_Pressure 4800;
BA_REL_ "GenSigTimeoutTime" BU_SG_REL_ IC SG_ 2566860305 Trail4TPMTireInfo_Pressure 1200;
BA_REL_ "GenSigFirstTimeoutTime" BU_SG_REL_ IC SG_ 2566860305 Trail4TPMTireInfo_Active 4800;
BA_REL_ "GenSigTimeoutTime" BU_SG_REL_ IC SG_ 2566860305 Trail4TPMTireInfo_Active 1200;
BA_REL_ "GenSigFirstTimeoutTime" BU_SG_REL_ IC SG_ 2566860305 Trail4TPMTireInfo_TireId 4800;
BA_REL_ "GenSigTimeoutTime" BU_SG_REL_ IC SG_ 2566860305 Trail4TPMTireInfo_TireId 1200;
BA_REL_ "GenSigFirstTimeoutTime" BU_SG_REL_ IC SG_ 2566860305 Trail4TPMTireInfo_Temperature 4800;
BA_REL_ "GenSigTimeoutTime" BU_SG_REL_ IC SG_ 2566860305 Trail4TPMTireInfo_Temperature 1200;
BA_REL_ "GenSigFirstTimeoutTime" BU_SG_REL_ IC SG_ 2566860305 Trail4TPMTireInfo_PresWarn 4800;
BA_REL_ "GenSigTimeoutTime" BU_SG_REL_ IC SG_ 2566860305 Trail4TPMTireInfo_PresWarn 1200;
BA_REL_ "GenSigFirstTimeoutTime" BU_SG_REL_ IC SG_ 2566881297 Trail4TPMMatedStatus 3000;
BA_REL_ "GenSigTimeoutTime" BU_SG_REL_ IC SG_ 2566881297 Trail4TPMMatedStatus 600;
BA_REL_ "GenSigFirstTimeoutTime" BU_SG_REL_ IC SG_ 2566881297 Trail5TPMMatedStatus 3000;
BA_REL_ "GenSigTimeoutTime" BU_SG_REL_ IC SG_ 2566881297 Trail5TPMMatedStatus 600;
BA_REL_ "GenSigFirstTimeoutTime" BU_SG_REL_ IC SG_ 2566881297 Trail3TPMMatedStatus 3000;
BA_REL_ "GenSigTimeoutTime" BU_SG_REL_ IC SG_ 2566881297 Trail3TPMMatedStatus 600;
BA_REL_ "GenSigFirstTimeoutTime" BU_SG_REL_ IC SG_ 395 XPRGSystemCap_AllowedInfInhibit_ 3000;
BA_REL_ "GenSigTimeoutTime" BU_SG_REL_ IC SG_ 395 XPRGSystemCap_AllowedInfInhibit_ 300;
BA_REL_ "GenSigFirstTimeoutTime" BU_SG_REL_ IC SG_ 395 XPRGSystemCap_Priority_ISig_5 3000;
BA_REL_ "GenSigTimeoutTime" BU_SG_REL_ IC SG_ 395 XPRGSystemCap_Priority_ISig_5 300;
BA_REL_ "GenSigFirstTimeoutTime" BU_SG_REL_ SCIM SG_ 395 DRLOverride_DeviceIndication 3000;
BA_REL_ "GenSigTimeoutTime" BU_SG_REL_ SCIM SG_ 395 DRLOverride_DeviceIndication 300;
BA_REL_ "GenSigFirstTimeoutTime" BU_SG_REL_ IC SG_ 395 PS_DRLOverride 3000;
BA_REL_ "GenSigTimeoutTime" BU_SG_REL_ IC SG_ 395 PS_DRLOverride 300;
BA_REL_ "GenSigFirstTimeoutTime" BU_SG_REL_ IC SG_ 395 PS_Dippedbeam 3000;
BA_REL_ "GenSigTimeoutTime" BU_SG_REL_ IC SG_ 395 PS_Dippedbeam 300;
BA_REL_ "GenSigFirstTimeoutTime" BU_SG_REL_ IC SG_ 395 XPRGSystemCap_AllowedPBApp_ISig_ 3000;
BA_REL_ "GenSigTimeoutTime" BU_SG_REL_ IC SG_ 395 XPRGSystemCap_AllowedPBApp_ISig_ 300;
BA_REL_ "GenSigFirstTimeoutTime" BU_SG_REL_ IC SG_ 395 XPRGSystemCap_AllowedRelInhibit_ 3000;
BA_REL_ "GenSigTimeoutTime" BU_SG_REL_ IC SG_ 395 XPRGSystemCap_AllowedRelInhibit_ 300;
BA_REL_ "GenSigFirstTimeoutTime" BU_SG_REL_ IC SG_ 395 XPRGSystemCap_CRC_ISig_5 3000;
BA_REL_ "GenSigTimeoutTime" BU_SG_REL_ IC SG_ 395 XPRGSystemCap_CRC_ISig_5 300;
BA_REL_ "GenSigFirstTimeoutTime" BU_SG_REL_ IC SG_ 395 XPRGSystemCap_AllowedInflation_I 3000;
BA_REL_ "GenSigTimeoutTime" BU_SG_REL_ IC SG_ 395 XPRGSystemCap_AllowedInflation_I 300;
BA_REL_ "GenSigFirstTimeoutTime" BU_SG_REL_ IC SG_ 395 XPRGSystemCap_AllowedGradCtrlTl_ 3000;
BA_REL_ "GenSigTimeoutTime" BU_SG_REL_ IC SG_ 395 XPRGSystemCap_AllowedGradCtrlTl_ 300;
BA_REL_ "GenSigFirstTimeoutTime" BU_SG_REL_ IC SG_ 395 PS_DRL 3000;
BA_REL_ "GenSigTimeoutTime" BU_SG_REL_ IC SG_ 395 PS_DRL 300;
BA_REL_ "GenSigFirstTimeoutTime" BU_SG_REL_ IC SG_ 395 XPRGSystemCap_AllowedGradCtrlTc_ 3000;
BA_REL_ "GenSigTimeoutTime" BU_SG_REL_ IC SG_ 395 XPRGSystemCap_AllowedGradCtrlTc_ 300;
BA_REL_ "GenSigFirstTimeoutTime" BU_SG_REL_ IC SG_ 395 XPRGSystemCap_AllowedPBRel_ISig_ 3000;
BA_REL_ "GenSigTimeoutTime" BU_SG_REL_ IC SG_ 395 XPRGSystemCap_AllowedPBRel_ISig_ 300;
BA_REL_ "GenSigFirstTimeoutTime" BU_SG_REL_ IC SG_ 395 XPRGSystemCap_AllowedDeflation_I 3000;
BA_REL_ "GenSigTimeoutTime" BU_SG_REL_ IC SG_ 395 XPRGSystemCap_AllowedDeflation_I 300;
BA_REL_ "GenSigFirstTimeoutTime" BU_SG_REL_ IC SG_ 395 XPRGSystemCap_SqC_ISig_5 3000;
BA_REL_ "GenSigTimeoutTime" BU_SG_REL_ IC SG_ 395 XPRGSystemCap_SqC_ISig_5 300;
BA_REL_ "GenSigFirstTimeoutTime" BU_SG_REL_ CCM SG_ 1215 ESSTmp 24000;
BA_REL_ "GenSigTimeoutTime" BU_SG_REL_ CCM SG_ 1215 ESSTmp 6000;
BA_REL_ "GenSigFirstTimeoutTime" BU_SG_REL_ CCM SG_ 1215 ESSPmpSpd 24000;
BA_REL_ "GenSigTimeoutTime" BU_SG_REL_ CCM SG_ 1215 ESSPmpSpd 6000;
BA_REL_ "GenSigFirstTimeoutTime" BU_SG_REL_ IC SG_ 1215 ServiceBrakeAirPrsCircuit1_ISig_ 24000;
BA_REL_ "GenSigTimeoutTime" BU_SG_REL_ IC SG_ 1215 ServiceBrakeAirPrsCircuit1_ISig_ 6000;
BA_REL_ "GenSigFirstTimeoutTime" BU_SG_REL_ CCM SG_ 1215 ESSTmpTrgt 24000;
BA_REL_ "GenSigTimeoutTime" BU_SG_REL_ CCM SG_ 1215 ESSTmpTrgt 6000;
BA_REL_ "GenSigFirstTimeoutTime" BU_SG_REL_ CCM SG_ 1215 ESSClntTmp 24000;
BA_REL_ "GenSigTimeoutTime" BU_SG_REL_ CCM SG_ 1215 ESSClntTmp 6000;
BA_REL_ "GenSigFirstTimeoutTime" BU_SG_REL_ CCM SG_ 1215 EMPmpSpd 24000;
BA_REL_ "GenSigTimeoutTime" BU_SG_REL_ CCM SG_ 1215 EMPmpSpd 6000;
BA_REL_ "GenSigFirstTimeoutTime" BU_SG_REL_ IC SG_ 1215 ServiceBrakeAirPrsCircuit2_ISig_ 24000;
BA_REL_ "GenSigTimeoutTime" BU_SG_REL_ IC SG_ 1215 ServiceBrakeAirPrsCircuit2_ISig_ 6000;
BA_REL_ "GenSigFirstTimeoutTime" BU_SG_REL_ IC SG_ 907 Trailer5GeometricData_Index_ISig 12000;
BA_REL_ "GenSigTimeoutTime" BU_SG_REL_ IC SG_ 907 Trailer5GeometricData_Index_ISig 3000;
BA_REL_ "GenSigFirstTimeoutTime" BU_SG_REL_ IC SG_ 907 Trailer5GeometricData_Content_IS 12000;
BA_REL_ "GenSigTimeoutTime" BU_SG_REL_ IC SG_ 907 Trailer5GeometricData_Content_IS 3000;
BA_REL_ "GenSigFirstTimeoutTime" BU_SG_REL_ IC SG_ 906 Trailer3GeometricData_Index_ISig 12000;
BA_REL_ "GenSigTimeoutTime" BU_SG_REL_ IC SG_ 906 Trailer3GeometricData_Index_ISig 3000;
BA_REL_ "GenSigFirstTimeoutTime" BU_SG_REL_ IC SG_ 906 Trailer1GeometricData_Content_IS 12000;
BA_REL_ "GenSigTimeoutTime" BU_SG_REL_ IC SG_ 906 Trailer1GeometricData_Content_IS 3000;
BA_REL_ "GenSigFirstTimeoutTime" BU_SG_REL_ IC SG_ 906 Trailer2GeometricData_Index_ISig 12000;
BA_REL_ "GenSigTimeoutTime" BU_SG_REL_ IC SG_ 906 Trailer2GeometricData_Index_ISig 3000;
BA_REL_ "GenSigFirstTimeoutTime" BU_SG_REL_ IC SG_ 906 Trailer4GeometricData_Index_ISig 12000;
BA_REL_ "GenSigTimeoutTime" BU_SG_REL_ IC SG_ 906 Trailer4GeometricData_Index_ISig 3000;
BA_REL_ "GenSigFirstTimeoutTime" BU_SG_REL_ IC SG_ 906 Trailer3GeometricData_Content_IS 12000;
BA_REL_ "GenSigTimeoutTime" BU_SG_REL_ IC SG_ 906 Trailer3GeometricData_Content_IS 3000;
BA_REL_ "GenSigFirstTimeoutTime" BU_SG_REL_ IC SG_ 906 Trailer2GeometricData_Content_IS 12000;
BA_REL_ "GenSigTimeoutTime" BU_SG_REL_ IC SG_ 906 Trailer2GeometricData_Content_IS 3000;
BA_REL_ "GenSigFirstTimeoutTime" BU_SG_REL_ IC SG_ 906 Trailer4GeometricData_Content_IS 12000;
BA_REL_ "GenSigTimeoutTime" BU_SG_REL_ IC SG_ 906 Trailer4GeometricData_Content_IS 3000;
BA_REL_ "GenSigFirstTimeoutTime" BU_SG_REL_ IC SG_ 906 Trailer1GeometricData_Index_ISig 12000;
BA_REL_ "GenSigTimeoutTime" BU_SG_REL_ IC SG_ 906 Trailer1GeometricData_Index_ISig 3000;
BA_REL_ "GenSigFirstTimeoutTime" BU_SG_REL_ IC SG_ 870 FrontAxle2Load_ISig_5 6000;
BA_REL_ "GenSigTimeoutTime" BU_SG_REL_ IC SG_ 870 FrontAxle2Load_ISig_5 1500;
BA_REL_ "GenSigFirstTimeoutTime" BU_SG_REL_ IC SG_ 870 TagAxleLoad_ISig_5 6000;
BA_REL_ "GenSigTimeoutTime" BU_SG_REL_ IC SG_ 870 TagAxleLoad_ISig_5 1500;
BA_REL_ "GenSigFirstTimeoutTime" BU_SG_REL_ IC SG_ 870 PusherAxleLoad_ISig_5 6000;
BA_REL_ "GenSigTimeoutTime" BU_SG_REL_ IC SG_ 870 PusherAxleLoad_ISig_5 1500;
BA_REL_ "GenSigFirstTimeoutTime" BU_SG_REL_ IC SG_ 870 FrontAxle1Load_ISig_5 6000;
BA_REL_ "GenSigTimeoutTime" BU_SG_REL_ IC SG_ 870 FrontAxle1Load_ISig_5 1500;
BA_REL_ "GenSigFirstTimeoutTime" BU_SG_REL_ IC SG_ 698 Trailer1LiftAxle2Pos_ISig_5 3000;
BA_REL_ "GenSigTimeoutTime" BU_SG_REL_ IC SG_ 698 Trailer1LiftAxle2Pos_ISig_5 600;
BA_REL_ "GenSigFirstTimeoutTime" BU_SG_REL_ IC SG_ 698 Trailer5LiftAxle1Pos_ISig_5 3000;
BA_REL_ "GenSigTimeoutTime" BU_SG_REL_ IC SG_ 698 Trailer5LiftAxle1Pos_ISig_5 600;
BA_REL_ "GenSigFirstTimeoutTime" BU_SG_REL_ IC SG_ 698 MaxEngineCoolingCapacity_Rqst 3000;
BA_REL_ "GenSigTimeoutTime" BU_SG_REL_ IC SG_ 698 MaxEngineCoolingCapacity_Rqst 600;
BA_REL_ "GenSigFirstTimeoutTime" BU_SG_REL_ IC SG_ 698 Trailer2LiftAxle2Pos_ISig_5 3000;
BA_REL_ "GenSigTimeoutTime" BU_SG_REL_ IC SG_ 698 Trailer2LiftAxle2Pos_ISig_5 600;
BA_REL_ "GenSigFirstTimeoutTime" BU_SG_REL_ IC SG_ 698 Trailer4LiftAxle2Pos_ISig_5 3000;
BA_REL_ "GenSigTimeoutTime" BU_SG_REL_ IC SG_ 698 Trailer4LiftAxle2Pos_ISig_5 600;
BA_REL_ "GenSigFirstTimeoutTime" BU_SG_REL_ IC SG_ 698 Trailer2LiftAxle1Pos_ISig_5 3000;
BA_REL_ "GenSigTimeoutTime" BU_SG_REL_ IC SG_ 698 Trailer2LiftAxle1Pos_ISig_5 600;
BA_REL_ "GenSigFirstTimeoutTime" BU_SG_REL_ IC SG_ 698 Trailer1LiftAxle1Pos_ISig_5 3000;
BA_REL_ "GenSigTimeoutTime" BU_SG_REL_ IC SG_ 698 Trailer1LiftAxle1Pos_ISig_5 600;
BA_REL_ "GenSigFirstTimeoutTime" BU_SG_REL_ IC SG_ 698 RainSensorStatus 3000;
BA_REL_ "GenSigTimeoutTime" BU_SG_REL_ IC SG_ 698 RainSensorStatus 600;
BA_REL_ "GenSigFirstTimeoutTime" BU_SG_REL_ IC SG_ 698 Trailer4LiftAxle1Pos_ISig_5 3000;
BA_REL_ "GenSigTimeoutTime" BU_SG_REL_ IC SG_ 698 Trailer4LiftAxle1Pos_ISig_5 600;
BA_REL_ "GenSigFirstTimeoutTime" BU_SG_REL_ IC SG_ 698 Trailer3LiftAxle2Pos_ISig_5 3000;
BA_REL_ "GenSigTimeoutTime" BU_SG_REL_ IC SG_ 698 Trailer3LiftAxle2Pos_ISig_5 600;
BA_REL_ "GenSigFirstTimeoutTime" BU_SG_REL_ IC SG_ 698 Trailer5LiftAxle2Pos_ISig_5 3000;
BA_REL_ "GenSigTimeoutTime" BU_SG_REL_ IC SG_ 698 Trailer5LiftAxle2Pos_ISig_5 600;
BA_REL_ "GenSigFirstTimeoutTime" BU_SG_REL_ IC SG_ 698 Trailer3LiftAxle1Pos_ISig_5 3000;
BA_REL_ "GenSigTimeoutTime" BU_SG_REL_ IC SG_ 698 Trailer3LiftAxle1Pos_ISig_5 600;
BA_REL_ "GenSigFirstTimeoutTime" BU_SG_REL_ SCIM SG_ 157 ChangeKneelACK_ISig_5 3000;
BA_REL_ "GenSigTimeoutTime" BU_SG_REL_ SCIM SG_ 157 ChangeKneelACK_ISig_5 120;
BA_REL_ "GenSigFirstTimeoutTime" BU_SG_REL_ IC SG_ 157 InteriorLightDimming_rqst 3000;
BA_REL_ "GenSigTimeoutTime" BU_SG_REL_ IC SG_ 157 InteriorLightDimming_rqst 120;
BA_REL_ "GenSigFirstTimeoutTime" BU_SG_REL_ IC SG_ 157 DirectionIndication_cmd 3000;
BA_REL_ "GenSigTimeoutTime" BU_SG_REL_ IC SG_ 157 DirectionIndication_cmd 120;
BA_REL_ "GenSigFirstTimeoutTime" BU_SG_REL_ SCIM SG_ 157 RampLevelRequestACK_ISig_5 3000;
BA_REL_ "GenSigTimeoutTime" BU_SG_REL_ SCIM SG_ 157 RampLevelRequestACK_ISig_5 120;
BA_REL_ "GenSigFirstTimeoutTime" BU_SG_REL_ SCIM SG_ 157 LoadDistributionSelected_ISig_5 3000;
BA_REL_ "GenSigTimeoutTime" BU_SG_REL_ SCIM SG_ 157 LoadDistributionSelected_ISig_5 120;
BA_REL_ "GenSigFirstTimeoutTime" BU_SG_REL_ SCIM SG_ 157 HeightAdjustmentAllowed_ISig_5 3000;
BA_REL_ "GenSigTimeoutTime" BU_SG_REL_ SCIM SG_ 157 HeightAdjustmentAllowed_ISig_5 120;
BA_REL_ "GenSigFirstTimeoutTime" BU_SG_REL_ SCIM SG_ 157 AirDumpStatus_ISig_5 3000;
BA_REL_ "GenSigTimeoutTime" BU_SG_REL_ SCIM SG_ 157 AirDumpStatus_ISig_5 120;
BA_REL_ "GenSigFirstTimeoutTime" BU_SG_REL_ SCIM SG_ 157 KneelingStatusHMI_ISig_5 3000;
BA_REL_ "GenSigTimeoutTime" BU_SG_REL_ SCIM SG_ 157 KneelingStatusHMI_ISig_5 120;
BA_REL_ "GenSigFirstTimeoutTime" BU_SG_REL_ SCIM SG_ 157 BackToDriveReqACK_ISig_5 3000;
BA_REL_ "GenSigTimeoutTime" BU_SG_REL_ SCIM SG_ 157 BackToDriveReqACK_ISig_5 120;
BA_REL_ "GenSigFirstTimeoutTime" BU_SG_REL_ SCIM SG_ 157 LoadDistributionFuncSelected_ISi 3000;
BA_REL_ "GenSigTimeoutTime" BU_SG_REL_ SCIM SG_ 157 LoadDistributionFuncSelected_ISi 120;
BA_REL_ "GenSigFirstTimeoutTime" BU_SG_REL_ SCIM SG_ 157 StopLevelChangeAck_ISig_5 3000;
BA_REL_ "GenSigTimeoutTime" BU_SG_REL_ SCIM SG_ 157 StopLevelChangeAck_ISig_5 120;
BA_REL_ "GenSigFirstTimeoutTime" BU_SG_REL_ SCIM SG_ 157 RampLevelStorageAck_ISig_5 3000;
BA_REL_ "GenSigTimeoutTime" BU_SG_REL_ SCIM SG_ 157 RampLevelStorageAck_ISig_5 120;
BA_REL_ "GenSigFirstTimeoutTime" BU_SG_REL_ SCIM SG_ 157 FerryFunctionSwitchChangeACK_ISi 3000;
BA_REL_ "GenSigTimeoutTime" BU_SG_REL_ SCIM SG_ 157 FerryFunctionSwitchChangeACK_ISi 120;
BA_REL_ "GenSigFirstTimeoutTime" BU_SG_REL_ IC SG_ 157 LiftAxle1RequestResponse 3000;
BA_REL_ "GenSigTimeoutTime" BU_SG_REL_ IC SG_ 157 LiftAxle1RequestResponse 120;
BA_REL_ "GenSigFirstTimeoutTime" BU_SG_REL_ SCIM SG_ 157 ECSStandbyAllowed_ISig_5 3000;
BA_REL_ "GenSigTimeoutTime" BU_SG_REL_ SCIM SG_ 157 ECSStandbyAllowed_ISig_5 120;
BA_REL_ "GenSigFirstTimeoutTime" BU_SG_REL_ SCIM SG_ 157 RideHeightStorageAck_ISig_5 3000;
BA_REL_ "GenSigTimeoutTime" BU_SG_REL_ SCIM SG_ 157 RideHeightStorageAck_ISig_5 120;
BA_REL_ "GenSigFirstTimeoutTime" BU_SG_REL_ IC SG_ 157 IntLightMode_CoreRqst_EventFlag 3000;
BA_REL_ "GenSigTimeoutTime" BU_SG_REL_ IC SG_ 157 IntLightMode_CoreRqst_EventFlag 120;
BA_REL_ "GenSigFirstTimeoutTime" BU_SG_REL_ IC SG_ 157 IntLightMode_CoreRqst_IL_Mode 3000;
BA_REL_ "GenSigTimeoutTime" BU_SG_REL_ IC SG_ 157 IntLightMode_CoreRqst_IL_Mode 120;
BA_REL_ "GenSigFirstTimeoutTime" BU_SG_REL_ CCM SG_ 869 CoolantPumpEngagementStatus_ISig 6000;
BA_REL_ "GenSigTimeoutTime" BU_SG_REL_ CCM SG_ 869 CoolantPumpEngagementStatus_ISig 1500;
BA_REL_ "GenSigFirstTimeoutTime" BU_SG_REL_ IC SG_ 869 CoolantTempGaugeAdjustment_ISig_ 3000;
BA_REL_ "GenSigTimeoutTime" BU_SG_REL_ IC SG_ 869 CoolantTempGaugeAdjustment_ISig_ 1500;
BA_REL_ "GenSigFirstTimeoutTime" BU_SG_REL_ IC SG_ 869 EngineTotalFuelConsumed_ISig_5 6000;
BA_REL_ "GenSigTimeoutTime" BU_SG_REL_ IC SG_ 869 EngineTotalFuelConsumed_ISig_5 1500;
BA_REL_ "GenSigFirstTimeoutTime" BU_SG_REL_ CCM SG_ 869 EngineCoolingFanSpeed_ISig_5 6000;
BA_REL_ "GenSigTimeoutTime" BU_SG_REL_ CCM SG_ 869 EngineCoolingFanSpeed_ISig_5 1500;
BA_REL_ "GenSigFirstTimeoutTime" BU_SG_REL_ IC SG_ 1209 LngTank2RemainingGasVolume_ISig_ 24000;
BA_REL_ "GenSigTimeoutTime" BU_SG_REL_ IC SG_ 1209 LngTank2RemainingGasVolume_ISig_ 6000;
BA_REL_ "GenSigFirstTimeoutTime" BU_SG_REL_ IC SG_ 1209 LNGRestrictionStatus_Spare4_ISig 24000;
BA_REL_ "GenSigTimeoutTime" BU_SG_REL_ IC SG_ 1209 LNGRestrictionStatus_Spare4_ISig 6000;
BA_REL_ "GenSigFirstTimeoutTime" BU_SG_REL_ IC SG_ 1209 LNGRestrictionStatus_V1Closed_IS 24000;
BA_REL_ "GenSigTimeoutTime" BU_SG_REL_ IC SG_ 1209 LNGRestrictionStatus_V1Closed_IS 6000;
BA_REL_ "GenSigFirstTimeoutTime" BU_SG_REL_ IC SG_ 1209 LNGRestrictionStatus_Spare3_ISig 24000;
BA_REL_ "GenSigTimeoutTime" BU_SG_REL_ IC SG_ 1209 LNGRestrictionStatus_Spare3_ISig 6000;
BA_REL_ "GenSigFirstTimeoutTime" BU_SG_REL_ IC SG_ 1209 LngTank2WarnStat_ISig_5 24000;
BA_REL_ "GenSigTimeoutTime" BU_SG_REL_ IC SG_ 1209 LngTank2WarnStat_ISig_5 6000;
BA_REL_ "GenSigFirstTimeoutTime" BU_SG_REL_ IC SG_ 1209 LNGRestrictionStatus_Spare2_ISig 24000;
BA_REL_ "GenSigTimeoutTime" BU_SG_REL_ IC SG_ 1209 LNGRestrictionStatus_Spare2_ISig 6000;
BA_REL_ "GenSigFirstTimeoutTime" BU_SG_REL_ IC SG_ 1209 LngTank1RemainingGasVolume_ISig_ 24000;
BA_REL_ "GenSigTimeoutTime" BU_SG_REL_ IC SG_ 1209 LngTank1RemainingGasVolume_ISig_ 6000;
BA_REL_ "GenSigFirstTimeoutTime" BU_SG_REL_ IC SG_ 1209 LngSystemReadinessStat_ISig_5 24000;
BA_REL_ "GenSigTimeoutTime" BU_SG_REL_ IC SG_ 1209 LngSystemReadinessStat_ISig_5 6000;
BA_REL_ "GenSigFirstTimeoutTime" BU_SG_REL_ IC SG_ 1209 LNGOperatorInducementReason_ISig 24000;
BA_REL_ "GenSigTimeoutTime" BU_SG_REL_ IC SG_ 1209 LNGOperatorInducementReason_ISig 6000;
BA_REL_ "GenSigFirstTimeoutTime" BU_SG_REL_ IC SG_ 1209 LNGRestrictionStatus_Spare1_ISig 24000;
BA_REL_ "GenSigTimeoutTime" BU_SG_REL_ IC SG_ 1209 LNGRestrictionStatus_Spare1_ISig 6000;
BA_REL_ "GenSigFirstTimeoutTime" BU_SG_REL_ IC SG_ 1209 LNGRestrictionStatus_V2Closed_IS 24000;
BA_REL_ "GenSigTimeoutTime" BU_SG_REL_ IC SG_ 1209 LNGRestrictionStatus_V2Closed_IS 6000;
BA_REL_ "GenSigFirstTimeoutTime" BU_SG_REL_ IC SG_ 1209 LngTank1WarnStat_ISig_5 24000;
BA_REL_ "GenSigTimeoutTime" BU_SG_REL_ IC SG_ 1209 LngTank1WarnStat_ISig_5 6000;
BA_REL_ "GenSigFirstTimeoutTime" BU_SG_REL_ IC SG_ 1209 LNGTimeToVent_ISig_5 24000;
BA_REL_ "GenSigTimeoutTime" BU_SG_REL_ IC SG_ 1209 LNGTimeToVent_ISig_5 6000;
BA_REL_ "GenSigFirstTimeoutTime" BU_SG_REL_ IC SG_ 1209 LNGLevel_ISig_5 24000;
BA_REL_ "GenSigTimeoutTime" BU_SG_REL_ IC SG_ 1209 LNGLevel_ISig_5 6000;
BA_REL_ "GenSigFirstTimeoutTime" BU_SG_REL_ IC SG_ 1209 LNGRestrictionStatus_SInfo_ISig_ 24000;
BA_REL_ "GenSigTimeoutTime" BU_SG_REL_ IC SG_ 1209 LNGRestrictionStatus_SInfo_ISig_ 6000;
BA_REL_ "GenSigFirstTimeoutTime" BU_SG_REL_ IC SG_ 1209 LngGspWarnStat_ISig_5 24000;
BA_REL_ "GenSigTimeoutTime" BU_SG_REL_ IC SG_ 1209 LngGspWarnStat_ISig_5 6000;
BA_REL_ "GenSigFirstTimeoutTime" BU_SG_REL_ IC SG_ 1208 EcoCruisePwtMaxUnSpeedLev3_ISig_ 24000;
BA_REL_ "GenSigTimeoutTime" BU_SG_REL_ IC SG_ 1208 EcoCruisePwtMaxUnSpeedLev3_ISig_ 6000;
BA_REL_ "GenSigFirstTimeoutTime" BU_SG_REL_ IC SG_ 1208 EcoCruisePwtMaxOvSpeedLev0_ISig_ 24000;
BA_REL_ "GenSigTimeoutTime" BU_SG_REL_ IC SG_ 1208 EcoCruisePwtMaxOvSpeedLev0_ISig_ 6000;
BA_REL_ "GenSigFirstTimeoutTime" BU_SG_REL_ IC SG_ 1208 EcoCruisePwtMaxUnSpeedLev1_ISig_ 24000;
BA_REL_ "GenSigTimeoutTime" BU_SG_REL_ IC SG_ 1208 EcoCruisePwtMaxUnSpeedLev1_ISig_ 6000;
BA_REL_ "GenSigFirstTimeoutTime" BU_SG_REL_ IC SG_ 1208 EcoCruisePwtMaxOvSpeedLev2_ISig_ 24000;
BA_REL_ "GenSigTimeoutTime" BU_SG_REL_ IC SG_ 1208 EcoCruisePwtMaxOvSpeedLev2_ISig_ 6000;
BA_REL_ "GenSigFirstTimeoutTime" BU_SG_REL_ IC SG_ 1208 EcoCruisePwtMaxUnSpeedLev0_ISig_ 24000;
BA_REL_ "GenSigTimeoutTime" BU_SG_REL_ IC SG_ 1208 EcoCruisePwtMaxUnSpeedLev0_ISig_ 6000;
BA_REL_ "GenSigFirstTimeoutTime" BU_SG_REL_ IC SG_ 1208 EcoCruisePwtMaxOvSpeedLev1_ISig_ 24000;
BA_REL_ "GenSigTimeoutTime" BU_SG_REL_ IC SG_ 1208 EcoCruisePwtMaxOvSpeedLev1_ISig_ 6000;
BA_REL_ "GenSigFirstTimeoutTime" BU_SG_REL_ IC SG_ 1208 EcoCruisePwtMaxUnSpeedLev2_ISig_ 24000;
BA_REL_ "GenSigTimeoutTime" BU_SG_REL_ IC SG_ 1208 EcoCruisePwtMaxUnSpeedLev2_ISig_ 6000;
BA_REL_ "GenSigFirstTimeoutTime" BU_SG_REL_ IC SG_ 1208 EcoCruisePwtMaxOvSpeedLev3_ISig_ 24000;
BA_REL_ "GenSigTimeoutTime" BU_SG_REL_ IC SG_ 1208 EcoCruisePwtMaxOvSpeedLev3_ISig_ 6000;
BA_REL_ "GenSigFirstTimeoutTime" BU_SG_REL_ IC SG_ 1208 BatterySOCTLWeak_ISig_5 24000;
BA_REL_ "GenSigTimeoutTime" BU_SG_REL_ IC SG_ 1208 BatterySOCTLWeak_ISig_5 6000;
BA_REL_ "GenSigFirstTimeoutTime" BU_SG_REL_ IC SG_ 1207 EngineTotalLngConsumed_ISig_5 24000;
BA_REL_ "GenSigTimeoutTime" BU_SG_REL_ IC SG_ 1207 EngineTotalLngConsumed_ISig_5 6000;
BA_REL_ "GenSigFirstTimeoutTime" BU_SG_REL_ CCM SG_ 1207 TotalVehicleDistanceHighRes_ISig 24000;
BA_REL_ "GenSigTimeoutTime" BU_SG_REL_ CCM SG_ 1207 TotalVehicleDistanceHighRes_ISig 6000;
BA_REL_ "GenSigFirstTimeoutTime" BU_SG_REL_ IC SG_ 1207 TotalVehicleDistanceHighRes_ISig 24000;
BA_REL_ "GenSigTimeoutTime" BU_SG_REL_ IC SG_ 1207 TotalVehicleDistanceHighRes_ISig 6000;
BA_REL_ "GenSigFirstTimeoutTime" BU_SG_REL_ IC SG_ 1206 PredictedMileageOfNextPadChg_ISi 24000;
BA_REL_ "GenSigTimeoutTime" BU_SG_REL_ IC SG_ 1206 PredictedMileageOfNextPadChg_ISi 6000;
BA_REL_ "GenSigFirstTimeoutTime" BU_SG_REL_ IC SG_ 1206 EngineRunningTime_ISig_5 24000;
BA_REL_ "GenSigTimeoutTime" BU_SG_REL_ IC SG_ 1206 EngineRunningTime_ISig_5 6000;
BA_REL_ "GenSigFirstTimeoutTime" BU_SG_REL_ IC SG_ 1205 TopGearUseDistance_ISig_5 24000;
BA_REL_ "GenSigTimeoutTime" BU_SG_REL_ IC SG_ 1205 TopGearUseDistance_ISig_5 6000;
BA_REL_ "GenSigFirstTimeoutTime" BU_SG_REL_ IC SG_ 1205 DPFSootLevel_ISig_5 24000;
BA_REL_ "GenSigTimeoutTime" BU_SG_REL_ IC SG_ 1205 DPFSootLevel_ISig_5 6000;
BA_REL_ "GenSigFirstTimeoutTime" BU_SG_REL_ IC SG_ 1205 CatalystTankLevel_ISig_5 24000;
BA_REL_ "GenSigTimeoutTime" BU_SG_REL_ IC SG_ 1205 CatalystTankLevel_ISig_5 6000;
BA_REL_ "GenSigFirstTimeoutTime" BU_SG_REL_ IC SG_ 1205 TransmissionOilTemp_ISig_5 24000;
BA_REL_ "GenSigTimeoutTime" BU_SG_REL_ IC SG_ 1205 TransmissionOilTemp_ISig_5 6000;
VAL_ 1032 PS_PosLightDoorOpen 3 "InactiveActiveSpare_NotAvailable" 2 "InactiveActiveSpare_Spare" 1 "InactiveActiveSpare_Active" 0 "InactiveActiveSpare_Inactive" ;
VAL_ 1032 Trail2TPMMatedStatus 3 "NoMatedMated_NotAvailable" 2 "NoMatedMated_Error" 1 "NoMatedMated_Mated" 0 "NoMatedMated_NoMated" ;
VAL_ 1032 Trail1TPMMatedStatus 3 "NoMatedMated_NotAvailable" 2 "NoMatedMated_Error" 1 "NoMatedMated_Mated" 0 "NoMatedMated_NoMated" ;
VAL_ 1032 PS_ExtLightFreeWheelInd 7 "PS_ExtLightFreeWheelInd_NotAvailable" 6 "PS_ExtLightFreeWheelInd_AHB" 5 "PS_ExtLightFreeWheelInd_AHS" 4 "PS_ExtLightFreeWheelInd_LowBeam" 3 "PS_ExtLightFreeWheelInd_PositionLight" 2 "PS_ExtLightFreeWheelInd_TemporaryStatus" 1 "PS_ExtLightFreeWheelInd_Off" 0 "PS_ExtLightFreeWheelInd_NoIndication" ;
VAL_ 1237 TruckTPMTireInfo_LeakageWarn 7 "TPMTireLeakageWarn_NotAvailable" 6 "TPMTireLeakageWarn_Error" 5 "TPMTireLeakageWarn_Spare3" 4 "TPMTireLeakageWarn_Spare2" 3 "TPMTireLeakageWarn_Spare1" 2 "TPMTireLeakageWarn_FastLeakageDetected" 1 "TPMTireLeakageWarn_SlowLeakageDetected" 0 "TPMTireLeakageWarn_NoLeakageDetected" ;
VAL_ 1237 TruckTPMTireInfo_Battery 7 "TPMBatteryStatus_NotAvailable" 6 "TPMBatteryStatus_Error" 5 "TPMBatteryStatus_Spare3" 4 "TPMBatteryStatus_Spare2" 3 "TPMBatteryStatus_Spare1" 2 "TPMBatteryStatus_BatteryVeryLow" 1 "TPMBatteryStatus_BatteryLow" 0 "TPMBatteryStatus_BatteryOK" ;
VAL_ 1237 TruckTPMTireInfo_PresWarn 7 "TPMPressureWarning_NotAvailable" 6 "TPMPressureWarning_Error" 5 "TPMPressureWarning_Spare" 4 "TPMPressureWarning_ExtremeUnderPressure" 3 "TPMPressureWarning_UnderPressure" 2 "TPMPressureWarning_NoWarningPressure" 1 "TPMPressureWarning_OverPressure" 0 "TPMPressureWarning_ExtremeOverPressure" ;
VAL_ 1237 Trail1TPMFailure 3 "InactiveActive_NotAvailable" 2 "InactiveActive_Error" 1 "InactiveActive_Active" 0 "InactiveActive_Inactive" ;
VAL_ 1237 Trail2TPMFailure 3 "InactiveActive_NotAvailable" 2 "InactiveActive_Error" 1 "InactiveActive_Active" 0 "InactiveActive_Inactive" ;
VAL_ 1237 TruckTPMTireInfo_Active 3 "TPMTireActive_NotAvailable" 2 "TPMTireActive_Error" 1 "TPMTireActive_TireActivePositioned" 0 "TPMTireActive_TireNotActive" ;
VAL_ 1237 TrckTPMFailure 3 "InactiveActive_NotAvailable" 2 "InactiveActive_Error" 1 "InactiveActive_Active" 0 "InactiveActive_Inactive" ;
VAL_ 1234 Trail2TPMTireInfo_PresWarn 7 "TPMPressureWarning_NotAvailable" 6 "TPMPressureWarning_Error" 5 "TPMPressureWarning_Spare" 4 "TPMPressureWarning_ExtremeUnderPressure" 3 "TPMPressureWarning_UnderPressure" 2 "TPMPressureWarning_NoWarningPressure" 1 "TPMPressureWarning_OverPressure" 0 "TPMPressureWarning_ExtremeOverPressure" ;
VAL_ 1234 Trail2TPMTireInfo_LeakageWarn 7 "TPMTireLeakageWarn_NotAvailable" 6 "TPMTireLeakageWarn_Error" 5 "TPMTireLeakageWarn_Spare3" 4 "TPMTireLeakageWarn_Spare2" 3 "TPMTireLeakageWarn_Spare1" 2 "TPMTireLeakageWarn_FastLeakageDetected" 1 "TPMTireLeakageWarn_SlowLeakageDetected" 0 "TPMTireLeakageWarn_NoLeakageDetected" ;
VAL_ 1234 Trail2TPMTireInfo_Battery 7 "TPMBatteryStatus_NotAvailable" 6 "TPMBatteryStatus_Error" 5 "TPMBatteryStatus_Spare3" 4 "TPMBatteryStatus_Spare2" 3 "TPMBatteryStatus_Spare1" 2 "TPMBatteryStatus_BatteryVeryLow" 1 "TPMBatteryStatus_BatteryLow" 0 "TPMBatteryStatus_BatteryOK" ;
VAL_ 1234 Trail2TPMTireInfo_Active 3 "TPMTireActive_NotAvailable" 2 "TPMTireActive_Error" 1 "TPMTireActive_TireActivePositioned" 0 "TPMTireActive_TireNotActive" ;
VAL_ 1231 Trail1TPMTireInfo_LeakageWarn 7 "TPMTireLeakageWarn_NotAvailable" 6 "TPMTireLeakageWarn_Error" 5 "TPMTireLeakageWarn_Spare3" 4 "TPMTireLeakageWarn_Spare2" 3 "TPMTireLeakageWarn_Spare1" 2 "TPMTireLeakageWarn_FastLeakageDetected" 1 "TPMTireLeakageWarn_SlowLeakageDetected" 0 "TPMTireLeakageWarn_NoLeakageDetected" ;
VAL_ 1231 TPMPosOfWMResponse_Status 7 "TPMPosStatusResp_NotAvailable" 6 "TPMPosStatusResp_Error" 5 "TPMPosStatusResp_Aborted" 4 "TPMPosStatusResp_Failed" 3 "TPMPosStatusResp_PositionedOK" 2 "TPMPosStatusResp_Timeout" 1 "TPMPosStatusResp_Progressing" 0 "TPMPosStatusResp_NotActive" ;
VAL_ 1231 TPMPosOfWMResponse_VehiclePos 7 "TPMVehiclePos_NotAvailable" 6 "TPMVehiclePos_Error" 5 "TPMVehiclePos_Trailer5Vehicle" 4 "TPMVehiclePos_Trailer4Vehicle" 3 "TPMVehiclePos_Trailer3Vehicle" 2 "TPMVehiclePos_Trailer2Vehicle" 1 "TPMVehiclePos_Trailer1Vehicle" 0 "TPMVehiclePos_TruckVehicle" ;
VAL_ 1231 Trail1TPMTireInfo_PresWarn 7 "TPMPressureWarning_NotAvailable" 6 "TPMPressureWarning_Error" 5 "TPMPressureWarning_Spare" 4 "TPMPressureWarning_ExtremeUnderPressure" 3 "TPMPressureWarning_UnderPressure" 2 "TPMPressureWarning_NoWarningPressure" 1 "TPMPressureWarning_OverPressure" 0 "TPMPressureWarning_ExtremeOverPressure" ;
VAL_ 1231 Trail1TPMTireInfo_Battery 7 "TPMBatteryStatus_NotAvailable" 6 "TPMBatteryStatus_Error" 5 "TPMBatteryStatus_Spare3" 4 "TPMBatteryStatus_Spare2" 3 "TPMBatteryStatus_Spare1" 2 "TPMBatteryStatus_BatteryVeryLow" 1 "TPMBatteryStatus_BatteryLow" 0 "TPMBatteryStatus_BatteryOK" ;
VAL_ 1231 Trail1TPMTireInfo_Active 3 "TPMTireActive_NotAvailable" 2 "TPMTireActive_Error" 1 "TPMTireActive_TireActivePositioned" 0 "TPMTireActive_TireNotActive" ;
VAL_ 1403 TrckTPMThresCfg_AxleNr 7 "TPMAxleNr_NotAvailable" 6 "TPMAxleNr_Error" 5 "TPMAxleNr_Axle5" 4 "TPMAxleNr_Axle4" 3 "TPMAxleNr_Axle3" 2 "TPMAxleNr_Axle2" 1 "TPMAxleNr_Axle1" 0 "TPMAxleNr_NoRequest" ;
VAL_ 1403 TruckTPMAxleTireCnfg_Axle5 7 "TPMAxleConfig_NotAvailable" 6 "TPMAxleConfig_Error" 5 "TPMAxleConfig_Spare" 4 "TPMAxleConfig_RearAxleWith4Tires" 3 "TPMAxleConfig_RearAxleWith2Tires" 2 "TPMAxleConfig_FrontAxleWith4Tires" 1 "TPMAxleConfig_FrontAxleWith2Tires" 0 "TPMAxleConfig_NotPresent" ;
VAL_ 1403 TruckTPMAxleTireCnfg_Axle3 7 "TPMAxleConfig_NotAvailable" 6 "TPMAxleConfig_Error" 5 "TPMAxleConfig_Spare" 4 "TPMAxleConfig_RearAxleWith4Tires" 3 "TPMAxleConfig_RearAxleWith2Tires" 2 "TPMAxleConfig_FrontAxleWith4Tires" 1 "TPMAxleConfig_FrontAxleWith2Tires" 0 "TPMAxleConfig_NotPresent" ;
VAL_ 1403 TruckTPMAxleTireCnfg_Axle1 7 "TPMAxleConfig_NotAvailable" 6 "TPMAxleConfig_Error" 5 "TPMAxleConfig_Spare" 4 "TPMAxleConfig_RearAxleWith4Tires" 3 "TPMAxleConfig_RearAxleWith2Tires" 2 "TPMAxleConfig_FrontAxleWith4Tires" 1 "TPMAxleConfig_FrontAxleWith2Tires" 0 "TPMAxleConfig_NotPresent" ;
VAL_ 1403 TruckTPMAxleTireCnfg_Axle4 7 "TPMAxleConfig_NotAvailable" 6 "TPMAxleConfig_Error" 5 "TPMAxleConfig_Spare" 4 "TPMAxleConfig_RearAxleWith4Tires" 3 "TPMAxleConfig_RearAxleWith2Tires" 2 "TPMAxleConfig_FrontAxleWith4Tires" 1 "TPMAxleConfig_FrontAxleWith2Tires" 0 "TPMAxleConfig_NotPresent" ;
VAL_ 1403 TruckTPMAxleTireCnfg_Axle2 7 "TPMAxleConfig_NotAvailable" 6 "TPMAxleConfig_Error" 5 "TPMAxleConfig_Spare" 4 "TPMAxleConfig_RearAxleWith4Tires" 3 "TPMAxleConfig_RearAxleWith2Tires" 2 "TPMAxleConfig_FrontAxleWith4Tires" 1 "TPMAxleConfig_FrontAxleWith2Tires" 0 "TPMAxleConfig_NotPresent" ;
VAL_ 1402 Trail2TPMAxleTireCnfg_Axle1 7 "TPMAxleConfig_NotAvailable" 6 "TPMAxleConfig_Error" 5 "TPMAxleConfig_Spare" 4 "TPMAxleConfig_RearAxleWith4Tires" 3 "TPMAxleConfig_RearAxleWith2Tires" 2 "TPMAxleConfig_FrontAxleWith4Tires" 1 "TPMAxleConfig_FrontAxleWith2Tires" 0 "TPMAxleConfig_NotPresent" ;
VAL_ 1402 Trail2TPMAxleTireCnfg_Axle3 7 "TPMAxleConfig_NotAvailable" 6 "TPMAxleConfig_Error" 5 "TPMAxleConfig_Spare" 4 "TPMAxleConfig_RearAxleWith4Tires" 3 "TPMAxleConfig_RearAxleWith2Tires" 2 "TPMAxleConfig_FrontAxleWith4Tires" 1 "TPMAxleConfig_FrontAxleWith2Tires" 0 "TPMAxleConfig_NotPresent" ;
VAL_ 1402 Trail2TPMAxleTireCnfg_Axle2 7 "TPMAxleConfig_NotAvailable" 6 "TPMAxleConfig_Error" 5 "TPMAxleConfig_Spare" 4 "TPMAxleConfig_RearAxleWith4Tires" 3 "TPMAxleConfig_RearAxleWith2Tires" 2 "TPMAxleConfig_FrontAxleWith4Tires" 1 "TPMAxleConfig_FrontAxleWith2Tires" 0 "TPMAxleConfig_NotPresent" ;
VAL_ 1402 Trail2TPMAxleTireCnfg_Axle4 7 "TPMAxleConfig_NotAvailable" 6 "TPMAxleConfig_Error" 5 "TPMAxleConfig_Spare" 4 "TPMAxleConfig_RearAxleWith4Tires" 3 "TPMAxleConfig_RearAxleWith2Tires" 2 "TPMAxleConfig_FrontAxleWith4Tires" 1 "TPMAxleConfig_FrontAxleWith2Tires" 0 "TPMAxleConfig_NotPresent" ;
VAL_ 1402 Trail2TPMThresCfg_AxleNr 7 "TPMAxleNr_NotAvailable" 6 "TPMAxleNr_Error" 5 "TPMAxleNr_Axle5" 4 "TPMAxleNr_Axle4" 3 "TPMAxleNr_Axle3" 2 "TPMAxleNr_Axle2" 1 "TPMAxleNr_Axle1" 0 "TPMAxleNr_NoRequest" ;
VAL_ 1402 Trail2TPMAxleTireCnfg_Axle5 7 "TPMAxleConfig_NotAvailable" 6 "TPMAxleConfig_Error" 5 "TPMAxleConfig_Spare" 4 "TPMAxleConfig_RearAxleWith4Tires" 3 "TPMAxleConfig_RearAxleWith2Tires" 2 "TPMAxleConfig_FrontAxleWith4Tires" 1 "TPMAxleConfig_FrontAxleWith2Tires" 0 "TPMAxleConfig_NotPresent" ;
VAL_ 1401 Trail1TPMAxleTireCnfg_Axle4 7 "TPMAxleConfig_NotAvailable" 6 "TPMAxleConfig_Error" 5 "TPMAxleConfig_Spare" 4 "TPMAxleConfig_RearAxleWith4Tires" 3 "TPMAxleConfig_RearAxleWith2Tires" 2 "TPMAxleConfig_FrontAxleWith4Tires" 1 "TPMAxleConfig_FrontAxleWith2Tires" 0 "TPMAxleConfig_NotPresent" ;
VAL_ 1401 Trail1TPMAxleTireCnfg_Axle5 7 "TPMAxleConfig_NotAvailable" 6 "TPMAxleConfig_Error" 5 "TPMAxleConfig_Spare" 4 "TPMAxleConfig_RearAxleWith4Tires" 3 "TPMAxleConfig_RearAxleWith2Tires" 2 "TPMAxleConfig_FrontAxleWith4Tires" 1 "TPMAxleConfig_FrontAxleWith2Tires" 0 "TPMAxleConfig_NotPresent" ;
VAL_ 1401 Trail1TPMAxleTireCnfg_Axle3 7 "TPMAxleConfig_NotAvailable" 6 "TPMAxleConfig_Error" 5 "TPMAxleConfig_Spare" 4 "TPMAxleConfig_RearAxleWith4Tires" 3 "TPMAxleConfig_RearAxleWith2Tires" 2 "TPMAxleConfig_FrontAxleWith4Tires" 1 "TPMAxleConfig_FrontAxleWith2Tires" 0 "TPMAxleConfig_NotPresent" ;
VAL_ 1401 Trail1TPMAxleTireCnfg_Axle2 7 "TPMAxleConfig_NotAvailable" 6 "TPMAxleConfig_Error" 5 "TPMAxleConfig_Spare" 4 "TPMAxleConfig_RearAxleWith4Tires" 3 "TPMAxleConfig_RearAxleWith2Tires" 2 "TPMAxleConfig_FrontAxleWith4Tires" 1 "TPMAxleConfig_FrontAxleWith2Tires" 0 "TPMAxleConfig_NotPresent" ;
VAL_ 1401 Trail1TPMAxleTireCnfg_Axle1 7 "TPMAxleConfig_NotAvailable" 6 "TPMAxleConfig_Error" 5 "TPMAxleConfig_Spare" 4 "TPMAxleConfig_RearAxleWith4Tires" 3 "TPMAxleConfig_RearAxleWith2Tires" 2 "TPMAxleConfig_FrontAxleWith4Tires" 1 "TPMAxleConfig_FrontAxleWith2Tires" 0 "TPMAxleConfig_NotPresent" ;
VAL_ 1401 Trail1TPMThresCfg_AxleNr 7 "TPMAxleNr_NotAvailable" 6 "TPMAxleNr_Error" 5 "TPMAxleNr_Axle5" 4 "TPMAxleNr_Axle4" 3 "TPMAxleNr_Axle3" 2 "TPMAxleNr_Axle2" 1 "TPMAxleNr_Axle1" 0 "TPMAxleNr_NoRequest" ;
VAL_ 2566909713 Trail4TPMThresCfg_AxleNr 7 "TPMAxleNr_NotAvailable" 6 "TPMAxleNr_Error" 5 "TPMAxleNr_Axle5" 4 "TPMAxleNr_Axle4" 3 "TPMAxleNr_Axle3" 2 "TPMAxleNr_Axle2" 1 "TPMAxleNr_Axle1" 0 "TPMAxleNr_NoRequest" ;
VAL_ 2566901521 Trail5TPMThresCfg_AxleNr 7 "TPMAxleNr_NotAvailable" 6 "TPMAxleNr_Error" 5 "TPMAxleNr_Axle5" 4 "TPMAxleNr_Axle4" 3 "TPMAxleNr_Axle3" 2 "TPMAxleNr_Axle2" 1 "TPMAxleNr_Axle1" 0 "TPMAxleNr_NoRequest" ;
VAL_ 2566893329 Trail3TPMThresCfg_AxleNr 7 "TPMAxleNr_NotAvailable" 6 "TPMAxleNr_Error" 5 "TPMAxleNr_Axle5" 4 "TPMAxleNr_Axle4" 3 "TPMAxleNr_Axle3" 2 "TPMAxleNr_Axle2" 1 "TPMAxleNr_Axle1" 0 "TPMAxleNr_NoRequest" ;
VAL_ 2566885137 Trail5TPMAxleTireCnfg_Axle3 7 "TPMAxleConfig_NotAvailable" 6 "TPMAxleConfig_Error" 5 "TPMAxleConfig_Spare" 4 "TPMAxleConfig_RearAxleWith4Tires" 3 "TPMAxleConfig_RearAxleWith2Tires" 2 "TPMAxleConfig_FrontAxleWith4Tires" 1 "TPMAxleConfig_FrontAxleWith2Tires" 0 "TPMAxleConfig_NotPresent" ;
VAL_ 2566885137 Trail4TPMAxleTireCnfg_Axle1 7 "TPMAxleConfig_NotAvailable" 6 "TPMAxleConfig_Error" 5 "TPMAxleConfig_Spare" 4 "TPMAxleConfig_RearAxleWith4Tires" 3 "TPMAxleConfig_RearAxleWith2Tires" 2 "TPMAxleConfig_FrontAxleWith4Tires" 1 "TPMAxleConfig_FrontAxleWith2Tires" 0 "TPMAxleConfig_NotPresent" ;
VAL_ 2566885137 Trail5TPMAxleTireCnfg_Axle4 7 "TPMAxleConfig_NotAvailable" 6 "TPMAxleConfig_Error" 5 "TPMAxleConfig_Spare" 4 "TPMAxleConfig_RearAxleWith4Tires" 3 "TPMAxleConfig_RearAxleWith2Tires" 2 "TPMAxleConfig_FrontAxleWith4Tires" 1 "TPMAxleConfig_FrontAxleWith2Tires" 0 "TPMAxleConfig_NotPresent" ;
VAL_ 2566885137 Trail3TPMAxleTireCnfg_Axle3 7 "TPMAxleConfig_NotAvailable" 6 "TPMAxleConfig_Error" 5 "TPMAxleConfig_Spare" 4 "TPMAxleConfig_RearAxleWith4Tires" 3 "TPMAxleConfig_RearAxleWith2Tires" 2 "TPMAxleConfig_FrontAxleWith4Tires" 1 "TPMAxleConfig_FrontAxleWith2Tires" 0 "TPMAxleConfig_NotPresent" ;
VAL_ 2566885137 Trail4TPMAxleTireCnfg_Axle5 7 "TPMAxleConfig_NotAvailable" 6 "TPMAxleConfig_Error" 5 "TPMAxleConfig_Spare" 4 "TPMAxleConfig_RearAxleWith4Tires" 3 "TPMAxleConfig_RearAxleWith2Tires" 2 "TPMAxleConfig_FrontAxleWith4Tires" 1 "TPMAxleConfig_FrontAxleWith2Tires" 0 "TPMAxleConfig_NotPresent" ;
VAL_ 2566885137 Trail5TPMAxleTireCnfg_Axle2 7 "TPMAxleConfig_NotAvailable" 6 "TPMAxleConfig_Error" 5 "TPMAxleConfig_Spare" 4 "TPMAxleConfig_RearAxleWith4Tires" 3 "TPMAxleConfig_RearAxleWith2Tires" 2 "TPMAxleConfig_FrontAxleWith4Tires" 1 "TPMAxleConfig_FrontAxleWith2Tires" 0 "TPMAxleConfig_NotPresent" ;
VAL_ 2566885137 Trail4TPMAxleTireCnfg_Axle4 7 "TPMAxleConfig_NotAvailable" 6 "TPMAxleConfig_Error" 5 "TPMAxleConfig_Spare" 4 "TPMAxleConfig_RearAxleWith4Tires" 3 "TPMAxleConfig_RearAxleWith2Tires" 2 "TPMAxleConfig_FrontAxleWith4Tires" 1 "TPMAxleConfig_FrontAxleWith2Tires" 0 "TPMAxleConfig_NotPresent" ;
VAL_ 2566885137 Trail3TPMAxleTireCnfg_Axle2 7 "TPMAxleConfig_NotAvailable" 6 "TPMAxleConfig_Error" 5 "TPMAxleConfig_Spare" 4 "TPMAxleConfig_RearAxleWith4Tires" 3 "TPMAxleConfig_RearAxleWith2Tires" 2 "TPMAxleConfig_FrontAxleWith4Tires" 1 "TPMAxleConfig_FrontAxleWith2Tires" 0 "TPMAxleConfig_NotPresent" ;
VAL_ 2566885137 Trail3TPMAxleTireCnfg_Axle5 7 "TPMAxleConfig_NotAvailable" 6 "TPMAxleConfig_Error" 5 "TPMAxleConfig_Spare" 4 "TPMAxleConfig_RearAxleWith4Tires" 3 "TPMAxleConfig_RearAxleWith2Tires" 2 "TPMAxleConfig_FrontAxleWith4Tires" 1 "TPMAxleConfig_FrontAxleWith2Tires" 0 "TPMAxleConfig_NotPresent" ;
VAL_ 2566885137 Trail5TPMAxleTireCnfg_Axle1 7 "TPMAxleConfig_NotAvailable" 6 "TPMAxleConfig_Error" 5 "TPMAxleConfig_Spare" 4 "TPMAxleConfig_RearAxleWith4Tires" 3 "TPMAxleConfig_RearAxleWith2Tires" 2 "TPMAxleConfig_FrontAxleWith4Tires" 1 "TPMAxleConfig_FrontAxleWith2Tires" 0 "TPMAxleConfig_NotPresent" ;
VAL_ 2566885137 Trail5TPMAxleTireCnfg_Axle5 7 "TPMAxleConfig_NotAvailable" 6 "TPMAxleConfig_Error" 5 "TPMAxleConfig_Spare" 4 "TPMAxleConfig_RearAxleWith4Tires" 3 "TPMAxleConfig_RearAxleWith2Tires" 2 "TPMAxleConfig_FrontAxleWith4Tires" 1 "TPMAxleConfig_FrontAxleWith2Tires" 0 "TPMAxleConfig_NotPresent" ;
VAL_ 2566885137 Trail4TPMAxleTireCnfg_Axle2 7 "TPMAxleConfig_NotAvailable" 6 "TPMAxleConfig_Error" 5 "TPMAxleConfig_Spare" 4 "TPMAxleConfig_RearAxleWith4Tires" 3 "TPMAxleConfig_RearAxleWith2Tires" 2 "TPMAxleConfig_FrontAxleWith4Tires" 1 "TPMAxleConfig_FrontAxleWith2Tires" 0 "TPMAxleConfig_NotPresent" ;
VAL_ 2566885137 Trail3TPMAxleTireCnfg_Axle1 7 "TPMAxleConfig_NotAvailable" 6 "TPMAxleConfig_Error" 5 "TPMAxleConfig_Spare" 4 "TPMAxleConfig_RearAxleWith4Tires" 3 "TPMAxleConfig_RearAxleWith2Tires" 2 "TPMAxleConfig_FrontAxleWith4Tires" 1 "TPMAxleConfig_FrontAxleWith2Tires" 0 "TPMAxleConfig_NotPresent" ;
VAL_ 2566885137 Trail4TPMAxleTireCnfg_Axle3 7 "TPMAxleConfig_NotAvailable" 6 "TPMAxleConfig_Error" 5 "TPMAxleConfig_Spare" 4 "TPMAxleConfig_RearAxleWith4Tires" 3 "TPMAxleConfig_RearAxleWith2Tires" 2 "TPMAxleConfig_FrontAxleWith4Tires" 1 "TPMAxleConfig_FrontAxleWith2Tires" 0 "TPMAxleConfig_NotPresent" ;
VAL_ 2566885137 Trail3TPMAxleTireCnfg_Axle4 7 "TPMAxleConfig_NotAvailable" 6 "TPMAxleConfig_Error" 5 "TPMAxleConfig_Spare" 4 "TPMAxleConfig_RearAxleWith4Tires" 3 "TPMAxleConfig_RearAxleWith2Tires" 2 "TPMAxleConfig_FrontAxleWith4Tires" 1 "TPMAxleConfig_FrontAxleWith2Tires" 0 "TPMAxleConfig_NotPresent" ;
VAL_ 2566876945 Trail3TPMTireInfo_Battery 7 "TPMBatteryStatus_NotAvailable" 6 "TPMBatteryStatus_Error" 5 "TPMBatteryStatus_Spare3" 4 "TPMBatteryStatus_Spare2" 3 "TPMBatteryStatus_Spare1" 2 "TPMBatteryStatus_BatteryVeryLow" 1 "TPMBatteryStatus_BatteryLow" 0 "TPMBatteryStatus_BatteryOK" ;
VAL_ 2566876945 Trail3TPMFailure 3 "InactiveActive_NotAvailable" 2 "InactiveActive_Error" 1 "InactiveActive_Active" 0 "InactiveActive_Inactive" ;
VAL_ 2566876945 Trail5TPMFailure 3 "InactiveActive_NotAvailable" 2 "InactiveActive_Error" 1 "InactiveActive_Active" 0 "InactiveActive_Inactive" ;
VAL_ 2566876945 Trail3TPMTireInfo_PresWarn 7 "TPMPressureWarning_NotAvailable" 6 "TPMPressureWarning_Error" 5 "TPMPressureWarning_Spare" 4 "TPMPressureWarning_ExtremeUnderPressure" 3 "TPMPressureWarning_UnderPressure" 2 "TPMPressureWarning_NoWarningPressure" 1 "TPMPressureWarning_OverPressure" 0 "TPMPressureWarning_ExtremeOverPressure" ;
VAL_ 2566876945 Trail3TPMTireInfo_LeakageWarn 7 "TPMTireLeakageWarn_NotAvailable" 6 "TPMTireLeakageWarn_Error" 5 "TPMTireLeakageWarn_Spare3" 4 "TPMTireLeakageWarn_Spare2" 3 "TPMTireLeakageWarn_Spare1" 2 "TPMTireLeakageWarn_FastLeakageDetected" 1 "TPMTireLeakageWarn_SlowLeakageDetected" 0 "TPMTireLeakageWarn_NoLeakageDetected" ;
VAL_ 2566876945 Trail4TPMFailure 3 "InactiveActive_NotAvailable" 2 "InactiveActive_Error" 1 "InactiveActive_Active" 0 "InactiveActive_Inactive" ;
VAL_ 2566876945 Trail3TPMTireInfo_Active 3 "TPMTireActive_NotAvailable" 2 "TPMTireActive_Error" 1 "TPMTireActive_TireActivePositioned" 0 "TPMTireActive_TireNotActive" ;
VAL_ 2566868753 Trail5TPMTireInfo_LeakageWarn 7 "TPMTireLeakageWarn_NotAvailable" 6 "TPMTireLeakageWarn_Error" 5 "TPMTireLeakageWarn_Spare3" 4 "TPMTireLeakageWarn_Spare2" 3 "TPMTireLeakageWarn_Spare1" 2 "TPMTireLeakageWarn_FastLeakageDetected" 1 "TPMTireLeakageWarn_SlowLeakageDetected" 0 "TPMTireLeakageWarn_NoLeakageDetected" ;
VAL_ 2566868753 Trail5TPMTireInfo_PresWarn 7 "TPMPressureWarning_NotAvailable" 6 "TPMPressureWarning_Error" 5 "TPMPressureWarning_Spare" 4 "TPMPressureWarning_ExtremeUnderPressure" 3 "TPMPressureWarning_UnderPressure" 2 "TPMPressureWarning_NoWarningPressure" 1 "TPMPressureWarning_OverPressure" 0 "TPMPressureWarning_ExtremeOverPressure" ;
VAL_ 2566868753 Trail5TPMTireInfo_Battery 7 "TPMBatteryStatus_NotAvailable" 6 "TPMBatteryStatus_Error" 5 "TPMBatteryStatus_Spare3" 4 "TPMBatteryStatus_Spare2" 3 "TPMBatteryStatus_Spare1" 2 "TPMBatteryStatus_BatteryVeryLow" 1 "TPMBatteryStatus_BatteryLow" 0 "TPMBatteryStatus_BatteryOK" ;
VAL_ 2566868753 Trail5TPMTireInfo_Active 3 "TPMTireActive_NotAvailable" 2 "TPMTireActive_Error" 1 "TPMTireActive_TireActivePositioned" 0 "TPMTireActive_TireNotActive" ;
VAL_ 2566860305 Trail4TPMTireInfo_LeakageWarn 7 "TPMTireLeakageWarn_NotAvailable" 6 "TPMTireLeakageWarn_Error" 5 "TPMTireLeakageWarn_Spare3" 4 "TPMTireLeakageWarn_Spare2" 3 "TPMTireLeakageWarn_Spare1" 2 "TPMTireLeakageWarn_FastLeakageDetected" 1 "TPMTireLeakageWarn_SlowLeakageDetected" 0 "TPMTireLeakageWarn_NoLeakageDetected" ;
VAL_ 2566860305 Trail4TPMTireInfo_Battery 7 "TPMBatteryStatus_NotAvailable" 6 "TPMBatteryStatus_Error" 5 "TPMBatteryStatus_Spare3" 4 "TPMBatteryStatus_Spare2" 3 "TPMBatteryStatus_Spare1" 2 "TPMBatteryStatus_BatteryVeryLow" 1 "TPMBatteryStatus_BatteryLow" 0 "TPMBatteryStatus_BatteryOK" ;
VAL_ 2566860305 Trail4TPMTireInfo_Active 3 "TPMTireActive_NotAvailable" 2 "TPMTireActive_Error" 1 "TPMTireActive_TireActivePositioned" 0 "TPMTireActive_TireNotActive" ;
VAL_ 2566860305 Trail4TPMTireInfo_PresWarn 7 "TPMPressureWarning_NotAvailable" 6 "TPMPressureWarning_Error" 5 "TPMPressureWarning_Spare" 4 "TPMPressureWarning_ExtremeUnderPressure" 3 "TPMPressureWarning_UnderPressure" 2 "TPMPressureWarning_NoWarningPressure" 1 "TPMPressureWarning_OverPressure" 0 "TPMPressureWarning_ExtremeOverPressure" ;
VAL_ 2566881297 Trail4TPMMatedStatus 3 "NoMatedMated_NotAvailable" 2 "NoMatedMated_Error" 1 "NoMatedMated_Mated" 0 "NoMatedMated_NoMated" ;
VAL_ 2566881297 Trail5TPMMatedStatus 3 "NoMatedMated_NotAvailable" 2 "NoMatedMated_Error" 1 "NoMatedMated_Mated" 0 "NoMatedMated_NoMated" ;
VAL_ 2566881297 Trail3TPMMatedStatus 3 "NoMatedMated_NotAvailable" 2 "NoMatedMated_Error" 1 "NoMatedMated_Mated" 0 "NoMatedMated_NoMated" ;
VAL_ 395 XPRGSystemCap_AllowedInfInhibit_ 7 "XPRG_OperationalStat_NotAvailable" 6 "XPRG_OperationalStat_Error" 5 "XPRG_OperationalStat_Spare3" 4 "XPRG_OperationalStat_Spare2" 3 "XPRG_OperationalStat_Spare1" 2 "XPRG_OperationalStat_OperationalAndActive" 1 "XPRG_OperationalStat_OperationalButNotActive" 0 "XPRG_OperationalStat_NotOperational" ;
VAL_ 395 XPRGSystemCap_Priority_ISig_5 7 "XPRGPriority3bit_NotAvailable" 6 "XPRGPriority3bit_Error" 5 "XPRGPriority3bit_Spare2" 4 "XPRGPriority3bit_Spare1" 3 "XPRGPriority3bit_High" 2 "XPRGPriority3bit_Medium" 1 "XPRGPriority3bit_Normal" 0 "XPRGPriority3bit_NoPriority" ;
VAL_ 395 DRLOverride_DeviceIndication 3 "DeviceIndication_SpareValue" 2 "DeviceIndication_Blink" 1 "DeviceIndication_On" 0 "DeviceIndication_Off" ;
VAL_ 395 PS_DRLOverride 3 "InactiveActiveSpare_NotAvailable" 2 "InactiveActiveSpare_Spare" 1 "InactiveActiveSpare_Active" 0 "InactiveActiveSpare_Inactive" ;
VAL_ 395 PS_Dippedbeam 3 "OffOnSpare_NotAvailable" 2 "OffOnSpare_Spare" 1 "OffOnSpare_On" 0 "OffOnSpare_Off" ;
VAL_ 395 XPRGSystemCap_AllowedRelInhibit_ 7 "XPRG_OperationalStat_NotAvailable" 6 "XPRG_OperationalStat_Error" 5 "XPRG_OperationalStat_Spare3" 4 "XPRG_OperationalStat_Spare2" 3 "XPRG_OperationalStat_Spare1" 2 "XPRG_OperationalStat_OperationalAndActive" 1 "XPRG_OperationalStat_OperationalButNotActive" 0 "XPRG_OperationalStat_NotOperational" ;
VAL_ 395 PS_DRL 3 "InactiveActiveSpare_NotAvailable" 2 "InactiveActiveSpare_Spare" 1 "InactiveActiveSpare_Active" 0 "InactiveActiveSpare_Inactive" ;
VAL_ 907 Trailer5GeometricData_Index_ISig 255 "TrailerGeometricDataIndex_NotAvailable" 254 "TrailerGeometricDataIndex_Error" 38 "TrailerGeometricDataIndex_TrailerHeightRear" 37 "TrailerGeometricDataIndex_ChassisHeight" 36 "TrailerGeometricDataIndex_TrailerHeightFront" 35 "TrailerGeometricDataIndex_LoadingHeightFront" 34 "TrailerGeometricDataIndex_LoadingHeightRear" 33 "TrailerGeometricDataIndex_CouplingHeight2" 32 "TrailerGeometricDataIndex_CouplingHeight1" 31 "TrailerGeometricDataIndex_TotalLengthOfTrailer" 30 "TrailerGeometricDataIndex_DistanceFirstToSecondCouplingPoint" 29 "TrailerGeometricDataIndex_WheelBaseAxle19ToAxle20" 28 "TrailerGeometricDataIndex_WheelBaseAxle18ToAxle19" 27 "TrailerGeometricDataIndex_WheelBaseAxle17ToAxle18" 26 "TrailerGeometricDataIndex_WheelBaseAxle16ToAxle17" 25 "TrailerGeometricDataIndex_WheelBaseAxle15ToAxle16" 24 "TrailerGeometricDataIndex_WheelBaseAxle14ToAxle15" 23 "TrailerGeometricDataIndex_WheelBaseAxle13ToAxle14" 22 "TrailerGeometricDataIndex_WheelBaseAxle12ToAxle13" 21 "TrailerGeometricDataIndex_WheelBaseAxle11ToAxle12" 20 "TrailerGeometricDataIndex_WheelBaseAxle10ToAxle11" 19 "TrailerGeometricDataIndex_WheelBaseAxle9ToAxle10" 18 "TrailerGeometricDataIndex_WheelBaseAxle8ToAxle9" 17 "TrailerGeometricDataIndex_WheelBaseAxle7ToAxle8" 16 "TrailerGeometricDataIndex_WheelBaseAxle6ToAxle7" 15 "TrailerGeometricDataIndex_WheelBaseAxle5ToAxle6" 14 "TrailerGeometricDataIndex_WheelBaseAxle4ToAxle5" 13 "TrailerGeometricDataIndex_WheelBaseAxle3ToAxle4" 12 "TrailerGeometricDataIndex_WheelBaseAxle2ToAxle3" 11 "TrailerGeometricDataIndex_WheelBaseAxle1ToAxle2" 10 "TrailerGeometricDataIndex_AxleNumberOfLiftAxle5" 9 "TrailerGeometricDataIndex_AxleNumberOfLiftAxle4" 8 "TrailerGeometricDataIndex_AxleNumberOfLiftAxle3" 7 "TrailerGeometricDataIndex_AxleNumberOfLiftAxle2" 6 "TrailerGeometricDataIndex_AxleNumberOfLiftAxle1" 5 "TrailerGeometricDataIndex_NumberOfLiftAxles" 4 "TrailerGeometricDataIndex_NumberOfFrontAxles" 3 "TrailerGeometricDataIndex_NumberOfAxles" 2 "TrailerGeometricDataIndex_TrackWidth" 1 "TrailerGeometricDataIndex_DistanceCouplingToAxle1" 0 "TrailerGeometricDataIndex_TypeOfTrailer" ;
VAL_ 906 Trailer3GeometricData_Index_ISig 255 "TrailerGeometricDataIndex_NotAvailable" 254 "TrailerGeometricDataIndex_Error" 38 "TrailerGeometricDataIndex_TrailerHeightRear" 37 "TrailerGeometricDataIndex_ChassisHeight" 36 "TrailerGeometricDataIndex_TrailerHeightFront" 35 "TrailerGeometricDataIndex_LoadingHeightFront" 34 "TrailerGeometricDataIndex_LoadingHeightRear" 33 "TrailerGeometricDataIndex_CouplingHeight2" 32 "TrailerGeometricDataIndex_CouplingHeight1" 31 "TrailerGeometricDataIndex_TotalLengthOfTrailer" 30 "TrailerGeometricDataIndex_DistanceFirstToSecondCouplingPoint" 29 "TrailerGeometricDataIndex_WheelBaseAxle19ToAxle20" 28 "TrailerGeometricDataIndex_WheelBaseAxle18ToAxle19" 27 "TrailerGeometricDataIndex_WheelBaseAxle17ToAxle18" 26 "TrailerGeometricDataIndex_WheelBaseAxle16ToAxle17" 25 "TrailerGeometricDataIndex_WheelBaseAxle15ToAxle16" 24 "TrailerGeometricDataIndex_WheelBaseAxle14ToAxle15" 23 "TrailerGeometricDataIndex_WheelBaseAxle13ToAxle14" 22 "TrailerGeometricDataIndex_WheelBaseAxle12ToAxle13" 21 "TrailerGeometricDataIndex_WheelBaseAxle11ToAxle12" 20 "TrailerGeometricDataIndex_WheelBaseAxle10ToAxle11" 19 "TrailerGeometricDataIndex_WheelBaseAxle9ToAxle10" 18 "TrailerGeometricDataIndex_WheelBaseAxle8ToAxle9" 17 "TrailerGeometricDataIndex_WheelBaseAxle7ToAxle8" 16 "TrailerGeometricDataIndex_WheelBaseAxle6ToAxle7" 15 "TrailerGeometricDataIndex_WheelBaseAxle5ToAxle6" 14 "TrailerGeometricDataIndex_WheelBaseAxle4ToAxle5" 13 "TrailerGeometricDataIndex_WheelBaseAxle3ToAxle4" 12 "TrailerGeometricDataIndex_WheelBaseAxle2ToAxle3" 11 "TrailerGeometricDataIndex_WheelBaseAxle1ToAxle2" 10 "TrailerGeometricDataIndex_AxleNumberOfLiftAxle5" 9 "TrailerGeometricDataIndex_AxleNumberOfLiftAxle4" 8 "TrailerGeometricDataIndex_AxleNumberOfLiftAxle3" 7 "TrailerGeometricDataIndex_AxleNumberOfLiftAxle2" 6 "TrailerGeometricDataIndex_AxleNumberOfLiftAxle1" 5 "TrailerGeometricDataIndex_NumberOfLiftAxles" 4 "TrailerGeometricDataIndex_NumberOfFrontAxles" 3 "TrailerGeometricDataIndex_NumberOfAxles" 2 "TrailerGeometricDataIndex_TrackWidth" 1 "TrailerGeometricDataIndex_DistanceCouplingToAxle1" 0 "TrailerGeometricDataIndex_TypeOfTrailer" ;
VAL_ 906 Trailer2GeometricData_Index_ISig 255 "TrailerGeometricDataIndex_NotAvailable" 254 "TrailerGeometricDataIndex_Error" 38 "TrailerGeometricDataIndex_TrailerHeightRear" 37 "TrailerGeometricDataIndex_ChassisHeight" 36 "TrailerGeometricDataIndex_TrailerHeightFront" 35 "TrailerGeometricDataIndex_LoadingHeightFront" 34 "TrailerGeometricDataIndex_LoadingHeightRear" 33 "TrailerGeometricDataIndex_CouplingHeight2" 32 "TrailerGeometricDataIndex_CouplingHeight1" 31 "TrailerGeometricDataIndex_TotalLengthOfTrailer" 30 "TrailerGeometricDataIndex_DistanceFirstToSecondCouplingPoint" 29 "TrailerGeometricDataIndex_WheelBaseAxle19ToAxle20" 28 "TrailerGeometricDataIndex_WheelBaseAxle18ToAxle19" 27 "TrailerGeometricDataIndex_WheelBaseAxle17ToAxle18" 26 "TrailerGeometricDataIndex_WheelBaseAxle16ToAxle17" 25 "TrailerGeometricDataIndex_WheelBaseAxle15ToAxle16" 24 "TrailerGeometricDataIndex_WheelBaseAxle14ToAxle15" 23 "TrailerGeometricDataIndex_WheelBaseAxle13ToAxle14" 22 "TrailerGeometricDataIndex_WheelBaseAxle12ToAxle13" 21 "TrailerGeometricDataIndex_WheelBaseAxle11ToAxle12" 20 "TrailerGeometricDataIndex_WheelBaseAxle10ToAxle11" 19 "TrailerGeometricDataIndex_WheelBaseAxle9ToAxle10" 18 "TrailerGeometricDataIndex_WheelBaseAxle8ToAxle9" 17 "TrailerGeometricDataIndex_WheelBaseAxle7ToAxle8" 16 "TrailerGeometricDataIndex_WheelBaseAxle6ToAxle7" 15 "TrailerGeometricDataIndex_WheelBaseAxle5ToAxle6" 14 "TrailerGeometricDataIndex_WheelBaseAxle4ToAxle5" 13 "TrailerGeometricDataIndex_WheelBaseAxle3ToAxle4" 12 "TrailerGeometricDataIndex_WheelBaseAxle2ToAxle3" 11 "TrailerGeometricDataIndex_WheelBaseAxle1ToAxle2" 10 "TrailerGeometricDataIndex_AxleNumberOfLiftAxle5" 9 "TrailerGeometricDataIndex_AxleNumberOfLiftAxle4" 8 "TrailerGeometricDataIndex_AxleNumberOfLiftAxle3" 7 "TrailerGeometricDataIndex_AxleNumberOfLiftAxle2" 6 "TrailerGeometricDataIndex_AxleNumberOfLiftAxle1" 5 "TrailerGeometricDataIndex_NumberOfLiftAxles" 4 "TrailerGeometricDataIndex_NumberOfFrontAxles" 3 "TrailerGeometricDataIndex_NumberOfAxles" 2 "TrailerGeometricDataIndex_TrackWidth" 1 "TrailerGeometricDataIndex_DistanceCouplingToAxle1" 0 "TrailerGeometricDataIndex_TypeOfTrailer" ;
VAL_ 906 Trailer4GeometricData_Index_ISig 255 "TrailerGeometricDataIndex_NotAvailable" 254 "TrailerGeometricDataIndex_Error" 38 "TrailerGeometricDataIndex_TrailerHeightRear" 37 "TrailerGeometricDataIndex_ChassisHeight" 36 "TrailerGeometricDataIndex_TrailerHeightFront" 35 "TrailerGeometricDataIndex_LoadingHeightFront" 34 "TrailerGeometricDataIndex_LoadingHeightRear" 33 "TrailerGeometricDataIndex_CouplingHeight2" 32 "TrailerGeometricDataIndex_CouplingHeight1" 31 "TrailerGeometricDataIndex_TotalLengthOfTrailer" 30 "TrailerGeometricDataIndex_DistanceFirstToSecondCouplingPoint" 29 "TrailerGeometricDataIndex_WheelBaseAxle19ToAxle20" 28 "TrailerGeometricDataIndex_WheelBaseAxle18ToAxle19" 27 "TrailerGeometricDataIndex_WheelBaseAxle17ToAxle18" 26 "TrailerGeometricDataIndex_WheelBaseAxle16ToAxle17" 25 "TrailerGeometricDataIndex_WheelBaseAxle15ToAxle16" 24 "TrailerGeometricDataIndex_WheelBaseAxle14ToAxle15" 23 "TrailerGeometricDataIndex_WheelBaseAxle13ToAxle14" 22 "TrailerGeometricDataIndex_WheelBaseAxle12ToAxle13" 21 "TrailerGeometricDataIndex_WheelBaseAxle11ToAxle12" 20 "TrailerGeometricDataIndex_WheelBaseAxle10ToAxle11" 19 "TrailerGeometricDataIndex_WheelBaseAxle9ToAxle10" 18 "TrailerGeometricDataIndex_WheelBaseAxle8ToAxle9" 17 "TrailerGeometricDataIndex_WheelBaseAxle7ToAxle8" 16 "TrailerGeometricDataIndex_WheelBaseAxle6ToAxle7" 15 "TrailerGeometricDataIndex_WheelBaseAxle5ToAxle6" 14 "TrailerGeometricDataIndex_WheelBaseAxle4ToAxle5" 13 "TrailerGeometricDataIndex_WheelBaseAxle3ToAxle4" 12 "TrailerGeometricDataIndex_WheelBaseAxle2ToAxle3" 11 "TrailerGeometricDataIndex_WheelBaseAxle1ToAxle2" 10 "TrailerGeometricDataIndex_AxleNumberOfLiftAxle5" 9 "TrailerGeometricDataIndex_AxleNumberOfLiftAxle4" 8 "TrailerGeometricDataIndex_AxleNumberOfLiftAxle3" 7 "TrailerGeometricDataIndex_AxleNumberOfLiftAxle2" 6 "TrailerGeometricDataIndex_AxleNumberOfLiftAxle1" 5 "TrailerGeometricDataIndex_NumberOfLiftAxles" 4 "TrailerGeometricDataIndex_NumberOfFrontAxles" 3 "TrailerGeometricDataIndex_NumberOfAxles" 2 "TrailerGeometricDataIndex_TrackWidth" 1 "TrailerGeometricDataIndex_DistanceCouplingToAxle1" 0 "TrailerGeometricDataIndex_TypeOfTrailer" ;
VAL_ 906 Trailer1GeometricData_Index_ISig 255 "TrailerGeometricDataIndex_NotAvailable" 254 "TrailerGeometricDataIndex_Error" 38 "TrailerGeometricDataIndex_TrailerHeightRear" 37 "TrailerGeometricDataIndex_ChassisHeight" 36 "TrailerGeometricDataIndex_TrailerHeightFront" 35 "TrailerGeometricDataIndex_LoadingHeightFront" 34 "TrailerGeometricDataIndex_LoadingHeightRear" 33 "TrailerGeometricDataIndex_CouplingHeight2" 32 "TrailerGeometricDataIndex_CouplingHeight1" 31 "TrailerGeometricDataIndex_TotalLengthOfTrailer" 30 "TrailerGeometricDataIndex_DistanceFirstToSecondCouplingPoint" 29 "TrailerGeometricDataIndex_WheelBaseAxle19ToAxle20" 28 "TrailerGeometricDataIndex_WheelBaseAxle18ToAxle19" 27 "TrailerGeometricDataIndex_WheelBaseAxle17ToAxle18" 26 "TrailerGeometricDataIndex_WheelBaseAxle16ToAxle17" 25 "TrailerGeometricDataIndex_WheelBaseAxle15ToAxle16" 24 "TrailerGeometricDataIndex_WheelBaseAxle14ToAxle15" 23 "TrailerGeometricDataIndex_WheelBaseAxle13ToAxle14" 22 "TrailerGeometricDataIndex_WheelBaseAxle12ToAxle13" 21 "TrailerGeometricDataIndex_WheelBaseAxle11ToAxle12" 20 "TrailerGeometricDataIndex_WheelBaseAxle10ToAxle11" 19 "TrailerGeometricDataIndex_WheelBaseAxle9ToAxle10" 18 "TrailerGeometricDataIndex_WheelBaseAxle8ToAxle9" 17 "TrailerGeometricDataIndex_WheelBaseAxle7ToAxle8" 16 "TrailerGeometricDataIndex_WheelBaseAxle6ToAxle7" 15 "TrailerGeometricDataIndex_WheelBaseAxle5ToAxle6" 14 "TrailerGeometricDataIndex_WheelBaseAxle4ToAxle5" 13 "TrailerGeometricDataIndex_WheelBaseAxle3ToAxle4" 12 "TrailerGeometricDataIndex_WheelBaseAxle2ToAxle3" 11 "TrailerGeometricDataIndex_WheelBaseAxle1ToAxle2" 10 "TrailerGeometricDataIndex_AxleNumberOfLiftAxle5" 9 "TrailerGeometricDataIndex_AxleNumberOfLiftAxle4" 8 "TrailerGeometricDataIndex_AxleNumberOfLiftAxle3" 7 "TrailerGeometricDataIndex_AxleNumberOfLiftAxle2" 6 "TrailerGeometricDataIndex_AxleNumberOfLiftAxle1" 5 "TrailerGeometricDataIndex_NumberOfLiftAxles" 4 "TrailerGeometricDataIndex_NumberOfFrontAxles" 3 "TrailerGeometricDataIndex_NumberOfAxles" 2 "TrailerGeometricDataIndex_TrackWidth" 1 "TrailerGeometricDataIndex_DistanceCouplingToAxle1" 0 "TrailerGeometricDataIndex_TypeOfTrailer" ;
VAL_ 698 Trailer1LiftAxle2Pos_ISig_5 3 "TrailerLiftAxlePos_NotAvailable" 2 "TrailerLiftAxlePos_Error" 1 "TrailerLiftAxlePos_AxleLifted" 0 "TrailerLiftAxlePos_AxleDown" ;
VAL_ 698 Trailer5LiftAxle1Pos_ISig_5 3 "TrailerLiftAxlePos_NotAvailable" 2 "TrailerLiftAxlePos_Error" 1 "TrailerLiftAxlePos_AxleLifted" 0 "TrailerLiftAxlePos_AxleDown" ;
VAL_ 698 MaxEngineCoolingCapacity_Rqst 3 "InactiveActive_NotAvailable" 2 "InactiveActive_Error" 1 "InactiveActive_Active" 0 "InactiveActive_Inactive" ;
VAL_ 698 Trailer2LiftAxle2Pos_ISig_5 3 "TrailerLiftAxlePos_NotAvailable" 2 "TrailerLiftAxlePos_Error" 1 "TrailerLiftAxlePos_AxleLifted" 0 "TrailerLiftAxlePos_AxleDown" ;
VAL_ 698 Trailer4LiftAxle2Pos_ISig_5 3 "TrailerLiftAxlePos_NotAvailable" 2 "TrailerLiftAxlePos_Error" 1 "TrailerLiftAxlePos_AxleLifted" 0 "TrailerLiftAxlePos_AxleDown" ;
VAL_ 698 Trailer2LiftAxle1Pos_ISig_5 3 "TrailerLiftAxlePos_NotAvailable" 2 "TrailerLiftAxlePos_Error" 1 "TrailerLiftAxlePos_AxleLifted" 0 "TrailerLiftAxlePos_AxleDown" ;
VAL_ 698 Trailer1LiftAxle1Pos_ISig_5 3 "TrailerLiftAxlePos_NotAvailable" 2 "TrailerLiftAxlePos_Error" 1 "TrailerLiftAxlePos_AxleLifted" 0 "TrailerLiftAxlePos_AxleDown" ;
VAL_ 698 RainSensorStatus 7 "RainSensorStatus_NotAvailable" 6 "RainSensorStatus_Error" 5 "RainSensorStatus_Spare3" 4 "RainSensorStatus_Spare2" 3 "RainSensorStatus_Spare1" 2 "RainSensorStatus_Activated" 1 "RainSensorStatus_Enabled" 0 "RainSensorStatus_Disabled" ;
VAL_ 698 Trailer4LiftAxle1Pos_ISig_5 3 "TrailerLiftAxlePos_NotAvailable" 2 "TrailerLiftAxlePos_Error" 1 "TrailerLiftAxlePos_AxleLifted" 0 "TrailerLiftAxlePos_AxleDown" ;
VAL_ 698 Trailer3LiftAxle2Pos_ISig_5 3 "TrailerLiftAxlePos_NotAvailable" 2 "TrailerLiftAxlePos_Error" 1 "TrailerLiftAxlePos_AxleLifted" 0 "TrailerLiftAxlePos_AxleDown" ;
VAL_ 698 Trailer5LiftAxle2Pos_ISig_5 3 "TrailerLiftAxlePos_NotAvailable" 2 "TrailerLiftAxlePos_Error" 1 "TrailerLiftAxlePos_AxleLifted" 0 "TrailerLiftAxlePos_AxleDown" ;
VAL_ 698 Trailer3LiftAxle1Pos_ISig_5 3 "TrailerLiftAxlePos_NotAvailable" 2 "TrailerLiftAxlePos_Error" 1 "TrailerLiftAxlePos_AxleLifted" 0 "TrailerLiftAxlePos_AxleDown" ;
VAL_ 157 ChangeKneelACK_ISig_5 3 "ChangeKneelACK_NotAvailable" 2 "ChangeKneelACK_Error" 1 "ChangeKneelACK_ChangeAcknowledged" 0 "ChangeKneelACK_NoAction" ;
VAL_ 157 InteriorLightDimming_rqst 31 "InteriorLightDimming_rqst_NotAvailable" 30 "InteriorLightDimming_rqst_Error" 15 "InteriorLightDimming_rqst_DimDownContinously" 14 "InteriorLightDimming_rqst_DimUpContinously" 13 "InteriorLightDimming_rqst_Position13" 12 "InteriorLightDimming_rqst_Position12" 11 "InteriorLightDimming_rqst_Position11" 10 "InteriorLightDimming_rqst_Position10" 9 "InteriorLightDimming_rqst_Position9" 8 "InteriorLightDimming_rqst_Position8" 7 "InteriorLightDimming_rqst_Position7" 6 "InteriorLightDimming_rqst_Position6" 5 "InteriorLightDimming_rqst_Position5" 4 "InteriorLightDimming_rqst_Position4" 3 "InteriorLightDimming_rqst_Position3" 2 "InteriorLightDimming_rqst_Position2" 1 "InteriorLightDimming_rqst_Position1" 0 "InteriorLightDimming_rqst_NoMovement" ;
VAL_ 157 DirectionIndication_cmd 15 "DirectionIndication_cmd_NotAvailable" 14 "DirectionIndication_cmd_Error" 13 "DirectionIndication_cmd_ActBothTruckTrailerTelltalesFaultInd" 12 "DirectionIndication_cmd_ActBothTruckTelltalesFaultInd" 11 "DirectionIndication_cmd_ActRghtTruckRghtTrailTelltaleFaultInd" 10 "DirectionIndication_cmd_ActLeftTruckLeftTrailTelltaleFaultInd" 9 "DirectionIndication_cmd_ActRghtTruckTelltaleFaultInd" 8 "DirectionIndication_cmd_ActLeftTruckTelltaleFaultInd" 7 "DirectionIndication_cmd_ActivateBothTruckAndTrailer_Hazard" 6 "DirectionIndication_cmd_ActivateBothTruck_Hazard" 5 "DirectionIndication_cmd_ActivateRightTruckAndTrailer" 4 "DirectionIndication_cmd_ActivateLeftTruckAndTrailer" 3 "DirectionIndication_cmd_ActivateRightTruck" 2 "DirectionIndication_cmd_ActivateLeftTruck" 1 "DirectionIndication_cmd_ActivateLow" 0 "DirectionIndication_cmd_Deactivate" ;
VAL_ 157 RampLevelRequestACK_ISig_5 3 "ChangeRequest2Bit_NotAvailable" 2 "ChangeRequest2Bit_Error" 1 "ChangeRequest2Bit_Change" 0 "ChangeRequest2Bit_TakeNoAction" ;
VAL_ 157 LoadDistributionSelected_ISig_5 15 "LoadDistributionSelected_NotAvailable" 14 "LoadDistributionSelected_Error" 13 "LoadDistributionSelected_Reserved_05" 12 "LoadDistributionSelected_Reserved_04" 11 "LoadDistributionSelected_Reserved_03" 10 "LoadDistributionSelected_TractionHelp2" 9 "LoadDistributionSelected_StartingHelp2" 8 "LoadDistributionSelected_VariableAxleLoad" 7 "LoadDistributionSelected_NoLoadDistribution" 6 "LoadDistributionSelected_TractionHelpInterDiff" 5 "LoadDistributionSelected_StartingHelpInterDiff" 4 "LoadDistributionSelected_AlternativeLoad" 3 "LoadDistributionSelected_TractionHelp" 2 "LoadDistributionSelected_StartingHelp" 1 "LoadDistributionSelected_OptimisedTraction" 0 "LoadDistributionSelected_NormalLoad" ;
VAL_ 157 HeightAdjustmentAllowed_ISig_5 3 "FalseTrue_NotAvaiable" 2 "FalseTrue_Error" 1 "FalseTrue_True" 0 "FalseTrue_False" ;
VAL_ 157 AirDumpStatus_ISig_5 7 "AirDumpStatus_NotAvailable" 6 "AirDumpStatus_Error" 5 "AirDumpStatus_Spare2" 4 "AirDumpStatus_Spare1" 3 "AirDumpStatus_Denied" 2 "AirDumpStatus_ActiveReached" 1 "AirDumpStatus_ActiveNotReached" 0 "AirDumpStatus_Inactive" ;
VAL_ 157 KneelingStatusHMI_ISig_5 3 "KneelingStatusHMI_NotAvailable" 2 "KneelingStatusHMI_Error" 1 "KneelingStatusHMI_Active" 0 "KneelingStatusHMI_Inactive" ;
VAL_ 157 BackToDriveReqACK_ISig_5 3 "BackToDriveReqACK_NotAvailable" 2 "BackToDriveReqACK_Error" 1 "BackToDriveReqACK_ChangeAcknowledged" 0 "BackToDriveReqACK_TakNoAction" ;
VAL_ 157 LoadDistributionFuncSelected_ISi 15 "LoadDistributionFuncSelected_NotAvaiable" 14 "LoadDistributionFuncSelected_ErrorIndicator" 13 "LoadDistributionFuncSelected_SpareValue_08" 12 "LoadDistributionFuncSelected_SpareValue_07" 11 "LoadDistributionFuncSelected_SpareValue_06" 10 "LoadDistributionFuncSelected_SpareValue_05" 9 "LoadDistributionFuncSelected_SpareValue_04" 8 "LoadDistributionFuncSelected_SpareValue_03" 7 "LoadDistributionFuncSelected_SpareValue_02" 6 "LoadDistributionFuncSelected_MaximumTractionStartingHelp" 5 "LoadDistributionFuncSelected_VariableAxleLoad" 4 "LoadDistributionFuncSelected_NoLoadDistribution" 3 "LoadDistributionFuncSelected_AlternativeLoad" 2 "LoadDistributionFuncSelected_MaximumTractionTractionHelp" 1 "LoadDistributionFuncSelected_OptimisedTraction" 0 "LoadDistributionFuncSelected_NormalLoad" ;
VAL_ 157 StopLevelChangeAck_ISig_5 3 "StopLevelChangeStatus_NotAvailable" 2 "StopLevelChangeStatus_ErrorIndicator" 1 "StopLevelChangeStatus_LevelChangedStopped" 0 "StopLevelChangeStatus_NoStopRequest" ;
VAL_ 157 RampLevelStorageAck_ISig_5 3 "StorageAck_NotAvaiable" 2 "StorageAck_Error" 1 "StorageAck_ChangeAcknowledged" 0 "StorageAck_TakeNoAction" ;
VAL_ 157 FerryFunctionSwitchChangeACK_ISi 3 "Ack2Bit_NotAvailable" 2 "Ack2Bit_Error" 1 "Ack2Bit_ChangeAcknowledged" 0 "Ack2Bit_NoAction" ;
VAL_ 157 LiftAxle1RequestResponse 15 "LiftAxleRequestResponse_NotAvailable" 14 "LiftAxleRequestResponse_Error" 13 "LiftAxleRequestResponse_Spare8" 12 "LiftAxleRequestResponse_Spare7" 11 "LiftAxleRequestResponse_Spare6" 10 "LiftAxleRequestResponse_Spare5" 9 "LiftAxleRequestResponse_Spare4" 8 "LiftAxleRequestResponse_Spare3" 7 "LiftAxleRequestResponse_Spare2" 6 "LiftAxleRequestResponse_Spare1" 5 "LiftAxleRequestResponse_LowerDeniedRASEC" 4 "LiftAxleRequestResponse_LiftDeniedVersatile" 3 "LiftAxleRequestResponse_LiftDeniedInterAxleClutchEngaged" 2 "LiftAxleRequestResponse_LiftDeniedRearOverload" 1 "LiftAxleRequestResponse_LiftDeniedFrontOverload" 0 "LiftAxleRequestResponse_NoIndication" ;
VAL_ 157 ECSStandbyAllowed_ISig_5 3 "FalseTrue_NotAvaiable" 2 "FalseTrue_Error" 1 "FalseTrue_True" 0 "FalseTrue_False" ;
VAL_ 157 RideHeightStorageAck_ISig_5 3 "StorageAck_NotAvaiable" 2 "StorageAck_Error" 1 "StorageAck_ChangeAcknowledged" 0 "StorageAck_TakeNoAction" ;
VAL_ 157 IntLightMode_CoreRqst_EventFlag 1 "EventFlag_High" 0 "EventFlag_Low" ;
VAL_ 157 IntLightMode_CoreRqst_IL_Mode 7 "IL_ModeReq_NotAvailable" 6 "IL_ModeReq_ErrorIndicator" 5 "IL_ModeReq_NonHMIModeMax" 4 "IL_ModeReq_NonHMIModeResting" 3 "IL_ModeReq_Max" 2 "IL_ModeReq_Resting" 1 "IL_ModeReq_NightDriving" 0 "IL_ModeReq_OFF" ;
VAL_ 1209 LNGRestrictionStatus_Spare4_ISig 1 "InactiveActive1b_Active" 0 "InactiveActive1b_Inactive" ;
VAL_ 1209 LNGRestrictionStatus_V1Closed_IS 1 "InactiveActive1b_Active" 0 "InactiveActive1b_Inactive" ;
VAL_ 1209 LNGRestrictionStatus_Spare3_ISig 1 "InactiveActive1b_Active" 0 "InactiveActive1b_Inactive" ;
VAL_ 1209 LngTank2WarnStat_ISig_5 3 "OkEmpty_NotAvailable" 2 "OkEmpty_Error" 1 "OkEmpty_Empty" 0 "OkEmpty_OK" ;
VAL_ 1209 LNGRestrictionStatus_Spare2_ISig 1 "InactiveActive1b_Active" 0 "InactiveActive1b_Inactive" ;
VAL_ 1209 LngSystemReadinessStat_ISig_5 7 "LngSystemReadinessStat_NotAvailable" 6 "LngSystemReadinessStat_Error" 5 "LngSystemReadinessStat_Spare2" 4 "LngSystemReadinessStat_Spare1" 3 "LngSystemReadinessStat_LNGSystemReady" 2 "LngSystemReadinessStat_LNGInLimpingMode" 1 "LngSystemReadinessStat_LNGSystemWarmingUpPleaseWait" 0 "LngSystemReadinessStat_LNGSystemOff" ;
VAL_ 1209 LNGOperatorInducementReason_ISig 7 "LNGOperatorInducementReason_NotAvailable" 6 "LNGOperatorInducementReason_Error" 5 "LNGOperatorInducementReason_Spare2" 4 "LNGOperatorInducementReason_Spare1" 3 "LNGOperatorInducementReason_IncorrectConsumption" 2 "LNGOperatorInducementReason_GasSupplyMalfunction" 1 "LNGOperatorInducementReason_LNGLevelLow" 0 "LNGOperatorInducementReason_OK" ;
VAL_ 1209 LNGRestrictionStatus_Spare1_ISig 1 "InactiveActive1b_Active" 0 "InactiveActive1b_Inactive" ;
VAL_ 1209 LNGRestrictionStatus_V2Closed_IS 1 "InactiveActive1b_Active" 0 "InactiveActive1b_Inactive" ;
VAL_ 1209 LngTank1WarnStat_ISig_5 3 "OkEmpty_NotAvailable" 2 "OkEmpty_Error" 1 "OkEmpty_Empty" 0 "OkEmpty_OK" ;
VAL_ 1209 LNGRestrictionStatus_SInfo_ISig_ 3 "SignalInfo2bitType_NotAvailable" 2 "SignalInfo2bitType_ErrorIndication" 1 "SignalInfo2bitType_Spare" 0 "SignalInfo2bitType_Valid" ;
VAL_ 1209 LngGspWarnStat_ISig_5 3 "OkPrepareToDerate_NotAvailable" 2 "OkPrepareToDerate_Error" 1 "OkPrepareToDerate_PrepareToDerate" 0 "OkPrepareToDerate_Ok" ;
VAL_ 1208 BatterySOCTLWeak_ISig_5 15 "BatteryTrustLevel_NotAvailable" 14 "BatteryTrustLevel_Error" 13 "BatteryTrustLevel_Spare9" 12 "BatteryTrustLevel_Spare8" 11 "BatteryTrustLevel_Spare7" 10 "BatteryTrustLevel_Spare6" 9 "BatteryTrustLevel_Spare5" 8 "BatteryTrustLevel_Spare4" 7 "BatteryTrustLevel_Spare3" 6 "BatteryTrustLevel_Spare2" 5 "BatteryTrustLevel_Spare1" 4 "BatteryTrustLevel_NominalPlus15PercentAndAbove" 3 "BatteryTrustLevel_NominalPlus10Percent" 2 "BatteryTrustLevel_NominalPlus5Percent" 1 "BatteryTrustLevel_NominalAccuracy" 0 "BatteryTrustLevel_NotInitialized" ;
SIG_GROUP_ 1237 TruckTPMTireInfo_sg 1 : TruckTPMTireInfo_TireId TruckTPMTireInfo_Pressure TruckTPMTireInfo_LeakageWarn TruckTPMTireInfo_Battery TruckTPMTireInfo_PresWarn TruckTPMTireInfo_RefPres TruckTPMTireInfo_Temperature TruckTPMTireInfo_Active;
SIG_GROUP_ 1234 Trail2TPMTireInfo_sg 1 : Trail2TPMTireInfo_PresWarn Trail2TPMTireInfo_Pressure Trail2TPMTireInfo_TireId Trail2TPMTireInfo_LeakageWarn Trail2TPMTireInfo_Temperature Trail2TPMTireInfo_Battery Trail2TPMTireInfo_Active Trail2TPMTireInfo_RefPres;
SIG_GROUP_ 1231 Trail1TPMTireInfo_sg 1 : Trail1TPMTireInfo_LeakageWarn Trail1TPMTireInfo_Temperature Trail1TPMTireInfo_TireId Trail1TPMTireInfo_RefPres Trail1TPMTireInfo_PresWarn Trail1TPMTireInfo_Battery Trail1TPMTireInfo_Active Trail1TPMTireInfo_Pressure;
SIG_GROUP_ 1231 TPMPosOfWMResponse_sg 1 : TPMPosOfWMResponse_Status TPMPosOfWMResponse_TireId TPMPosOfWMResponse_VehiclePos;
SIG_GROUP_ 1403 TrckTPMThresCfg_sg 1 : TrckTPMThresCfg_AxleNr TrckTPMThresCfg_UnderPres TrckTPMThresCfg_OverPres TrckTPMThresCfg_ExtOverPres TrckTPMThresCfg_ExtUnderPres;
SIG_GROUP_ 1403 TruckTPMAxleTireCnfg_sg 1 : TruckTPMAxleTireCnfg_Axle5 TruckTPMAxleTireCnfg_Axle3 TruckTPMAxleTireCnfg_Axle1 TruckTPMAxleTireCnfg_Axle4 TruckTPMAxleTireCnfg_Axle2;
SIG_GROUP_ 1402 Trail2TPMAxleTireCnfg_sg 1 : Trail2TPMAxleTireCnfg_Axle1 Trail2TPMAxleTireCnfg_Axle3 Trail2TPMAxleTireCnfg_Axle2 Trail2TPMAxleTireCnfg_Axle4 Trail2TPMAxleTireCnfg_Axle5;
SIG_GROUP_ 1402 Trail2TPMThresCfg_sg 1 : Trail2TPMThresCfg_UnderPres Trail2TPMThresCfg_ExtUnderPres Trail2TPMThresCfg_OverPres Trail2TPMThresCfg_AxleNr Trail2TPMThresCfg_ExtOverPres;
SIG_GROUP_ 1401 Trail1TPMAxleTireCnfg_sg 1 : Trail1TPMAxleTireCnfg_Axle4 Trail1TPMAxleTireCnfg_Axle5 Trail1TPMAxleTireCnfg_Axle3 Trail1TPMAxleTireCnfg_Axle2 Trail1TPMAxleTireCnfg_Axle1;
SIG_GROUP_ 1401 Trail1TPMThresCfg_sg 1 : Trail1TPMThresCfg_UnderPres Trail1TPMThresCfg_OverPres Trail1TPMThresCfg_ExtOverPres Trail1TPMThresCfg_AxleNr Trail1TPMThresCfg_ExtUnderPres;
SIG_GROUP_ 2566909713 Trail4TPMThresCfg_sg 1 : Trail4TPMThresCfg_AxleNr Trail4TPMThresCfg_ExtOverPres Trail4TPMThresCfg_ExtUnderPres Trail4TPMThresCfg_OverPres Trail4TPMThresCfg_UnderPres;
SIG_GROUP_ 2566901521 Trail5TPMThresCfg_sg 1 : Trail5TPMThresCfg_OverPres Trail5TPMThresCfg_AxleNr Trail5TPMThresCfg_ExtOverPres Trail5TPMThresCfg_ExtUnderPres Trail5TPMThresCfg_UnderPres;
SIG_GROUP_ 2566893329 Trail3TPMThresCfg_sg 1 : Trail3TPMThresCfg_UnderPres Trail3TPMThresCfg_ExtUnderPres Trail3TPMThresCfg_ExtOverPres Trail3TPMThresCfg_AxleNr Trail3TPMThresCfg_OverPres;
SIG_GROUP_ 2566885137 Trail5TPMAxleTireCnfg_sg 1 : Trail5TPMAxleTireCnfg_Axle3 Trail5TPMAxleTireCnfg_Axle4 Trail5TPMAxleTireCnfg_Axle2 Trail5TPMAxleTireCnfg_Axle1 Trail5TPMAxleTireCnfg_Axle5;
SIG_GROUP_ 2566885137 Trail4TPMAxleTireCnfg_sg 1 : Trail4TPMAxleTireCnfg_Axle1 Trail4TPMAxleTireCnfg_Axle5 Trail4TPMAxleTireCnfg_Axle4 Trail4TPMAxleTireCnfg_Axle2 Trail4TPMAxleTireCnfg_Axle3;
SIG_GROUP_ 2566885137 Trail3TPMAxleTireCnfg_sg 1 : Trail3TPMAxleTireCnfg_Axle3 Trail3TPMAxleTireCnfg_Axle2 Trail3TPMAxleTireCnfg_Axle5 Trail3TPMAxleTireCnfg_Axle1 Trail3TPMAxleTireCnfg_Axle4;
SIG_GROUP_ 2566876945 Trail3TPMTireInfo_sg 1 : Trail3TPMTireInfo_RefPres Trail3TPMTireInfo_Battery Trail3TPMTireInfo_Temperature Trail3TPMTireInfo_Pressure Trail3TPMTireInfo_TireId Trail3TPMTireInfo_PresWarn Trail3TPMTireInfo_LeakageWarn Trail3TPMTireInfo_Active;
SIG_GROUP_ 2566868753 Trail5TPMTireInfo_sg 1 : Trail5TPMTireInfo_TireId Trail5TPMTireInfo_LeakageWarn Trail5TPMTireInfo_RefPres Trail5TPMTireInfo_Pressure Trail5TPMTireInfo_PresWarn Trail5TPMTireInfo_Temperature Trail5TPMTireInfo_Battery Trail5TPMTireInfo_Active;
SIG_GROUP_ 2566860305 Trail4TPMTireInfo_sg 1 : Trail4TPMTireInfo_LeakageWarn Trail4TPMTireInfo_Battery Trail4TPMTireInfo_RefPres Trail4TPMTireInfo_Pressure Trail4TPMTireInfo_Active Trail4TPMTireInfo_TireId Trail4TPMTireInfo_Temperature Trail4TPMTireInfo_PresWarn;
SIG_GROUP_ 395 XPRGSystemCap_sg_ISig_5 1 : XPRGSystemCap_AllowedInfInhibit_ XPRGSystemCap_Priority_ISig_5 XPRGSystemCap_AllowedPBApp_ISig_ XPRGSystemCap_AllowedRelInhibit_ XPRGSystemCap_CRC_ISig_5 XPRGSystemCap_AllowedInflation_I XPRGSystemCap_AllowedGradCtrlTl_ XPRGSystemCap_AllowedGradCtrlTc_ XPRGSystemCap_AllowedPBRel_ISig_ XPRGSystemCap_AllowedDeflation_I XPRGSystemCap_SqC_ISig_5;
SIG_GROUP_ 907 Trailer5GeometricData_sg_ISig_5 1 : Trailer5GeometricData_Index_ISig Trailer5GeometricData_Content_IS;
SIG_GROUP_ 906 Trailer4GeometricData_sg_ISig_5 1 : Trailer4GeometricData_Index_ISig Trailer4GeometricData_Content_IS;
SIG_GROUP_ 906 Trailer3GeometricData_sg_ISig_5 1 : Trailer3GeometricData_Index_ISig Trailer3GeometricData_Content_IS;
SIG_GROUP_ 906 Trailer1GeometricData_sg_ISig_5 1 : Trailer1GeometricData_Content_IS Trailer1GeometricData_Index_ISig;
SIG_GROUP_ 906 Trailer2GeometricData_sg_ISig_5 1 : Trailer2GeometricData_Index_ISig Trailer2GeometricData_Content_IS;
SIG_GROUP_ 157 IntLightMode_CoreRqst_sg 1 : IntLightMode_CoreRqst_EventFlag IntLightMode_CoreRqst_IL_Mode;
SIG_GROUP_ 1209 LNGRestrictionStatus_sg_ISig_5 1 : LNGRestrictionStatus_Spare4_ISig LNGRestrictionStatus_V1Closed_IS LNGRestrictionStatus_Spare3_ISig LNGRestrictionStatus_Spare2_ISig LNGRestrictionStatus_Spare1_ISig LNGRestrictionStatus_V2Closed_IS LNGRestrictionStatus_SInfo_ISig_;
